VERSION ""

NS_ :

BS_:

BU_: SGW RFHM MPAD IPC GNMM EVCU2 ESL ECM DTCM DMSM BSM BCM AGSM ADCAM

BO_ 1426 VDCM_HMI: 32 EVCU2
 SG_ VDCM_PopUpMessage5 : 55|3@0+ (1,0) [0|6] "" IPC
 SG_ EstRange : 18|11@0+ (1,0) [0|2046] "km"  SGW,IPC
 SG_ DC_EstChargeTime2 : 103|8@0+ (1,0) [0|254] "min"  SGW,IPC
 SG_ DC_EstChargeTime1 : 47|8@0+ (1,0) [0|254] "min"  SGW,IPC
 SG_ VDCM_PopUpMessage7 : 87|1@0+ (1,0) [0|1] "" IPC
 SG_ Est_Range_ChrgStopTime : 162|11@0+ (1,0) [0|2046] "km"  SGW
 SG_ Est_HVBatSOC_VDCM : 159|8@0+ (0.3922,0) [0|99.6188] "%"  SGW
 SG_ ServiceHVError : 126|1@0+ (1,0) [0|1] "" IPC
 SG_ ThermalRunaway_Alert : 107|1@0+ (1,0) [0|1] "" Vector__XXX
 SG_ MessageCounter_VDCM_HMI : 179|4@0+ (1,0) [0|15] "-"  IPC
 SG_ CRC_VDCM_HMI : 191|8@0+ (1,0) [0|255] "-"  IPC
 SG_ BatteryRunaway_Lamp_PT : 108|1@0+ (1,0) [0|1] "" BCM,IPC

BO_ 1853 HYBRID_RM_MOTORS_2: 32 EVCU2
 SG_ APM_OutputPower : 119|10@0+ (3,0) [0|3069] "W"  SGW
 SG_ APM_FailureReason : 151|6@0+ (1,0) [0|63] "" SGW
 SG_ APM_CtrlSts_Fbk : 145|4@0+ (1,0) [0|15] "" SGW

BO_ 1439 AFLM_A1: 32 BCM
 SG_ AFLM_Fault : 15|1@0+ (1,0) [0|1] "-"  IPC

BO_ 126 GLIWA_MCPA_RX: 8 SGW
 SG_ N_PDU : 7|64@0+ (1,0) [0|0] "" EVCU2

BO_ 123 GLIWA_MCPA_TX: 8 EVCU2
 SG_ N_PDU : 7|64@0+ (1,0) [0|0] "" SGW

BO_ 127 GLIWA_MCPB_RX: 8 SGW
 SG_ N_PDU : 7|64@0+ (1,0) [0|0] "" EVCU2

BO_ 124 GLIWA_MCPB_TX: 8 EVCU2
 SG_ N_PDU : 7|64@0+ (1,0) [0|0] "" SGW

BO_ 834 GLIWA_T1_TX: 8 ECM
 SG_ N_PDU : 7|64@0+ (1,0) [0|0] "" SGW

BO_ 835 GLIWA_T1_RX: 8 SGW
 SG_ N_PDU : 7|64@0+ (1,0) [0|0] "" ECM,EVCU2

BO_ 1462 CLIMATE_SCHEDULE_TBM: 32 SGW
 SG_ TBM_Submit_ClimateSchd2 : 4|1@0+ (1,0) [0|1] "-"  EVCU2
 SG_ TBM_Submit_ClimateSchd1 : 5|1@0+ (1,0) [0|1] "-"  EVCU2
 SG_ TBM_Enable_ClimateSchd2 : 6|1@0+ (1,0) [0|0] "-"  EVCU2
 SG_ TBM_Enable_ClimateSchd1 : 7|1@0+ (1,0) [0|0] "-"  EVCU2
 SG_ TBM_ClimateSchd2_Departure_Min : 11|4@0+ (5,0) [0|70] "min"  EVCU2
 SG_ TBM_ClimateSchd2_Departure_Hr : 31|5@0+ (1,0) [0|30] "Hours"  EVCU2
 SG_ TBM_ClimateSchd2_Day : 55|8@0+ (1,0) [0|254] "-"  EVCU2
 SG_ TBM_ClimateSchd1_Departure_Min : 15|4@0+ (5,0) [0|70] "min"  EVCU2
 SG_ TBM_ClimateSchd1_Departure_Hr : 23|5@0+ (1,0) [0|30] "Hours"  EVCU2
 SG_ TBM_ClimateSchd1_Day : 47|8@0+ (1,0) [0|254] "-"  EVCU2
 SG_ TBM_AllowClimateSchd2 : 1|2@0+ (1,0) [0|2] "-"  EVCU2
 SG_ TBM_AllowClimateSchd1 : 3|2@0+ (1,0) [0|2] "-"  EVCU2
 SG_ Climate_TBM_Cabin_Temp2 : 71|5@0+ (0.5,16) [16|31] "°C"  EVCU2
 SG_ Climate_TBM_Cabin_Temp1 : 39|5@0+ (0.5,16) [16|31] "°C"  EVCU2

BO_ 1471 CLIMATE_SCHEDULE_HU1: 32 SGW
 SG_ Submit_ClimateSchd2 : 4|1@0+ (1,0) [0|1] "-"  EVCU2
 SG_ Submit_ClimateSchd1 : 5|1@0+ (1,0) [0|1] "-"  EVCU2
 SG_ Enable_ClimateSchd2 : 6|1@0+ (1,0) [0|1] "-"  EVCU2
 SG_ Enable_ClimateSchd1 : 7|1@0+ (1,0) [0|1] "-"  EVCU2
 SG_ ClimateSchd2_Departure_Min : 11|4@0+ (5,0) [0|70] "min"  EVCU2
 SG_ ClimateSchd2_Departure_Hr : 31|5@0+ (1,0) [0|30] "Hours"  EVCU2
 SG_ ClimateSchd2_Day : 55|8@0+ (1,0) [0|254] "-"  EVCU2
 SG_ ClimateSchd1_Departure_Min : 15|4@0+ (5,0) [0|70] "min"  EVCU2
 SG_ ClimateSchd1_Departure_Hr : 23|5@0+ (1,0) [0|30] "Hours"  EVCU2
 SG_ ClimateSchd1_Day : 47|8@0+ (1,0) [0|254] "-"  EVCU2
 SG_ Climate_Cabin_Temp2 : 63|5@0+ (0.5,16) [16|31] "°C"  EVCU2
 SG_ Climate_Cabin_Temp1 : 39|5@0+ (0.5,16) [16|31] "°C"  EVCU2
 SG_ AllowClimateSchd2 : 1|2@0+ (1,0) [0|2] "-"  EVCU2
 SG_ AllowClimateSchd1 : 3|2@0+ (1,0) [0|2] "-"  EVCU2

BO_ 1468 CLIMATE_SCHEDULE_HCP1: 32 EVCU2
 SG_ Enable_ClimateSchd2_Sts : 6|1@0+ (1,0) [0|1] "-"  SGW
 SG_ Enable_ClimateSchd1_Sts : 7|1@0+ (1,0) [0|1] "-"  SGW
 SG_ ClimateSchd2_Departure_Min_Sts : 11|4@0+ (5,0) [0|70] "min"  SGW
 SG_ ClimateSchd2_Departure_Hr_Sts : 31|5@0+ (1,0) [0|30] "Hours"  SGW
 SG_ ClimateSchd2_Day_Sts : 55|8@0+ (1,0) [0|254] "-"  SGW
 SG_ ClimateSchd1_Departure_Min_Sts : 15|4@0+ (5,0) [0|70] "min"  SGW
 SG_ ClimateSchd1_Departure_Hr_Sts : 23|5@0+ (1,0) [0|30] "Hours"  SGW
 SG_ ClimateSchd1_Day_Sts : 47|8@0+ (1,0) [0|254] "-"  SGW
 SG_ Climate_Cabin_Temp2_Sts : 63|5@0+ (0.5,16) [16|31] "°C"  SGW
 SG_ Climate_Cabin_Temp1_Sts : 39|5@0+ (0.5,16) [16|31] "°C"  SGW
 SG_ AllowClimateSchd2_Sts : 1|2@0+ (1,0) [0|2] "-"  SGW
 SG_ AllowClimateSchd1_Sts : 3|2@0+ (1,0) [0|2] "-"  SGW

BO_ 105 VDCM_PWT3: 64 EVCU2
 SG_ T4_Sensor_Temp : 378|11@0+ (0.1,-40) [-40|164.7] "°C"  BCM
 SG_ LidOpeningAck : 7|2@0+ (1,0) [0|2] "" Vector__XXX
 SG_ LidClosingAck : 5|2@0+ (1,0) [0|2] "" Vector__XXX
 SG_ MessageCounter_VDCM_PWT3 : 435|4@0+ (1,0) [0|15] "-"  DTCM
 SG_ CRC_VDCM_PWT3 : 447|8@0+ (1,0) [0|255] "-"  DTCM

BO_ 1442 VDCM_HMI2: 64 EVCU2
 SG_ SugSpeedThreshold : 51|6@0+ (5,0) [0|315] "km/h"  Vector__XXX
 SG_ SugSpeedMin : 41|6@0+ (5,0) [0|315] "km/h"  Vector__XXX
 SG_ SugSpeedMax : 47|6@0+ (5,0) [0|315] "km/h"  Vector__XXX
 SG_ AC_Charge_Button_Label5 : 93|8@0+ (0.1,0) [0|25.5] "kW"  Vector__XXX
 SG_ AC_Charge_Button_Label4 : 85|8@0+ (0.1,0) [0|25.5] "kW"  Vector__XXX
 SG_ AC_Charge_Button_Label3 : 77|8@0+ (0.1,0) [0|25.5] "kW"  Vector__XXX
 SG_ AC_Charge_Button_Label2 : 69|8@0+ (0.1,0) [0|25.5] "kW"  Vector__XXX
 SG_ AC_Charge_Button_Label1 : 61|8@0+ (0.1,0) [0|25.5] "kW"  Vector__XXX

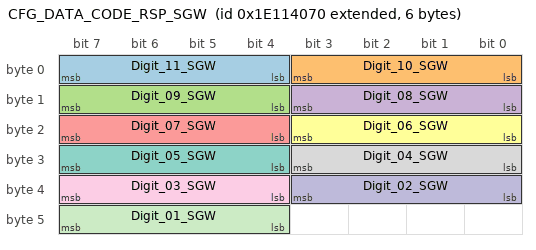
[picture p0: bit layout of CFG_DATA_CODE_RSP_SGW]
BO_ 2651930736 CFG_DATA_CODE_RSP_SGW: 6 SGW
 SG_ Digit_11_SGW : 7|4@0+ (1,0) [0|15] "-"  BCM
 SG_ Digit_10_SGW : 3|4@0+ (1,0) [0|15] "-"  BCM
 SG_ Digit_09_SGW : 15|4@0+ (1,0) [0|15] "-"  BCM
 SG_ Digit_08_SGW : 11|4@0+ (1,0) [0|15] "-"  BCM
 SG_ Digit_07_SGW : 23|4@0+ (1,0) [0|15] "-"  BCM
 SG_ Digit_06_SGW : 19|4@0+ (1,0) [0|15] "-"  BCM
 SG_ Digit_05_SGW : 31|4@0+ (1,0) [0|15] "-"  BCM
 SG_ Digit_04_SGW : 27|4@0+ (1,0) [0|15] "-"  BCM
 SG_ Digit_03_SGW : 39|4@0+ (1,0) [0|15] "-"  BCM
 SG_ Digit_02_SGW : 35|4@0+ (1,0) [0|15] "-"  BCM
 SG_ Digit_01_SGW : 47|4@0+ (1,0) [0|15] "-"  BCM

BO_ 2654339257 PDC_INFO_FD_WCPM2: 12 RFHM
 SG_ WakeupSource_FD09_WCPM2 : 23|8@0+ (1,0) [0|255] "" SGW
 SG_ PreviousCanNMState_FD09_WCPM2 : 11|4@0+ (1,0) [0|15] "" SGW
 SG_ GenericFailSts_FD09_WCPM2 : 5|1@0+ (1,0) [0|1] "" SGW,BCM
 SG_ EOL_FD09_WCPM2 : 7|1@0+ (1,0) [0|1] "-"  SGW,BCM
 SG_ DES_FD09_WCPM2 : 4|2@0+ (1,0) [0|3] "" SGW
 SG_ CurrentFailSts_FD09_WCPM2 : 6|1@0+ (1,0) [0|1] "" SGW,BCM
 SG_ CurrentCanNMState_FD09_WCPM2 : 15|4@0+ (1,0) [0|15] "" SGW
 SG_ StayActiveSource_FD09_WCPM2 : 31|64@0+ (1,0) [0|18446744073709551615] "" SGW

BO_ 1474 IPC_VEHICLE_SETUP2: 48 IPC
 SG_ TSI_Offset_Mph : 19|4@0+ (1,0) [0|15] "" SGW,BCM,IPC
 SG_ TSI_Offset_Kph : 31|4@0+ (1,0) [0|15] "" SGW,BCM,IPC
 SG_ ParkSenseSignalView : 37|1@0+ (1,0) [0|1] "" SGW,BCM
 SG_ FOA_Alert_Type : 6|2@0+ (1,0) [0|3] "" SGW,BCM
 SG_ TurnSignalView : 34|2@0+ (1,0) [0|3] "" SGW,BCM
 SG_ Fuel_Saver_Display : 26|1@0+ (1,0) [0|1] "" SGW,BCM
 SG_ EPB_Service_Mode : 39|1@0+ (1,0) [0|1] "" SGW,BCM
 SG_ Creep : 64|1@0+ (1,0) [0|1] "" EVCU2,SGW,BCM,IPC
 SG_ StopOnTraffic : 70|2@0+ (1,0) [0|2] "" MPAD,SGW,BCM
 SG_ SpeedAdjust : 71|1@0+ (1,0) [0|1] "" SGW,BCM
 SG_ RouteGuidance : 58|1@0+ (1,0) [0|1] "" MPAD,SGW,BCM
 SG_ EmergencyCorridorAssist : 67|1@0+ (1,0) [0|1] "" MPAD,SGW,BCM
 SG_ SpeedLimitAdjust : 76|2@0+ (1,0) [0|3] "" MPAD,SGW,BCM
 SG_ AssistedLaneChange : 78|2@0+ (1,0) [0|3] "" MPAD,SGW,BCM

BO_ 2564682099 DIAGNOSTIC_ROE_WCPM2: 8 RFHM
 SG_ N_PDU : 7|64@0+ (1,0) [0|0] "" SGW

BO_ 2564682355 DIAGNOSTIC_ROE_FD_WCPM2: 64 RFHM
 SG_ N_PDU : 7|64@0+ (1,0) [0|0] "" SGW

BO_ 2564485491 DIAGNOSTIC_RESPONSE_WCPM2: 8 RFHM
 SG_ N_PDU : 7|64@0+ (1,0) [0|0] "" SGW

BO_ 2564485747 DIAGNOSTIC_RESPONSE_FD_WCPM2: 64 RFHM
 SG_ N_PDU : 7|64@0+ (1,0) [0|0] "" SGW

BO_ 2564453361 DIAGNOSTIC_REQUEST_WCPM2: 8 SGW
 SG_ N_PDU : 7|64@0+ (1,0) [0|0] "" RFHM

BO_ 2564453362 DIAGNOSTIC_REQUEST_FD_WCPM2: 64 SGW
 SG_ N_PDU : 7|64@0+ (1,0) [0|0] "" RFHM

BO_ 1440 TELEMATIC_FD_13: 32 SGW
 SG_ ETM_HUD_Zone5_Expanded : 39|6@0+ (1,0) [0|62] "-"  IPC
 SG_ ETM_HUD_Zone4_Expanded : 31|6@0+ (1,0) [0|62] "-"  IPC
 SG_ ETM_HUD_Zone3_Expanded : 23|6@0+ (1,0) [0|62] "-"  IPC
 SG_ ETM_HUD_Zone2_Expanded : 15|6@0+ (1,0) [0|62] "-"  IPC
 SG_ ETM_HUD_Zone1_Expanded : 7|6@0+ (1,0) [0|62] "-"  IPC
 SG_ AUD_LVL : 103|8@0+ (1,0) [0|38] "levels"  EVCU2

BO_ 2564554485 DIAGNOSTIC_REQUEST_FUNC_FOTA: 64 SGW
 SG_ N_PDU : 7|64@0+ (1,0) [0|0] "" ADCAM,MPAD,DMSM,GNMM,AGSM,ESL,BCM,BSM,IPC,RFHM,DTCM

BO_ 1316 ADCM_FD_A3: 20 BCM
 SG_ OffRd_RR_Lvl : 48|9@0+ (1,-255) [-255|255] "mm"  IPC
 SG_ OffRd_RL_Lvl : 32|9@0+ (1,-255) [-255|255] "mm"  IPC
 SG_ OffRd_FR_Lvl : 16|9@0+ (1,-255) [-255|255] "mm"  IPC
 SG_ OffRd_FL_Lvl : 0|9@0+ (1,-255) [-255|255] "mm"  IPC

BO_ 205 BRAKE_FD_6: 64 BSM
 SG_ CRC_BRAKE_FD_6 : 447|8@0+ (1,0) [0|255] "-"  MPAD,EVCU2
 SG_ MessageCounter_BRAKE_FD_6 : 435|4@0+ (1,0) [0|15] "-"  MPAD,EVCU2
 SG_ RearAxle_Min_Rq_BSM : 52|1@0+ (1,0) [0|1] "" EVCU2
 SG_ RearAxle_Max_Rq_BSM : 53|1@0+ (1,0) [0|1] "" EVCU2
 SG_ FrontAxle_Min_Rq_BSM : 54|1@0+ (1,0) [0|1] "" EVCU2
 SG_ FrontAxle_Max_Rq_BSM : 55|1@0+ (1,0) [0|1] "" EVCU2
 SG_ TotalAxle_Min_Rq_BSM : 50|1@0+ (1,0) [0|1] "" EVCU2
 SG_ TotalAxle_Max_Rq_BSM : 51|1@0+ (1,0) [0|1] "" EVCU2,DTCM
 SG_ Regen_AxleTorque_Req : 110|15@0+ (2,0) [0|65532] "Nm"  EVCU2
 SG_ DrvrIntd_TotalBrk_AxleTorq : 142|15@0+ (2,0) [0|65532] "Nm"  EVCU2
 SG_ DriverReq_AxleTrq_Enabled_BSM : 175|4@0+ (1,0) [0|15] "" EVCU2
 SG_ Cmnd_TotBrkFrict_AxleTorq : 126|15@0+ (2,0) [0|65532] "Nm"  EVCU2
 SG_ TotalAxle_Rq_BSM : 95|16@0+ (2,-65534) [-65534|65536] "Nm"  EVCU2,DTCM
 SG_ DriverRequested_AxleTrq_BSM : 159|16@0+ (2,-65534) [-65534|65536] "Nm"  EVCU2
 SG_ RearAxle_Rq_BSM : 79|16@0+ (2,-65534) [-65534|65536] "Nm"  EVCU2
 SG_ FrontAxle_Rq_BSM : 63|16@0+ (2,-65534) [-65534|65536] "Nm"  EVCU2
 SG_ WED_MODE_RQ : 47|2@0+ (1,0) [0|3] "" EVCU2
 SG_ OPD_Hold_Status : 49|2@0+ (1,0) [0|3] "" EVCU2

BO_ 204 AXLE_TORQUE_FD_1: 48 EVCU2
 SG_ MessageCounter_AXLE_TORQUE_FD_1 : 307|4@0+ (1,0) [0|15] "-"  DTCM
 SG_ CRC_AXLE_TORQUE_FD_1 : 319|8@0+ (1,0) [0|255] "-"  DTCM
 SG_ Rear_Axle_Regen_Capacity : 197|14@0+ (2,0) [0|32764] "Nm"  BSM
 SG_ Rear_Axle_Est_Regen_Torq : 181|14@0+ (2,0) [0|32764] "Nm"  BSM
 SG_ Front_Axle_Regen_Capacity : 165|14@0+ (2,0) [0|32764] "Nm"  BSM
 SG_ Front_Axle_Est_Regen_Torq : 149|14@0+ (2,0) [0|32764] "Nm"  BSM
 SG_ Total_AxleTorque_Min : 23|16@0+ (2,-65534) [-65534|65536] "Nm"  BSM,DTCM
 SG_ Total_AxleTorque_Max : 7|16@0+ (2,-65534) [-65534|65536] "Nm"  BCM,BSM,DTCM
 SG_ Axle_TorqueStatic_D_TTC : 39|16@0+ (2,-65534) [-65534|65536] "Nm"  BCM,BSM,DTCM
 SG_ Axle_Torque_DrvReqMod : 55|16@0+ (2,-65534) [-65534|65536] "Nm"  BCM,BSM,DTCM
 SG_ Rear_AxleTorque_Min : 119|16@0+ (2,-65534) [-65534|65536] "Nm"  SGW,BSM
 SG_ Rear_AxleTorque_Max : 103|16@0+ (2,-65534) [-65534|65536] "Nm"  SGW,BSM
 SG_ MaxRegen_Diff_Axle_Torq_Active : 135|1@0+ (1,0) [0|1] "" BSM
 SG_ MaxRegen_Diff_Axle_Torq : 134|15@0+ (2,0) [0|65532] "Nm"  BSM
 SG_ Front_AxleTorque_Min : 87|16@0+ (2,-65534) [-65534|65536] "Nm"  SGW,BSM
 SG_ Front_AxleTorque_Max : 71|16@0+ (2,-65534) [-65534|65536] "Nm"  SGW,BSM

BO_ 1478 TPM_FD_1: 32 SGW
 SG_ MessageCounter_TPM1 : 179|4@0+ (1,0) [0|15] "-"  IPC
 SG_ CRC_TPM1 : 191|8@0+ (1,0) [0|255] "-"  IPC

BO_ 125 MESS_TTPM1: 32 RFHM
 SG_ MESS_TTPM1 : 7|64@0+ (1,0) [0|0] "" SGW

BO_TX_BU_ 834 : ECM,EVCU2;
CM_ SG_ 1426 Est_HVBatSOC_VDCM "Estimated HV battery State of Charge (SOC) at the scheduled charge cycle stop time";
CM_ SG_ 1426 Est_Range_ChrgStopTime "Estimated EV range at the scheduled charge cycle stop time (based on SOC)";
CM_ SG_ 1426 EstRange "Estimated range due to HV battery";
CM_ SG_ 1426 MessageCounter_VDCM_HMI "This signal is a counter used for safety checks strategies. This counter is incremented of 1 (one) unit at each frame transmission.";
CM_ SG_ 1426 ServiceHVError "In Service Procedure this signal activates a warning indication on the IPC during HV System Deactivation";
CM_ SG_ 1426 ThermalRunaway_Alert "Thermal runaway alert activation for non-driving conditions";
CM_ SG_ 1426 VDCM_PopUpMessage5 "VDCM Popup5";
CM_ SG_ 1426 VDCM_PopUpMessage7 "Request to keep the vehicle plugged";
CM_ SG_ 1426 BatteryRunaway_Lamp_PT "Thermal Runaway Indication";
CM_ SG_ 1426 CRC_VDCM_HMI "CRC according to SAE J1850 standard at each frame transmission.";
CM_ SG_ 1426 DC_EstChargeTime1 "DC remaining Charging time 1";
CM_ SG_ 1426 DC_EstChargeTime2 "DC remaining Charging time 2";
CM_ SG_ 1853 APM_OutputPower "APM Output Power";
CM_ SG_ 1853 APM_FailureReason "FailureReason";
CM_ SG_ 1853 APM_CtrlSts_Fbk "This signal indicates the DC-DC feedback mode.";
CM_ SG_ 1439 AFLM_Fault "AFLM_Fault";
CM_ SG_ 834 N_PDU "This signal is used for diagnostic purposes";
CM_ SG_ 835 N_PDU "This signal is used for diagnostic purposes";
CM_ SG_ 1462 Climate_TBM_Cabin_Temp1 "Schedule1 cabin temperature";
CM_ SG_ 1462 Climate_TBM_Cabin_Temp2 "Schedule1 cabin temperature";
CM_ SG_ 1462 TBM_AllowClimateSchd1 "Climate Scheduling1 Options";
CM_ SG_ 1462 TBM_Enable_ClimateSchd2 "Climate Schedule2 checkbox enabled";
CM_ SG_ 1462 TBM_Submit_ClimateSchd1 "Climate Schedule 1 submitted";
CM_ SG_ 1462 TBM_AllowClimateSchd2 "Climate Scheduling2 Options";
CM_ SG_ 1462 TBM_ClimateSchd1_Day "Schedule#1 Day for Cabin conditioning";
CM_ SG_ 1462 TBM_ClimateSchd1_Departure_Hr "Departure time of schedule 1 (hours in 24 hrs. format)";
CM_ SG_ 1462 TBM_ClimateSchd1_Departure_Min "Departure time of schedule 1(Minutes)";
CM_ SG_ 1462 TBM_ClimateSchd2_Day "Schedule#2 Day for Cabin conditioning";
CM_ SG_ 1462 TBM_ClimateSchd2_Departure_Hr "Departure time of schedule 2 (hours in 24 hrs. format)";
CM_ SG_ 1462 TBM_ClimateSchd2_Departure_Min "Departure time of schedule 2(Minutes)";
CM_ SG_ 1462 TBM_Enable_ClimateSchd1 "Climate Schedule1 checkbox enabled";
CM_ SG_ 1462 TBM_Submit_ClimateSchd2 "Climate Schedule 2 submitted";
CM_ SG_ 1471 AllowClimateSchd2 "Climate Scheduling2 Options";
CM_ SG_ 1471 Climate_Cabin_Temp1 "Schedule1 cabin temperature";
CM_ SG_ 1471 Climate_Cabin_Temp2 "Schedule2 cabin temperature";
CM_ SG_ 1471 ClimateSchd1_Day "Schedule#1 Day for cabin conditioning";
CM_ SG_ 1471 ClimateSchd1_Departure_Hr "Departure time of schedule 1 (hours in 24 hrs. format)";
CM_ SG_ 1471 ClimateSchd1_Departure_Min "Departure time of schedule 1(Minutes)";
CM_ SG_ 1471 ClimateSchd2_Day "Scheduled#2 Day for cabin conditioning";
CM_ SG_ 1471 ClimateSchd2_Departure_Hr "Departure time of schedule 2 (hours in 24 hrs. format)";
CM_ SG_ 1471 ClimateSchd2_Departure_Min "Departure time of schedule 2(Minutes)";
CM_ SG_ 1471 Enable_ClimateSchd1 "Climate Schedule 1 checkbox enabled";
CM_ SG_ 1471 Enable_ClimateSchd2 "Climate Schedule 2 checkbox enabled";
CM_ SG_ 1471 Submit_ClimateSchd1 "Climate Schedule 1 submitted";
CM_ SG_ 1471 Submit_ClimateSchd2 "Climate Schedule 2 submitted";
CM_ SG_ 1471 AllowClimateSchd1 "Climate Scheduling1 Options";
CM_ SG_ 1468 AllowClimateSchd1_Sts "Climate Scheduling1 Options";
CM_ SG_ 1468 AllowClimateSchd2_Sts "Climate Scheduling2 Options";
CM_ SG_ 1468 Climate_Cabin_Temp1_Sts "Schedule1 cabin temperature";
CM_ SG_ 1468 Climate_Cabin_Temp2_Sts "Schedule1 cabin temperature";
CM_ SG_ 1468 ClimateSchd1_Day_Sts "Scheduled#1 Day for cabin conditioning confirmation";
CM_ SG_ 1468 ClimateSchd1_Departure_Hr_Sts "Departure time of schedule 1 (hours in 24 hrs. format)";
CM_ SG_ 1468 ClimateSchd1_Departure_Min_Sts "Departure time of schedule 1(Minutes)";
CM_ SG_ 1468 ClimateSchd2_Day_Sts "Scheduled#2 Day for cabin conditioning confirmation";
CM_ SG_ 1468 ClimateSchd2_Departure_Hr_Sts "Departure time of schedule 2 (hours in 24 hrs. format)";
CM_ SG_ 1468 ClimateSchd2_Departure_Min_Sts "Departure time of schedule 2(Minutes)";
CM_ SG_ 1468 Enable_ClimateSchd1_Sts "Climate Schedule 1 checkbox enable status";
CM_ SG_ 1468 Enable_ClimateSchd2_Sts "Climate Schedule 2 checkbox enable status";
CM_ SG_ 105 CRC_VDCM_PWT3 "CRC according to SAE J1850 standard at each frame transmission.";
CM_ SG_ 105 LidClosingAck "Ack of e-Lid closing perfomed by VDCM";
CM_ SG_ 105 LidOpeningAck "Ack of e-Lid opening perfomed by VDCM";
CM_ SG_ 105 MessageCounter_VDCM_PWT3 "This signal is a counter used for safety checks strategies. This counter is incremented of 1 (one) unit at each frame transmission.";
CM_ SG_ 105 T4_Sensor_Temp "T4 Temperature sensor";
CM_ SG_ 1442 AC_Charge_Button_Label5 "AC Level 5 Power displayed on the head unit.";
CM_ SG_ 1442 AC_Charge_Button_Label1 "AC Level 1 Power displayed on the head unit.";
CM_ SG_ 1442 AC_Charge_Button_Label2 "AC Level 2 Power displayed on the head unit.";
CM_ SG_ 1442 AC_Charge_Button_Label3 "AC Level 3 Power displayed on the head unit.";
CM_ SG_ 1442 AC_Charge_Button_Label4 "AC Level 4 Power displayed on the head unit.";
CM_ SG_ 1442 SugSpeedMax "Suggested Speed Limit upper boundary";
CM_ SG_ 1442 SugSpeedMin "Suggested Speed Limit lower boundary";
CM_ SG_ 1442 SugSpeedThreshold "Suggested Speed Limit shade boundary";
CM_ SG_ 2654339257 CurrentCanNMState_FD09_WCPM2 "Indicates that CanNM state the ECU is currently executing";
CM_ SG_ 2654339257 CurrentFailSts_FD09_WCPM2 "Indicates the presence/absence of at least one DTC with DTCStatus = present in the System Memory";
CM_ SG_ 2654339257 DES_FD09_WCPM2 "Indicates whether the ECU?s CAN cell is in either ErrorActive, or ErrorPassive state OR has just now recovered from a BusOff condition";
CM_ SG_ 2654339257 EOL_FD09_WCPM2 "Indicates if the ECU requires configuration data at the assembly plant End Of Line";
CM_ SG_ 2654339257 GenericFailSts_FD09_WCPM2 "Indicates the presence/absent of at least one DTC in the System Memory";
CM_ SG_ 2654339257 PreviousCanNMState_FD09_WCPM2 "Indicates the last CanNM state that the ECU existed in";
CM_ SG_ 2654339257 WakeupSource_FD09_WCPM2 "Indicates the reason the ECU was most recently awakened";
CM_ SG_ 2654339257 StayActiveSource_FD09_WCPM2 "Indicates the source that requests the ECU to stay active";
CM_ SG_ 1474 AssistedLaneChange "L2+ Feature for Assisted Lane Change";
CM_ SG_ 1474 Creep "Customer Setting - Creep feature";
CM_ SG_ 1474 EmergencyCorridorAssist "Customer Setting - Emergency Corridor Assist";
CM_ SG_ 1474 EPB_Service_Mode "EPB service mode; Service mode = [1";
CM_ SG_ 1474 FOA_Alert_Type "Forgotten Object Alert Type";
CM_ SG_ 1474 Fuel_Saver_Display "Fuel saver display indicator status (1=enabled)";
CM_ SG_ 1474 ParkSenseSignalView "ParkSense Based Camera Activation settings";
CM_ SG_ 1474 SpeedAdjust "Customer Setting - Speed Adjust";
CM_ SG_ 1474 RouteGuidance "Customer Setting - Route Guidance";
CM_ SG_ 1474 TSI_Offset_Kph "TSI_Offset_Kph";
CM_ SG_ 1474 SpeedLimitAdjust "L2+ Feature for Speed Limit Adjust";
CM_ SG_ 1474 StopOnTraffic "Customer Setting - Stop on Traffic";
CM_ SG_ 1474 TSI_Offset_Mph "TSI_Offset_Mph";
CM_ SG_ 1474 TurnSignalView "Turn Signal Activated Blind Spot Camera View with and without Trailer Options";
CM_ SG_ 2564682099 N_PDU "This signal is used for diagnostic purposes";
CM_ SG_ 2564682355 N_PDU "This signal is used for diagnostic purposes";
CM_ SG_ 2564485491 N_PDU "This signal is used for diagnostic purposes";
CM_ SG_ 2564485747 N_PDU "This signal is used for diagnostic purposes";
CM_ SG_ 2564453361 N_PDU "This signal is used for diagnostic purposes";
CM_ SG_ 2564453362 N_PDU "This signal is used for diagnostic purposes";
CM_ SG_ 1440 ETM_HUD_Zone5_Expanded "Configurable HUD zone area 5";
CM_ SG_ 1440 ETM_HUD_Zone4_Expanded "Configurable HUD zone area 4";
CM_ SG_ 1440 ETM_HUD_Zone3_Expanded "Configurable HUD zone area 3";
CM_ SG_ 1440 ETM_HUD_Zone2_Expanded "Configurable HUD zone area 2";
CM_ SG_ 1440 ETM_HUD_Zone1_Expanded "Configurable HUD zone area 1";
CM_ SG_ 1440 AUD_LVL "Audio level";
CM_ SG_ 2564554485 N_PDU "This signal is used for diagnostic purposes";
CM_ SG_ 1316 OffRd_FL_Lvl "Damping Front Left Level";
CM_ SG_ 1316 OffRd_FR_Lvl "Damping Front Right Level";
CM_ SG_ 1316 OffRd_RL_Lvl "Damping Rear Left Level";
CM_ SG_ 1316 OffRd_RR_Lvl "Damping Rear Right Level";
CM_ SG_ 205 WED_MODE_RQ "WED Requested Center Differential State";
CM_ SG_ 205 TotalAxle_Rq_BSM "Combined axle traction torque request";
CM_ SG_ 205 TotalAxle_Min_Rq_BSM "Combined axle traction torque min limit flag. Active = [1]";
CM_ SG_ 205 TotalAxle_Max_Rq_BSM "Combined axle traction torque max limit flag. Active = [1]";
CM_ SG_ 205 Regen_AxleTorque_Req "Regenerative Braking Torque request in Axle domain";
CM_ SG_ 205 RearAxle_Rq_BSM "Rear axle traction control torque request";
CM_ SG_ 205 RearAxle_Min_Rq_BSM "Rear axle traction torque min limit  flag. Active = [1]";
CM_ SG_ 205 RearAxle_Max_Rq_BSM "Rear axle traction torque max limit  flag. Active = [1]";
CM_ SG_ 205 OPD_Hold_Status "Hold status from the brake controller in One Pedal Drive";
CM_ SG_ 205 MessageCounter_BRAKE_FD_6 "This signal is a counter used for safety checks strategies. This counter is incremented of 1 (one) unit at each frame transmission.";
CM_ SG_ 205 FrontAxle_Rq_BSM "Front axle traction control torque request";
CM_ SG_ 205 FrontAxle_Min_Rq_BSM "Front axle traction torque min limit flag. Active = [1]";
CM_ SG_ 205 FrontAxle_Max_Rq_BSM "Front axle traction torque max limit flag. Active = [1]";
CM_ SG_ 205 DrvrIntd_TotalBrk_AxleTorq "Total Brake Torque in Axle domain";
CM_ SG_ 205 DriverRequested_AxleTrq_BSM "Virtual driver torque request from BSM";
CM_ SG_ 205 DriverReq_AxleTrq_Enabled_BSM "It indicates the request to enable virtual driver torque interface for BSM driver functions";
CM_ SG_ 205 CRC_BRAKE_FD_6 "CRC according to SAE J1850 standard at each frame transmission.";
CM_ SG_ 205 Cmnd_TotBrkFrict_AxleTorq "Commanded Total Brake Friction torque in Axle domain";
CM_ SG_ 204 Axle_Torque_DrvReqMod "Driver requested Axle torque raw (no torque shaping)";
CM_ SG_ 204 Axle_TorqueStatic_D_TTC "Driver requested Axle torque (filtered/ torque shaped)";
CM_ SG_ 204 CRC_AXLE_TORQUE_FD_1 "CRC according to SAE J1850 standard at each frame transmission.";
CM_ SG_ 204 MaxRegen_Diff_Axle_Torq_Active "Max Regen torque request; Active = [1]";
CM_ SG_ 204 MaxRegen_Diff_Axle_Torq "Difference between Max Regen and normal coasting torques";
CM_ SG_ 204 Front_AxleTorque_Min "Minimum front Axle torque";
CM_ SG_ 204 Front_AxleTorque_Max "Maximum front Axle torque";
CM_ SG_ 204 Front_Axle_Regen_Capacity "Regenerative Braking front Axle Torque Capability";
CM_ SG_ 204 Front_Axle_Est_Regen_Torq "Estimated regen Braking Torque at the Front axle";
CM_ SG_ 204 Total_AxleTorque_Min "Minimum total Axle torque";
CM_ SG_ 204 Total_AxleTorque_Max "Maximum total Axle torque";
CM_ SG_ 204 Rear_AxleTorque_Min "Minimum rear Axle torque";
CM_ SG_ 204 Rear_AxleTorque_Max "Maximum rear Axle torque";
CM_ SG_ 204 Rear_Axle_Regen_Capacity "Regenerative Braking rear Axle Torque Capability";
CM_ SG_ 204 Rear_Axle_Est_Regen_Torq "Estimated regen Braking Torque at the Rear axle";
CM_ SG_ 204 MessageCounter_AXLE_TORQUE_FD_1 "This signal is a counter used for safety checks strategies. This counter is incremented of 1 (one) unit at each frame transmission.";
CM_ SG_ 1478 MessageCounter_TPM1 "This signal is a counter used for safety checks strategies. This counter is incremented of 1 (one) unit at each frame transmission.";
CM_ SG_ 1478 CRC_TPM1 "CRC according to SAE J1850 standard at each frame transmission.";
CM_ SG_ 125 MESS_TTPM1 "Measurement data";
BA_DEF_ BO_ "CANFD_BRS" ENUM "0","1";
BA_DEF_ BO_ "VFrameFormat" ENUM "StandardCAN","ExtendedCAN","reserved","reserved","reserved","reserved","reserved","reserved","reserved","reserved","reserved","reserved","reserved","reserved","StandardCAN_FD","ExtendedCAN_FD";
BA_DEF_ BO_ "DiagConnection" HEX 0 65535;
BA_DEF_ BO_ "DiagState" ENUM "No","Yes";
BA_DEF_ BO_ "NmAsrMessage" ENUM "No","Yes";
BA_DEF_ BO_ "GenMsgDelayTime" INT 0 65535;
BA_DEF_ BO_ "GenMsgCycleTime" INT 0 65535;
BA_DEF_ BO_ "GenMsgCycleTimeFast" INT 0 65535;
BA_DEF_ BO_ "GenMsgStartDelayTime" INT 0 65535;
BA_DEF_ BO_ "GenMsgILSupport" ENUM "No","Yes";
BA_DEF_ BO_ "GenMsgNrOfRepetition" INT 0 255;
BA_DEF_ BO_ "GenMsgSendType" ENUM "Cyclic","NotUsed","NotUsed","NotUsed","NotUsed","NotUsed","NotUsed","NotUsed","NoMsgSendType";
BA_DEF_ BO_ "NmMessage" ENUM "No","Yes";
BA_DEF_ BO_ "DiagResponse" ENUM "No","Yes";
BA_DEF_ BO_ "Type" ENUM "P","C","PE","COC","PE_Cntrl","E","E_Cntrl","OC","S","BAF","DC","EM","MM","ISO-TP","-";
BA_DEF_ BO_ "DiagRequest" ENUM "No","Yes";
BA_DEF_ SG_ "GenSigTimeoutTime_SGW" INT 0 65535;
BA_DEF_ SG_ "GenSigTimeoutTime_RFHM" INT 0 65535;
BA_DEF_ SG_ "GenSigTimeoutTime_MPAD" INT 0 65535;
BA_DEF_ SG_ "GenSigTimeoutTime_IPC" INT 0 65535;
BA_DEF_ SG_ "GenSigTimeoutTime_GNMM" INT 0 65535;
BA_DEF_ SG_ "GenSigTimeoutTime_EVCU2" INT 0 65535;
BA_DEF_ SG_ "GenSigTimeoutTime_ESL" INT 0 65535;
BA_DEF_ SG_ "GenSigTimeoutTime_ECM" INT 0 65535;
BA_DEF_ SG_ "GenSigTimeoutTime_DTCM" INT 0 65535;
BA_DEF_ SG_ "GenSigTimeoutTime_DMSM" INT 0 65535;
BA_DEF_ SG_ "GenSigTimeoutTime_BSM" INT 0 65535;
BA_DEF_ SG_ "GenSigTimeoutTime_BCM" INT 0 65535;
BA_DEF_ SG_ "GenSigTimeoutTime_AGSM" INT 0 65535;
BA_DEF_ SG_ "GenSigTimeoutTime_ADCAM" INT 0 65535;
BA_DEF_ SG_ "SystemSignalLongSymbol" STRING ;
BA_DEF_ SG_ "GenSigSendType" ENUM "NotUsed","OnWrite","OnWriteWithRepetition","OnChange","OnChangeWithRepetition","IfActive","IfActiveWithRepetition","NoSigSendType";
BA_DEF_ SG_ "GenSigInactiveValue" INT 0 2147483647;
BA_DEF_ SG_ "GenSigStartValue" INT 0 2147483647;
BA_DEF_DEF_ "CANFD_BRS" "0";
BA_DEF_DEF_ "VFrameFormat" "StandardCAN_FD";
BA_DEF_DEF_ "DiagConnection" 0;
BA_DEF_DEF_ "DiagState" "No";
BA_DEF_DEF_ "NmAsrMessage" "No";
BA_DEF_DEF_ "GenMsgDelayTime" 0;
BA_DEF_DEF_ "GenMsgCycleTime" 0;
BA_DEF_DEF_ "GenMsgCycleTimeFast" 0;
BA_DEF_DEF_ "GenMsgStartDelayTime" 0;
BA_DEF_DEF_ "GenMsgILSupport" "No";
BA_DEF_DEF_ "GenMsgNrOfRepetition" 0;
BA_DEF_DEF_ "GenMsgSendType" "NoMsgSendType";
BA_DEF_DEF_ "NmMessage" "No";
BA_DEF_DEF_ "DiagResponse" "No";
BA_DEF_DEF_ "Type" "-";
BA_DEF_DEF_ "DiagRequest" "No";
BA_DEF_DEF_ "GenSigTimeoutTime_SGW" 2500;
BA_DEF_DEF_ "GenSigTimeoutTime_RFHM" 2500;
BA_DEF_DEF_ "GenSigTimeoutTime_MPAD" 2500;
BA_DEF_DEF_ "GenSigTimeoutTime_IPC" 2500;
BA_DEF_DEF_ "GenSigTimeoutTime_GNMM" 2500;
BA_DEF_DEF_ "GenSigTimeoutTime_EVCU2" 2500;
BA_DEF_DEF_ "GenSigTimeoutTime_ESL" 2500;
BA_DEF_DEF_ "GenSigTimeoutTime_ECM" 2500;
BA_DEF_DEF_ "GenSigTimeoutTime_DTCM" 2500;
BA_DEF_DEF_ "GenSigTimeoutTime_DMSM" 2500;
BA_DEF_DEF_ "GenSigTimeoutTime_BSM" 2500;
BA_DEF_DEF_ "GenSigTimeoutTime_BCM" 2500;
BA_DEF_DEF_ "GenSigTimeoutTime_AGSM" 2500;
BA_DEF_DEF_ "GenSigTimeoutTime_ADCAM" 2500;
BA_DEF_DEF_ "SystemSignalLongSymbol" "";
BA_DEF_DEF_ "GenSigSendType" "NoSigSendType";
BA_DEF_DEF_ "GenSigInactiveValue" 0;
BA_DEF_DEF_ "GenSigStartValue" 0;
BA_ "CANFD_BRS" BO_ 1426 1;
BA_ "GenMsgDelayTime" BO_ 1426 20;
BA_ "GenMsgCycleTime" BO_ 1426 1000;
BA_ "GenMsgCycleTimeFast" BO_ 1426 20;
BA_ "GenMsgILSupport" BO_ 1426 1;
BA_ "GenMsgNrOfRepetition" BO_ 1426 2;
BA_ "GenMsgSendType" BO_ 1426 0;
BA_ "Type" BO_ 1426 3;
BA_ "CANFD_BRS" BO_ 1853 1;
BA_ "GenMsgCycleTime" BO_ 1853 1000;
BA_ "GenMsgILSupport" BO_ 1853 1;
BA_ "GenMsgSendType" BO_ 1853 0;
BA_ "Type" BO_ 1853 1;
BA_ "CANFD_BRS" BO_ 1439 1;
BA_ "GenMsgDelayTime" BO_ 1439 20;
BA_ "GenMsgCycleTime" BO_ 1439 1000;
BA_ "GenMsgCycleTimeFast" BO_ 1439 20;
BA_ "GenMsgILSupport" BO_ 1439 1;
BA_ "GenMsgNrOfRepetition" BO_ 1439 2;
BA_ "GenMsgSendType" BO_ 1439 0;
BA_ "Type" BO_ 1439 3;
BA_ "Type" BO_ 126 8;
BA_ "GenMsgILSupport" BO_ 126 1;
BA_ "CANFD_BRS" BO_ 126 1;
BA_ "Type" BO_ 123 8;
BA_ "GenMsgILSupport" BO_ 123 1;
BA_ "CANFD_BRS" BO_ 123 1;
BA_ "Type" BO_ 127 8;
BA_ "GenMsgILSupport" BO_ 127 1;
BA_ "CANFD_BRS" BO_ 127 1;
BA_ "Type" BO_ 124 8;
BA_ "GenMsgILSupport" BO_ 124 1;
BA_ "CANFD_BRS" BO_ 124 1;
BA_ "CANFD_BRS" BO_ 834 1;
BA_ "GenMsgILSupport" BO_ 834 1;
BA_ "Type" BO_ 834 8;
BA_ "CANFD_BRS" BO_ 835 1;
BA_ "GenMsgILSupport" BO_ 835 1;
BA_ "Type" BO_ 835 8;
BA_ "CANFD_BRS" BO_ 1462 1;
BA_ "GenMsgCycleTime" BO_ 1462 1000;
BA_ "GenMsgILSupport" BO_ 1462 1;
BA_ "GenMsgSendType" BO_ 1462 0;
BA_ "Type" BO_ 1462 3;
BA_ "CANFD_BRS" BO_ 1471 1;
BA_ "GenMsgCycleTime" BO_ 1471 1000;
BA_ "GenMsgILSupport" BO_ 1471 1;
BA_ "GenMsgSendType" BO_ 1471 0;
BA_ "Type" BO_ 1471 3;
BA_ "CANFD_BRS" BO_ 1468 1;
BA_ "GenMsgCycleTime" BO_ 1468 1000;
BA_ "GenMsgILSupport" BO_ 1468 1;
BA_ "GenMsgSendType" BO_ 1468 0;
BA_ "Type" BO_ 1468 3;
BA_ "CANFD_BRS" BO_ 105 1;
BA_ "GenMsgDelayTime" BO_ 105 100;
BA_ "GenMsgCycleTime" BO_ 105 1000;
BA_ "GenMsgILSupport" BO_ 105 1;
BA_ "GenMsgSendType" BO_ 105 0;
BA_ "Type" BO_ 105 3;
BA_ "CANFD_BRS" BO_ 1442 1;
BA_ "GenMsgDelayTime" BO_ 1442 100;
BA_ "GenMsgCycleTime" BO_ 1442 1000;
BA_ "GenMsgCycleTimeFast" BO_ 1442 100;
BA_ "GenMsgILSupport" BO_ 1442 1;
BA_ "GenMsgNrOfRepetition" BO_ 1442 2;
BA_ "GenMsgSendType" BO_ 1442 0;
BA_ "Type" BO_ 1442 3;
BA_ "CANFD_BRS" BO_ 2651930736 1;
BA_ "VFrameFormat" BO_ 2651930736 15;
BA_ "GenMsgILSupport" BO_ 2651930736 1;
BA_ "Type" BO_ 2651930736 11;
BA_ "CANFD_BRS" BO_ 2654339257 1;
BA_ "VFrameFormat" BO_ 2654339257 15;
BA_ "GenMsgCycleTime" BO_ 2654339257 1000;
BA_ "GenMsgILSupport" BO_ 2654339257 1;
BA_ "GenMsgSendType" BO_ 2654339257 0;
BA_ "Type" BO_ 2654339257 1;
BA_ "CANFD_BRS" BO_ 1474 1;
BA_ "GenMsgDelayTime" BO_ 1474 20;
BA_ "GenMsgCycleTime" BO_ 1474 1000;
BA_ "GenMsgCycleTimeFast" BO_ 1474 20;
BA_ "GenMsgILSupport" BO_ 1474 1;
BA_ "GenMsgNrOfRepetition" BO_ 1474 2;
BA_ "GenMsgSendType" BO_ 1474 0;
BA_ "Type" BO_ 1474 3;
BA_ "VFrameFormat" BO_ 2564682099 1;
BA_ "DiagConnection" BO_ 2564682099 61811;
BA_ "DiagResponse" BO_ 2564682099 1;
BA_ "Type" BO_ 2564682099 8;
BA_ "CANFD_BRS" BO_ 2564682355 1;
BA_ "VFrameFormat" BO_ 2564682355 15;
BA_ "DiagConnection" BO_ 2564682355 62067;
BA_ "DiagResponse" BO_ 2564682355 1;
BA_ "Type" BO_ 2564682355 8;
BA_ "VFrameFormat" BO_ 2564485491 1;
BA_ "DiagConnection" BO_ 2564485491 61811;
BA_ "DiagResponse" BO_ 2564485491 1;
BA_ "Type" BO_ 2564485491 8;
BA_ "CANFD_BRS" BO_ 2564485747 1;
BA_ "VFrameFormat" BO_ 2564485747 15;
BA_ "DiagConnection" BO_ 2564485747 62067;
BA_ "DiagResponse" BO_ 2564485747 1;
BA_ "Type" BO_ 2564485747 8;
BA_ "VFrameFormat" BO_ 2564453361 1;
BA_ "DiagConnection" BO_ 2564453361 61811;
BA_ "Type" BO_ 2564453361 8;
BA_ "DiagRequest" BO_ 2564453361 1;
BA_ "CANFD_BRS" BO_ 2564453362 1;
BA_ "VFrameFormat" BO_ 2564453362 15;
BA_ "DiagConnection" BO_ 2564453362 62067;
BA_ "Type" BO_ 2564453362 8;
BA_ "DiagRequest" BO_ 2564453362 1;
BA_ "GenMsgDelayTime" BO_ 1440 20;
BA_ "GenMsgCycleTime" BO_ 1440 1000;
BA_ "GenMsgCycleTimeFast" BO_ 1440 20;
BA_ "GenMsgILSupport" BO_ 1440 1;
BA_ "GenMsgNrOfRepetition" BO_ 1440 2;
BA_ "GenMsgSendType" BO_ 1440 0;
BA_ "Type" BO_ 1440 3;
BA_ "CANFD_BRS" BO_ 1440 1;
BA_ "CANFD_BRS" BO_ 2564554485 1;
BA_ "VFrameFormat" BO_ 2564554485 15;
BA_ "DiagConnection" BO_ 2564554485 62974;
BA_ "DiagState" BO_ 2564554485 1;
BA_ "Type" BO_ 2564554485 8;
BA_ "CANFD_BRS" BO_ 1316 1;
BA_ "GenMsgDelayTime" BO_ 1316 20;
BA_ "GenMsgCycleTime" BO_ 1316 200;
BA_ "GenMsgStartDelayTime" BO_ 1316 100;
BA_ "GenMsgILSupport" BO_ 1316 1;
BA_ "GenMsgNrOfRepetition" BO_ 1316 2;
BA_ "GenMsgSendType" BO_ 1316 0;
BA_ "Type" BO_ 1316 1;
BA_ "CANFD_BRS" BO_ 205 1;
BA_ "GenMsgCycleTime" BO_ 205 10;
BA_ "GenMsgILSupport" BO_ 205 1;
BA_ "GenMsgSendType" BO_ 205 0;
BA_ "Type" BO_ 205 1;
BA_ "CANFD_BRS" BO_ 204 1;
BA_ "GenMsgCycleTime" BO_ 204 10;
BA_ "GenMsgILSupport" BO_ 204 1;
BA_ "GenMsgSendType" BO_ 204 0;
BA_ "Type" BO_ 204 1;
BA_ "CANFD_BRS" BO_ 1478 1;
BA_ "GenMsgCycleTime" BO_ 1478 1000;
BA_ "GenMsgILSupport" BO_ 1478 1;
BA_ "GenMsgSendType" BO_ 1478 0;
BA_ "Type" BO_ 1478 3;
BA_ "CANFD_BRS" BO_ 125 1;
BA_ "GenMsgDelayTime" BO_ 125 20;
BA_ "GenMsgCycleTimeFast" BO_ 125 20;
BA_ "GenMsgILSupport" BO_ 125 1;
BA_ "GenMsgNrOfRepetition" BO_ 125 2;
BA_ "Type" BO_ 125 8;
BA_ "GenSigTimeoutTime_SGW" SG_ 2564682099 N_PDU 0;
BA_ "GenSigTimeoutTime_RFHM" SG_ 2564682099 N_PDU 0;
BA_ "GenSigTimeoutTime_MPAD" SG_ 2564682099 N_PDU 0;
BA_ "GenSigTimeoutTime_IPC" SG_ 2564682099 N_PDU 0;
BA_ "GenSigTimeoutTime_GNMM" SG_ 2564682099 N_PDU 0;
BA_ "GenSigTimeoutTime_EVCU2" SG_ 2564682099 N_PDU 0;
BA_ "GenSigTimeoutTime_ESL" SG_ 2564682099 N_PDU 0;
BA_ "GenSigTimeoutTime_ECM" SG_ 2564682099 N_PDU 0;
BA_ "GenSigTimeoutTime_DTCM" SG_ 2564682099 N_PDU 0;
BA_ "GenSigTimeoutTime_DMSM" SG_ 2564682099 N_PDU 0;
BA_ "GenSigTimeoutTime_BSM" SG_ 2564682099 N_PDU 0;
BA_ "GenSigTimeoutTime_BCM" SG_ 2564682099 N_PDU 0;
BA_ "GenSigTimeoutTime_AGSM" SG_ 2564682099 N_PDU 0;
BA_ "GenSigTimeoutTime_ADCAM" SG_ 2564682099 N_PDU 0;
BA_ "GenSigTimeoutTime_SGW" SG_ 2564682355 N_PDU 0;
BA_ "GenSigTimeoutTime_RFHM" SG_ 2564682355 N_PDU 0;
BA_ "GenSigTimeoutTime_MPAD" SG_ 2564682355 N_PDU 0;
BA_ "GenSigTimeoutTime_IPC" SG_ 2564682355 N_PDU 0;
BA_ "GenSigTimeoutTime_GNMM" SG_ 2564682355 N_PDU 0;
BA_ "GenSigTimeoutTime_EVCU2" SG_ 2564682355 N_PDU 0;
BA_ "GenSigTimeoutTime_ESL" SG_ 2564682355 N_PDU 0;
BA_ "GenSigTimeoutTime_ECM" SG_ 2564682355 N_PDU 0;
BA_ "GenSigTimeoutTime_DTCM" SG_ 2564682355 N_PDU 0;
BA_ "GenSigTimeoutTime_DMSM" SG_ 2564682355 N_PDU 0;
BA_ "GenSigTimeoutTime_BSM" SG_ 2564682355 N_PDU 0;
BA_ "GenSigTimeoutTime_BCM" SG_ 2564682355 N_PDU 0;
BA_ "GenSigTimeoutTime_AGSM" SG_ 2564682355 N_PDU 0;
BA_ "GenSigTimeoutTime_ADCAM" SG_ 2564682355 N_PDU 0;
BA_ "GenSigTimeoutTime_DTCM" SG_ 2564485491 N_PDU 0;
BA_ "GenSigTimeoutTime_DMSM" SG_ 2564485491 N_PDU 0;
BA_ "GenSigTimeoutTime_BSM" SG_ 2564485491 N_PDU 0;
BA_ "GenSigTimeoutTime_BCM" SG_ 2564485491 N_PDU 0;
BA_ "GenSigTimeoutTime_AGSM" SG_ 2564485491 N_PDU 0;
BA_ "GenSigTimeoutTime_ADCAM" SG_ 2564485491 N_PDU 0;
BA_ "GenSigTimeoutTime_SGW" SG_ 2564485491 N_PDU 0;
BA_ "GenSigTimeoutTime_RFHM" SG_ 2564485491 N_PDU 0;
BA_ "GenSigTimeoutTime_MPAD" SG_ 2564485491 N_PDU 0;
BA_ "GenSigTimeoutTime_IPC" SG_ 2564485491 N_PDU 0;
BA_ "GenSigTimeoutTime_GNMM" SG_ 2564485491 N_PDU 0;
BA_ "GenSigTimeoutTime_EVCU2" SG_ 2564485491 N_PDU 0;
BA_ "GenSigTimeoutTime_ESL" SG_ 2564485491 N_PDU 0;
BA_ "GenSigTimeoutTime_ECM" SG_ 2564485491 N_PDU 0;
BA_ "GenSigTimeoutTime_SGW" SG_ 2564485747 N_PDU 0;
BA_ "GenSigTimeoutTime_RFHM" SG_ 2564485747 N_PDU 0;
BA_ "GenSigTimeoutTime_MPAD" SG_ 2564485747 N_PDU 0;
BA_ "GenSigTimeoutTime_IPC" SG_ 2564485747 N_PDU 0;
BA_ "GenSigTimeoutTime_GNMM" SG_ 2564485747 N_PDU 0;
BA_ "GenSigTimeoutTime_EVCU2" SG_ 2564485747 N_PDU 0;
BA_ "GenSigTimeoutTime_ESL" SG_ 2564485747 N_PDU 0;
BA_ "GenSigTimeoutTime_ECM" SG_ 2564485747 N_PDU 0;
BA_ "GenSigTimeoutTime_DTCM" SG_ 2564485747 N_PDU 0;
BA_ "GenSigTimeoutTime_DMSM" SG_ 2564485747 N_PDU 0;
BA_ "GenSigTimeoutTime_BSM" SG_ 2564485747 N_PDU 0;
BA_ "GenSigTimeoutTime_BCM" SG_ 2564485747 N_PDU 0;
BA_ "GenSigTimeoutTime_AGSM" SG_ 2564485747 N_PDU 0;
BA_ "GenSigTimeoutTime_ADCAM" SG_ 2564485747 N_PDU 0;
BA_ "GenSigTimeoutTime_SGW" SG_ 2564554485 N_PDU 0;
BA_ "GenSigTimeoutTime_RFHM" SG_ 2564554485 N_PDU 0;
BA_ "GenSigTimeoutTime_MPAD" SG_ 2564554485 N_PDU 0;
BA_ "GenSigTimeoutTime_IPC" SG_ 2564554485 N_PDU 0;
BA_ "GenSigTimeoutTime_GNMM" SG_ 2564554485 N_PDU 0;
BA_ "GenSigTimeoutTime_EVCU2" SG_ 2564554485 N_PDU 0;
BA_ "GenSigTimeoutTime_ESL" SG_ 2564554485 N_PDU 0;
BA_ "GenSigTimeoutTime_ECM" SG_ 2564554485 N_PDU 0;
BA_ "GenSigTimeoutTime_DTCM" SG_ 2564554485 N_PDU 0;
BA_ "GenSigTimeoutTime_DMSM" SG_ 2564554485 N_PDU 0;
BA_ "GenSigTimeoutTime_BSM" SG_ 2564554485 N_PDU 0;
BA_ "GenSigTimeoutTime_BCM" SG_ 2564554485 N_PDU 0;
BA_ "GenSigTimeoutTime_AGSM" SG_ 2564554485 N_PDU 0;
BA_ "GenSigTimeoutTime_ADCAM" SG_ 2564554485 N_PDU 0;
BA_ "GenSigTimeoutTime_SGW" SG_ 2564453361 N_PDU 0;
BA_ "GenSigTimeoutTime_RFHM" SG_ 2564453361 N_PDU 0;
BA_ "GenSigTimeoutTime_MPAD" SG_ 2564453361 N_PDU 0;
BA_ "GenSigTimeoutTime_IPC" SG_ 2564453361 N_PDU 0;
BA_ "GenSigTimeoutTime_GNMM" SG_ 2564453361 N_PDU 0;
BA_ "GenSigTimeoutTime_EVCU2" SG_ 2564453361 N_PDU 0;
BA_ "GenSigTimeoutTime_ESL" SG_ 2564453361 N_PDU 0;
BA_ "GenSigTimeoutTime_ECM" SG_ 2564453361 N_PDU 0;
BA_ "GenSigTimeoutTime_DTCM" SG_ 2564453361 N_PDU 0;
BA_ "GenSigTimeoutTime_DMSM" SG_ 2564453361 N_PDU 0;
BA_ "GenSigTimeoutTime_BSM" SG_ 2564453361 N_PDU 0;
BA_ "GenSigTimeoutTime_BCM" SG_ 2564453361 N_PDU 0;
BA_ "GenSigTimeoutTime_AGSM" SG_ 2564453361 N_PDU 0;
BA_ "GenSigTimeoutTime_ADCAM" SG_ 2564453361 N_PDU 0;
BA_ "GenSigTimeoutTime_SGW" SG_ 2564453362 N_PDU 0;
BA_ "GenSigTimeoutTime_RFHM" SG_ 2564453362 N_PDU 0;
BA_ "GenSigTimeoutTime_MPAD" SG_ 2564453362 N_PDU 0;
BA_ "GenSigTimeoutTime_IPC" SG_ 2564453362 N_PDU 0;
BA_ "GenSigTimeoutTime_GNMM" SG_ 2564453362 N_PDU 0;
BA_ "GenSigTimeoutTime_EVCU2" SG_ 2564453362 N_PDU 0;
BA_ "GenSigTimeoutTime_ESL" SG_ 2564453362 N_PDU 0;
BA_ "GenSigTimeoutTime_ECM" SG_ 2564453362 N_PDU 0;
BA_ "GenSigTimeoutTime_DTCM" SG_ 2564453362 N_PDU 0;
BA_ "GenSigTimeoutTime_DMSM" SG_ 2564453362 N_PDU 0;
BA_ "GenSigTimeoutTime_BSM" SG_ 2564453362 N_PDU 0;
BA_ "GenSigTimeoutTime_BCM" SG_ 2564453362 N_PDU 0;
BA_ "GenSigTimeoutTime_AGSM" SG_ 2564453362 N_PDU 0;
BA_ "GenSigTimeoutTime_ADCAM" SG_ 2564453362 N_PDU 0;
BA_ "GenSigTimeoutTime_RFHM" SG_ 2654339257 StayActiveSource_FD09_WCPM2 0;
BA_ "GenSigTimeoutTime_MPAD" SG_ 2654339257 StayActiveSource_FD09_WCPM2 0;
BA_ "GenSigTimeoutTime_IPC" SG_ 2654339257 StayActiveSource_FD09_WCPM2 0;
BA_ "GenSigTimeoutTime_GNMM" SG_ 2654339257 StayActiveSource_FD09_WCPM2 0;
BA_ "GenSigTimeoutTime_EVCU2" SG_ 2654339257 StayActiveSource_FD09_WCPM2 0;
BA_ "GenSigTimeoutTime_ESL" SG_ 2654339257 StayActiveSource_FD09_WCPM2 0;
BA_ "GenSigTimeoutTime_ECM" SG_ 2654339257 StayActiveSource_FD09_WCPM2 0;
BA_ "GenSigTimeoutTime_RFHM" SG_ 2654339257 WakeupSource_FD09_WCPM2 0;
BA_ "GenSigTimeoutTime_MPAD" SG_ 2654339257 WakeupSource_FD09_WCPM2 0;
BA_ "GenSigTimeoutTime_IPC" SG_ 2654339257 WakeupSource_FD09_WCPM2 0;
BA_ "GenSigTimeoutTime_GNMM" SG_ 2654339257 WakeupSource_FD09_WCPM2 0;
BA_ "GenSigTimeoutTime_EVCU2" SG_ 2654339257 WakeupSource_FD09_WCPM2 0;
BA_ "GenSigTimeoutTime_ESL" SG_ 2654339257 WakeupSource_FD09_WCPM2 0;
BA_ "GenSigTimeoutTime_ECM" SG_ 2654339257 WakeupSource_FD09_WCPM2 0;
BA_ "GenSigTimeoutTime_DTCM" SG_ 2654339257 WakeupSource_FD09_WCPM2 0;
BA_ "GenSigTimeoutTime_DMSM" SG_ 2654339257 WakeupSource_FD09_WCPM2 0;
BA_ "GenSigTimeoutTime_BSM" SG_ 2654339257 WakeupSource_FD09_WCPM2 0;
BA_ "GenSigTimeoutTime_BCM" SG_ 2654339257 WakeupSource_FD09_WCPM2 0;
BA_ "GenSigTimeoutTime_AGSM" SG_ 2654339257 WakeupSource_FD09_WCPM2 0;
BA_ "GenSigTimeoutTime_ADCAM" SG_ 2654339257 WakeupSource_FD09_WCPM2 0;
BA_ "GenSigTimeoutTime_BSM" SG_ 125 MESS_TTPM1 0;
BA_ "GenSigTimeoutTime_BCM" SG_ 125 MESS_TTPM1 0;
BA_ "GenSigTimeoutTime_AGSM" SG_ 125 MESS_TTPM1 0;
BA_ "GenSigTimeoutTime_ADCAM" SG_ 125 MESS_TTPM1 0;
BA_ "GenSigSendType" SG_ 125 MESS_TTPM1 1;
BA_ "GenSigTimeoutTime_RFHM" SG_ 125 MESS_TTPM1 0;
BA_ "GenSigTimeoutTime_MPAD" SG_ 125 MESS_TTPM1 0;
BA_ "GenSigTimeoutTime_IPC" SG_ 125 MESS_TTPM1 0;
BA_ "GenSigTimeoutTime_GNMM" SG_ 125 MESS_TTPM1 0;
BA_ "GenSigTimeoutTime_EVCU2" SG_ 125 MESS_TTPM1 0;
BA_ "GenSigTimeoutTime_ESL" SG_ 125 MESS_TTPM1 0;
BA_ "GenSigTimeoutTime_ECM" SG_ 125 MESS_TTPM1 0;
BA_ "GenSigTimeoutTime_DTCM" SG_ 125 MESS_TTPM1 0;
BA_ "GenSigTimeoutTime_DMSM" SG_ 125 MESS_TTPM1 0;
BA_ "GenSigTimeoutTime_RFHM" SG_ 1474 TurnSignalView 0;
BA_ "GenSigTimeoutTime_MPAD" SG_ 1474 TurnSignalView 0;
BA_ "GenSigTimeoutTime_IPC" SG_ 1474 TurnSignalView 0;
BA_ "GenSigTimeoutTime_GNMM" SG_ 1474 TurnSignalView 0;
BA_ "GenSigTimeoutTime_EVCU2" SG_ 1474 TurnSignalView 0;
BA_ "GenSigTimeoutTime_ESL" SG_ 1474 TurnSignalView 0;
BA_ "GenSigTimeoutTime_ECM" SG_ 1474 TurnSignalView 0;
BA_ "GenSigTimeoutTime_DTCM" SG_ 1474 TurnSignalView 0;
BA_ "GenSigTimeoutTime_DMSM" SG_ 1474 TurnSignalView 0;
BA_ "GenSigTimeoutTime_BSM" SG_ 1474 TurnSignalView 0;
BA_ "GenSigTimeoutTime_AGSM" SG_ 1474 TurnSignalView 0;
BA_ "GenSigTimeoutTime_ADCAM" SG_ 1474 TurnSignalView 0;
BA_ "GenSigSendType" SG_ 1474 TurnSignalView 4;
BA_ "GenSigTimeoutTime_RFHM" SG_ 1474 TSI_Offset_Kph 0;
BA_ "GenSigTimeoutTime_MPAD" SG_ 1474 TSI_Offset_Kph 0;
BA_ "GenSigTimeoutTime_GNMM" SG_ 1474 TSI_Offset_Kph 0;
BA_ "GenSigTimeoutTime_EVCU2" SG_ 1474 TSI_Offset_Kph 0;
BA_ "GenSigTimeoutTime_RFHM" SG_ 1474 TSI_Offset_Mph 0;
BA_ "GenSigTimeoutTime_MPAD" SG_ 1474 TSI_Offset_Mph 0;
BA_ "GenSigTimeoutTime_GNMM" SG_ 1474 TSI_Offset_Mph 0;
BA_ "GenSigTimeoutTime_EVCU2" SG_ 1474 TSI_Offset_Mph 0;
BA_ "GenSigTimeoutTime_ESL" SG_ 1474 TSI_Offset_Mph 0;
BA_ "GenSigTimeoutTime_ECM" SG_ 1474 TSI_Offset_Mph 0;
BA_ "GenSigTimeoutTime_DTCM" SG_ 1474 TSI_Offset_Mph 0;
BA_ "GenSigTimeoutTime_DMSM" SG_ 1474 TSI_Offset_Mph 0;
BA_ "GenSigTimeoutTime_BSM" SG_ 1474 TSI_Offset_Mph 0;
BA_ "GenSigTimeoutTime_AGSM" SG_ 1474 TSI_Offset_Mph 0;
BA_ "GenSigTimeoutTime_ADCAM" SG_ 1474 TSI_Offset_Mph 0;
BA_ "GenSigSendType" SG_ 1474 TSI_Offset_Mph 3;
BA_ "GenSigStartValue" SG_ 1474 TSI_Offset_Mph 1;
BA_ "GenSigTimeoutTime_RFHM" SG_ 1474 ParkSenseSignalView 0;
BA_ "GenSigTimeoutTime_MPAD" SG_ 1474 ParkSenseSignalView 0;
BA_ "GenSigTimeoutTime_IPC" SG_ 1474 ParkSenseSignalView 0;
BA_ "GenSigTimeoutTime_GNMM" SG_ 1474 ParkSenseSignalView 0;
BA_ "GenSigTimeoutTime_EVCU2" SG_ 1474 ParkSenseSignalView 0;
BA_ "GenSigTimeoutTime_ESL" SG_ 1474 ParkSenseSignalView 0;
BA_ "GenSigTimeoutTime_ECM" SG_ 1474 ParkSenseSignalView 0;
BA_ "GenSigTimeoutTime_DTCM" SG_ 1474 ParkSenseSignalView 0;
BA_ "GenSigTimeoutTime_DMSM" SG_ 1474 ParkSenseSignalView 0;
BA_ "GenSigTimeoutTime_BSM" SG_ 1474 ParkSenseSignalView 0;
BA_ "GenSigTimeoutTime_AGSM" SG_ 1474 ParkSenseSignalView 0;
BA_ "GenSigTimeoutTime_ADCAM" SG_ 1474 ParkSenseSignalView 0;
BA_ "GenSigSendType" SG_ 1474 ParkSenseSignalView 4;
BA_ "GenSigTimeoutTime_RFHM" SG_ 1474 FOA_Alert_Type 0;
BA_ "GenSigTimeoutTime_MPAD" SG_ 1474 FOA_Alert_Type 0;
BA_ "GenSigTimeoutTime_IPC" SG_ 1474 FOA_Alert_Type 0;
BA_ "GenSigTimeoutTime_GNMM" SG_ 1474 FOA_Alert_Type 0;
BA_ "GenSigTimeoutTime_EVCU2" SG_ 1474 FOA_Alert_Type 0;
BA_ "GenSigTimeoutTime_ESL" SG_ 1474 FOA_Alert_Type 0;
BA_ "GenSigTimeoutTime_ECM" SG_ 1474 FOA_Alert_Type 0;
BA_ "GenSigTimeoutTime_DTCM" SG_ 1474 FOA_Alert_Type 0;
BA_ "GenSigTimeoutTime_DMSM" SG_ 1474 FOA_Alert_Type 0;
BA_ "GenSigTimeoutTime_BSM" SG_ 1474 FOA_Alert_Type 0;
BA_ "GenSigTimeoutTime_AGSM" SG_ 1474 FOA_Alert_Type 0;
BA_ "GenSigTimeoutTime_ADCAM" SG_ 1474 FOA_Alert_Type 0;
BA_ "GenSigSendType" SG_ 1474 FOA_Alert_Type 3;
BA_ "GenSigStartValue" SG_ 1474 FOA_Alert_Type 1;
BA_ "GenSigTimeoutTime_ESL" SG_ 1474 TSI_Offset_Kph 0;
BA_ "GenSigTimeoutTime_ECM" SG_ 1474 TSI_Offset_Kph 0;
BA_ "GenSigTimeoutTime_DTCM" SG_ 1474 TSI_Offset_Kph 0;
BA_ "GenSigTimeoutTime_DMSM" SG_ 1474 TSI_Offset_Kph 0;
BA_ "GenSigTimeoutTime_BSM" SG_ 1474 TSI_Offset_Kph 0;
BA_ "GenSigTimeoutTime_AGSM" SG_ 1474 TSI_Offset_Kph 0;
BA_ "GenSigTimeoutTime_ADCAM" SG_ 1474 TSI_Offset_Kph 0;
BA_ "GenSigSendType" SG_ 1474 TSI_Offset_Kph 3;
BA_ "GenSigStartValue" SG_ 1474 TSI_Offset_Kph 1;
BA_ "GenSigTimeoutTime_RFHM" SG_ 1474 Fuel_Saver_Display 0;
BA_ "GenSigTimeoutTime_MPAD" SG_ 1474 Fuel_Saver_Display 0;
BA_ "GenSigTimeoutTime_IPC" SG_ 1474 Fuel_Saver_Display 0;
BA_ "GenSigTimeoutTime_GNMM" SG_ 1474 Fuel_Saver_Display 0;
BA_ "GenSigTimeoutTime_EVCU2" SG_ 1474 Fuel_Saver_Display 0;
BA_ "GenSigTimeoutTime_ESL" SG_ 1474 Fuel_Saver_Display 0;
BA_ "GenSigTimeoutTime_ECM" SG_ 1474 Fuel_Saver_Display 0;
BA_ "GenSigTimeoutTime_DTCM" SG_ 1474 Fuel_Saver_Display 0;
BA_ "GenSigTimeoutTime_DMSM" SG_ 1474 Fuel_Saver_Display 0;
BA_ "GenSigTimeoutTime_BSM" SG_ 1474 Fuel_Saver_Display 0;
BA_ "GenSigTimeoutTime_AGSM" SG_ 1474 Fuel_Saver_Display 0;
BA_ "GenSigTimeoutTime_ADCAM" SG_ 1474 Fuel_Saver_Display 0;
BA_ "GenSigSendType" SG_ 1474 Fuel_Saver_Display 4;
BA_ "GenSigTimeoutTime_RFHM" SG_ 1474 EPB_Service_Mode 0;
BA_ "GenSigTimeoutTime_MPAD" SG_ 1474 EPB_Service_Mode 0;
BA_ "GenSigTimeoutTime_IPC" SG_ 1474 EPB_Service_Mode 0;
BA_ "GenSigTimeoutTime_GNMM" SG_ 1474 EPB_Service_Mode 0;
BA_ "GenSigTimeoutTime_EVCU2" SG_ 1474 EPB_Service_Mode 0;
BA_ "GenSigTimeoutTime_ESL" SG_ 1474 EPB_Service_Mode 0;
BA_ "GenSigTimeoutTime_ECM" SG_ 1474 EPB_Service_Mode 0;
BA_ "GenSigTimeoutTime_DTCM" SG_ 1474 EPB_Service_Mode 0;
BA_ "GenSigTimeoutTime_DMSM" SG_ 1474 EPB_Service_Mode 0;
BA_ "GenSigTimeoutTime_BSM" SG_ 1474 EPB_Service_Mode 0;
BA_ "GenSigTimeoutTime_AGSM" SG_ 1474 EPB_Service_Mode 0;
BA_ "GenSigTimeoutTime_ADCAM" SG_ 1474 EPB_Service_Mode 0;
BA_ "GenSigSendType" SG_ 1474 EPB_Service_Mode 4;
BA_ "GenSigTimeoutTime_RFHM" SG_ 1474 Creep 0;
BA_ "GenSigTimeoutTime_MPAD" SG_ 1474 Creep 0;
BA_ "GenSigTimeoutTime_GNMM" SG_ 1474 Creep 0;
BA_ "GenSigTimeoutTime_ESL" SG_ 1474 Creep 0;
BA_ "GenSigTimeoutTime_ECM" SG_ 1474 Creep 0;
BA_ "GenSigTimeoutTime_DTCM" SG_ 1474 Creep 0;
BA_ "GenSigTimeoutTime_DMSM" SG_ 1474 Creep 0;
BA_ "GenSigTimeoutTime_BSM" SG_ 1474 Creep 0;
BA_ "GenSigTimeoutTime_AGSM" SG_ 1474 Creep 0;
BA_ "GenSigTimeoutTime_ADCAM" SG_ 1474 Creep 0;
BA_ "GenSigSendType" SG_ 1474 Creep 4;
BA_ "GenSigStartValue" SG_ 1474 Creep 1;
BA_ "GenSigTimeoutTime_RFHM" SG_ 1474 RouteGuidance 0;
BA_ "GenSigTimeoutTime_IPC" SG_ 1474 RouteGuidance 0;
BA_ "GenSigTimeoutTime_GNMM" SG_ 1474 RouteGuidance 0;
BA_ "GenSigTimeoutTime_EVCU2" SG_ 1474 RouteGuidance 0;
BA_ "GenSigTimeoutTime_ESL" SG_ 1474 RouteGuidance 0;
BA_ "GenSigTimeoutTime_ECM" SG_ 1474 RouteGuidance 0;
BA_ "GenSigTimeoutTime_DTCM" SG_ 1474 RouteGuidance 0;
BA_ "GenSigTimeoutTime_DMSM" SG_ 1474 RouteGuidance 0;
BA_ "GenSigTimeoutTime_BSM" SG_ 1474 RouteGuidance 0;
BA_ "GenSigTimeoutTime_AGSM" SG_ 1474 RouteGuidance 0;
BA_ "GenSigTimeoutTime_ADCAM" SG_ 1474 RouteGuidance 0;
BA_ "GenSigSendType" SG_ 1474 RouteGuidance 4;
BA_ "GenSigStartValue" SG_ 1474 RouteGuidance 1;
BA_ "GenSigTimeoutTime_RFHM" SG_ 1474 EmergencyCorridorAssist 0;
BA_ "GenSigTimeoutTime_IPC" SG_ 1474 EmergencyCorridorAssist 0;
BA_ "GenSigTimeoutTime_GNMM" SG_ 1474 EmergencyCorridorAssist 0;
BA_ "GenSigTimeoutTime_EVCU2" SG_ 1474 EmergencyCorridorAssist 0;
BA_ "GenSigTimeoutTime_ESL" SG_ 1474 EmergencyCorridorAssist 0;
BA_ "GenSigTimeoutTime_ECM" SG_ 1474 EmergencyCorridorAssist 0;
BA_ "GenSigTimeoutTime_DTCM" SG_ 1474 EmergencyCorridorAssist 0;
BA_ "GenSigTimeoutTime_DMSM" SG_ 1474 EmergencyCorridorAssist 0;
BA_ "GenSigTimeoutTime_BSM" SG_ 1474 EmergencyCorridorAssist 0;
BA_ "GenSigTimeoutTime_AGSM" SG_ 1474 EmergencyCorridorAssist 0;
BA_ "GenSigTimeoutTime_ADCAM" SG_ 1474 EmergencyCorridorAssist 0;
BA_ "GenSigSendType" SG_ 1474 EmergencyCorridorAssist 4;
BA_ "GenSigStartValue" SG_ 1474 EmergencyCorridorAssist 1;
BA_ "GenSigTimeoutTime_RFHM" SG_ 1474 StopOnTraffic 0;
BA_ "GenSigTimeoutTime_IPC" SG_ 1474 StopOnTraffic 0;
BA_ "GenSigTimeoutTime_GNMM" SG_ 1474 StopOnTraffic 0;
BA_ "GenSigTimeoutTime_EVCU2" SG_ 1474 StopOnTraffic 0;
BA_ "GenSigTimeoutTime_ESL" SG_ 1474 StopOnTraffic 0;
BA_ "GenSigTimeoutTime_ECM" SG_ 1474 StopOnTraffic 0;
BA_ "GenSigTimeoutTime_DTCM" SG_ 1474 StopOnTraffic 0;
BA_ "GenSigTimeoutTime_DMSM" SG_ 1474 StopOnTraffic 0;
BA_ "GenSigTimeoutTime_BSM" SG_ 1474 StopOnTraffic 0;
BA_ "GenSigTimeoutTime_AGSM" SG_ 1474 StopOnTraffic 0;
BA_ "GenSigTimeoutTime_ADCAM" SG_ 1474 StopOnTraffic 0;
BA_ "GenSigSendType" SG_ 1474 StopOnTraffic 4;
BA_ "GenSigStartValue" SG_ 1474 StopOnTraffic 2;
BA_ "GenSigTimeoutTime_RFHM" SG_ 1474 SpeedLimitAdjust 0;
BA_ "GenSigTimeoutTime_IPC" SG_ 1474 SpeedLimitAdjust 0;
BA_ "GenSigTimeoutTime_GNMM" SG_ 1474 SpeedLimitAdjust 0;
BA_ "GenSigTimeoutTime_EVCU2" SG_ 1474 SpeedLimitAdjust 0;
BA_ "GenSigTimeoutTime_ESL" SG_ 1474 SpeedLimitAdjust 0;
BA_ "GenSigTimeoutTime_ECM" SG_ 1474 SpeedLimitAdjust 0;
BA_ "GenSigTimeoutTime_DTCM" SG_ 1474 SpeedLimitAdjust 0;
BA_ "GenSigTimeoutTime_DMSM" SG_ 1474 SpeedLimitAdjust 0;
BA_ "GenSigTimeoutTime_BSM" SG_ 1474 SpeedLimitAdjust 0;
BA_ "GenSigTimeoutTime_AGSM" SG_ 1474 SpeedLimitAdjust 0;
BA_ "GenSigTimeoutTime_ADCAM" SG_ 1474 SpeedLimitAdjust 0;
BA_ "GenSigSendType" SG_ 1474 SpeedLimitAdjust 3;
BA_ "GenSigStartValue" SG_ 1474 SpeedLimitAdjust 2;
BA_ "GenSigTimeoutTime_RFHM" SG_ 1474 SpeedAdjust 0;
BA_ "GenSigTimeoutTime_MPAD" SG_ 1474 SpeedAdjust 0;
BA_ "GenSigTimeoutTime_IPC" SG_ 1474 SpeedAdjust 0;
BA_ "GenSigTimeoutTime_GNMM" SG_ 1474 SpeedAdjust 0;
BA_ "GenSigTimeoutTime_EVCU2" SG_ 1474 SpeedAdjust 0;
BA_ "GenSigTimeoutTime_ESL" SG_ 1474 SpeedAdjust 0;
BA_ "GenSigTimeoutTime_ECM" SG_ 1474 SpeedAdjust 0;
BA_ "GenSigTimeoutTime_DTCM" SG_ 1474 SpeedAdjust 0;
BA_ "GenSigTimeoutTime_DMSM" SG_ 1474 SpeedAdjust 0;
BA_ "GenSigTimeoutTime_BSM" SG_ 1474 SpeedAdjust 0;
BA_ "GenSigTimeoutTime_AGSM" SG_ 1474 SpeedAdjust 0;
BA_ "GenSigTimeoutTime_ADCAM" SG_ 1474 SpeedAdjust 0;
BA_ "GenSigSendType" SG_ 1474 SpeedAdjust 4;
BA_ "GenSigStartValue" SG_ 1474 SpeedAdjust 1;
BA_ "GenSigTimeoutTime_RFHM" SG_ 1474 AssistedLaneChange 0;
BA_ "GenSigTimeoutTime_IPC" SG_ 1474 AssistedLaneChange 0;
BA_ "GenSigTimeoutTime_GNMM" SG_ 1474 AssistedLaneChange 0;
BA_ "GenSigTimeoutTime_EVCU2" SG_ 1474 AssistedLaneChange 0;
BA_ "GenSigTimeoutTime_ESL" SG_ 1474 AssistedLaneChange 0;
BA_ "GenSigTimeoutTime_ECM" SG_ 1474 AssistedLaneChange 0;
BA_ "GenSigTimeoutTime_DTCM" SG_ 1474 AssistedLaneChange 0;
BA_ "GenSigTimeoutTime_DMSM" SG_ 1474 AssistedLaneChange 0;
BA_ "GenSigTimeoutTime_BSM" SG_ 1474 AssistedLaneChange 0;
BA_ "GenSigTimeoutTime_AGSM" SG_ 1474 AssistedLaneChange 0;
BA_ "GenSigTimeoutTime_ADCAM" SG_ 1474 AssistedLaneChange 0;
BA_ "GenSigSendType" SG_ 1474 AssistedLaneChange 3;
BA_ "GenSigStartValue" SG_ 1474 AssistedLaneChange 1;
BA_ "GenSigTimeoutTime_SGW" SG_ 105 MessageCounter_VDCM_PWT3 0;
BA_ "GenSigTimeoutTime_RFHM" SG_ 105 MessageCounter_VDCM_PWT3 0;
BA_ "GenSigTimeoutTime_MPAD" SG_ 105 MessageCounter_VDCM_PWT3 0;
BA_ "GenSigTimeoutTime_IPC" SG_ 105 MessageCounter_VDCM_PWT3 0;
BA_ "GenSigTimeoutTime_GNMM" SG_ 105 MessageCounter_VDCM_PWT3 0;
BA_ "GenSigTimeoutTime_EVCU2" SG_ 105 MessageCounter_VDCM_PWT3 0;
BA_ "GenSigTimeoutTime_ESL" SG_ 105 MessageCounter_VDCM_PWT3 0;
BA_ "GenSigTimeoutTime_ECM" SG_ 105 MessageCounter_VDCM_PWT3 0;
BA_ "GenSigTimeoutTime_DMSM" SG_ 105 MessageCounter_VDCM_PWT3 0;
BA_ "GenSigTimeoutTime_BSM" SG_ 105 MessageCounter_VDCM_PWT3 0;
BA_ "GenSigTimeoutTime_BCM" SG_ 105 MessageCounter_VDCM_PWT3 0;
BA_ "GenSigTimeoutTime_AGSM" SG_ 105 MessageCounter_VDCM_PWT3 0;
BA_ "GenSigTimeoutTime_ADCAM" SG_ 105 MessageCounter_VDCM_PWT3 0;
BA_ "GenSigSendType" SG_ 105 MessageCounter_VDCM_PWT3 3;
BA_ "GenSigTimeoutTime_SGW" SG_ 105 CRC_VDCM_PWT3 0;
BA_ "GenSigTimeoutTime_RFHM" SG_ 105 CRC_VDCM_PWT3 0;
BA_ "GenSigTimeoutTime_MPAD" SG_ 105 CRC_VDCM_PWT3 0;
BA_ "GenSigTimeoutTime_IPC" SG_ 105 CRC_VDCM_PWT3 0;
BA_ "GenSigTimeoutTime_GNMM" SG_ 105 CRC_VDCM_PWT3 0;
BA_ "GenSigTimeoutTime_EVCU2" SG_ 105 CRC_VDCM_PWT3 0;
BA_ "GenSigTimeoutTime_ESL" SG_ 105 CRC_VDCM_PWT3 0;
BA_ "GenSigTimeoutTime_ECM" SG_ 105 CRC_VDCM_PWT3 0;
BA_ "GenSigTimeoutTime_DMSM" SG_ 105 CRC_VDCM_PWT3 0;
BA_ "GenSigTimeoutTime_BSM" SG_ 105 CRC_VDCM_PWT3 0;
BA_ "GenSigTimeoutTime_BCM" SG_ 105 CRC_VDCM_PWT3 0;
BA_ "GenSigTimeoutTime_AGSM" SG_ 105 CRC_VDCM_PWT3 0;
BA_ "GenSigTimeoutTime_ADCAM" SG_ 105 CRC_VDCM_PWT3 0;
BA_ "GenSigSendType" SG_ 105 CRC_VDCM_PWT3 3;
BA_ "GenSigTimeoutTime_RFHM" SG_ 1442 SugSpeedThreshold 0;
BA_ "GenSigTimeoutTime_MPAD" SG_ 1442 SugSpeedThreshold 0;
BA_ "GenSigTimeoutTime_IPC" SG_ 1442 SugSpeedThreshold 0;
BA_ "GenSigTimeoutTime_GNMM" SG_ 1442 SugSpeedThreshold 0;
BA_ "GenSigTimeoutTime_EVCU2" SG_ 1442 SugSpeedThreshold 0;
BA_ "GenSigTimeoutTime_ESL" SG_ 1442 SugSpeedThreshold 0;
BA_ "GenSigTimeoutTime_ECM" SG_ 1442 SugSpeedThreshold 0;
BA_ "GenSigTimeoutTime_DTCM" SG_ 1442 SugSpeedThreshold 0;
BA_ "GenSigTimeoutTime_DMSM" SG_ 1442 SugSpeedThreshold 0;
BA_ "GenSigTimeoutTime_BSM" SG_ 1442 SugSpeedThreshold 0;
BA_ "GenSigTimeoutTime_BCM" SG_ 1442 SugSpeedThreshold 0;
BA_ "GenSigTimeoutTime_AGSM" SG_ 1442 SugSpeedThreshold 0;
BA_ "GenSigTimeoutTime_ADCAM" SG_ 1442 SugSpeedThreshold 0;
BA_ "GenSigSendType" SG_ 1442 SugSpeedThreshold 3;
BA_ "GenSigTimeoutTime_SGW" SG_ 1442 SugSpeedThreshold 0;
BA_ "GenSigTimeoutTime_SGW" SG_ 1442 SugSpeedMin 0;
BA_ "GenSigTimeoutTime_RFHM" SG_ 1442 SugSpeedMin 0;
BA_ "GenSigTimeoutTime_MPAD" SG_ 1442 SugSpeedMin 0;
BA_ "GenSigTimeoutTime_IPC" SG_ 1442 SugSpeedMin 0;
BA_ "GenSigTimeoutTime_GNMM" SG_ 1442 SugSpeedMin 0;
BA_ "GenSigTimeoutTime_EVCU2" SG_ 1442 SugSpeedMin 0;
BA_ "GenSigTimeoutTime_ESL" SG_ 1442 SugSpeedMin 0;
BA_ "GenSigTimeoutTime_ECM" SG_ 1442 SugSpeedMin 0;
BA_ "GenSigTimeoutTime_DTCM" SG_ 1442 SugSpeedMin 0;
BA_ "GenSigTimeoutTime_DMSM" SG_ 1442 SugSpeedMin 0;
BA_ "GenSigTimeoutTime_BSM" SG_ 1442 SugSpeedMin 0;
BA_ "GenSigTimeoutTime_BCM" SG_ 1442 SugSpeedMin 0;
BA_ "GenSigTimeoutTime_AGSM" SG_ 1442 SugSpeedMin 0;
BA_ "GenSigTimeoutTime_ADCAM" SG_ 1442 SugSpeedMin 0;
BA_ "GenSigSendType" SG_ 1442 SugSpeedMin 3;
BA_ "GenSigTimeoutTime_SGW" SG_ 1442 SugSpeedMax 0;
BA_ "GenSigTimeoutTime_RFHM" SG_ 1442 SugSpeedMax 0;
BA_ "GenSigTimeoutTime_MPAD" SG_ 1442 SugSpeedMax 0;
BA_ "GenSigTimeoutTime_IPC" SG_ 1442 SugSpeedMax 0;
BA_ "GenSigTimeoutTime_GNMM" SG_ 1442 SugSpeedMax 0;
BA_ "GenSigTimeoutTime_EVCU2" SG_ 1442 SugSpeedMax 0;
BA_ "GenSigTimeoutTime_ESL" SG_ 1442 SugSpeedMax 0;
BA_ "GenSigTimeoutTime_SGW" SG_ 105 T4_Sensor_Temp 0;
BA_ "GenSigTimeoutTime_RFHM" SG_ 105 T4_Sensor_Temp 0;
BA_ "GenSigTimeoutTime_MPAD" SG_ 105 T4_Sensor_Temp 0;
BA_ "GenSigTimeoutTime_IPC" SG_ 105 T4_Sensor_Temp 0;
BA_ "GenSigTimeoutTime_GNMM" SG_ 105 T4_Sensor_Temp 0;
BA_ "GenSigTimeoutTime_EVCU2" SG_ 105 T4_Sensor_Temp 0;
BA_ "GenSigTimeoutTime_ESL" SG_ 105 T4_Sensor_Temp 0;
BA_ "GenSigTimeoutTime_ECM" SG_ 105 T4_Sensor_Temp 0;
BA_ "GenSigTimeoutTime_DTCM" SG_ 105 T4_Sensor_Temp 0;
BA_ "GenSigTimeoutTime_DMSM" SG_ 105 T4_Sensor_Temp 0;
BA_ "GenSigTimeoutTime_BSM" SG_ 105 T4_Sensor_Temp 0;
BA_ "GenSigTimeoutTime_AGSM" SG_ 105 T4_Sensor_Temp 0;
BA_ "GenSigTimeoutTime_ADCAM" SG_ 105 T4_Sensor_Temp 0;
BA_ "GenSigSendType" SG_ 105 T4_Sensor_Temp 3;
BA_ "GenSigTimeoutTime_ADCAM" SG_ 126 N_PDU 0;
BA_ "GenSigTimeoutTime_AGSM" SG_ 126 N_PDU 0;
BA_ "GenSigTimeoutTime_BCM" SG_ 126 N_PDU 0;
BA_ "GenSigTimeoutTime_BSM" SG_ 126 N_PDU 0;
BA_ "GenSigTimeoutTime_DMSM" SG_ 126 N_PDU 0;
BA_ "GenSigTimeoutTime_DTCM" SG_ 126 N_PDU 0;
BA_ "GenSigTimeoutTime_ECM" SG_ 126 N_PDU 0;
BA_ "GenSigTimeoutTime_ESL" SG_ 126 N_PDU 0;
BA_ "GenSigTimeoutTime_GNMM" SG_ 126 N_PDU 0;
BA_ "GenSigTimeoutTime_IPC" SG_ 126 N_PDU 0;
BA_ "GenSigTimeoutTime_MPAD" SG_ 126 N_PDU 0;
BA_ "GenSigTimeoutTime_RFHM" SG_ 126 N_PDU 0;
BA_ "GenSigTimeoutTime_SGW" SG_ 126 N_PDU 0;
BA_ "GenSigTimeoutTime_ADCAM" SG_ 123 N_PDU 0;
BA_ "GenSigTimeoutTime_AGSM" SG_ 123 N_PDU 0;
BA_ "GenSigTimeoutTime_BCM" SG_ 123 N_PDU 0;
BA_ "GenSigTimeoutTime_BSM" SG_ 123 N_PDU 0;
BA_ "GenSigTimeoutTime_DMSM" SG_ 123 N_PDU 0;
BA_ "GenSigTimeoutTime_DTCM" SG_ 123 N_PDU 0;
BA_ "GenSigTimeoutTime_ECM" SG_ 123 N_PDU 0;
BA_ "GenSigTimeoutTime_ESL" SG_ 123 N_PDU 0;
BA_ "GenSigTimeoutTime_EVCU2" SG_ 123 N_PDU 0;
BA_ "GenSigTimeoutTime_GNMM" SG_ 123 N_PDU 0;
BA_ "GenSigTimeoutTime_IPC" SG_ 123 N_PDU 0;
BA_ "GenSigTimeoutTime_MPAD" SG_ 123 N_PDU 0;
BA_ "GenSigTimeoutTime_RFHM" SG_ 123 N_PDU 0;
BA_ "GenSigTimeoutTime_ADCAM" SG_ 127 N_PDU 0;
BA_ "GenSigTimeoutTime_AGSM" SG_ 127 N_PDU 0;
BA_ "GenSigTimeoutTime_BCM" SG_ 127 N_PDU 0;
BA_ "GenSigTimeoutTime_BSM" SG_ 127 N_PDU 0;
BA_ "GenSigTimeoutTime_DMSM" SG_ 127 N_PDU 0;
BA_ "GenSigTimeoutTime_DTCM" SG_ 127 N_PDU 0;
BA_ "GenSigTimeoutTime_ECM" SG_ 127 N_PDU 0;
BA_ "GenSigTimeoutTime_ESL" SG_ 127 N_PDU 0;
BA_ "GenSigTimeoutTime_GNMM" SG_ 127 N_PDU 0;
BA_ "GenSigTimeoutTime_IPC" SG_ 127 N_PDU 0;
BA_ "GenSigTimeoutTime_MPAD" SG_ 127 N_PDU 0;
BA_ "GenSigTimeoutTime_RFHM" SG_ 127 N_PDU 0;
BA_ "GenSigTimeoutTime_SGW" SG_ 127 N_PDU 0;
BA_ "GenSigTimeoutTime_ADCAM" SG_ 124 N_PDU 0;
BA_ "GenSigTimeoutTime_AGSM" SG_ 124 N_PDU 0;
BA_ "GenSigTimeoutTime_BCM" SG_ 124 N_PDU 0;
BA_ "GenSigTimeoutTime_BSM" SG_ 124 N_PDU 0;
BA_ "GenSigTimeoutTime_DMSM" SG_ 124 N_PDU 0;
BA_ "GenSigTimeoutTime_DTCM" SG_ 124 N_PDU 0;
BA_ "GenSigTimeoutTime_ECM" SG_ 124 N_PDU 0;
BA_ "GenSigTimeoutTime_ESL" SG_ 124 N_PDU 0;
BA_ "GenSigTimeoutTime_EVCU2" SG_ 124 N_PDU 0;
BA_ "GenSigTimeoutTime_GNMM" SG_ 124 N_PDU 0;
BA_ "GenSigTimeoutTime_IPC" SG_ 124 N_PDU 0;
BA_ "GenSigTimeoutTime_MPAD" SG_ 124 N_PDU 0;
BA_ "GenSigTimeoutTime_RFHM" SG_ 124 N_PDU 0;
BA_ "GenSigTimeoutTime_RFHM" SG_ 834 N_PDU 0;
BA_ "GenSigTimeoutTime_MPAD" SG_ 834 N_PDU 0;
BA_ "GenSigTimeoutTime_IPC" SG_ 834 N_PDU 0;
BA_ "GenSigTimeoutTime_GNMM" SG_ 834 N_PDU 0;
BA_ "GenSigTimeoutTime_EVCU2" SG_ 834 N_PDU 0;
BA_ "GenSigTimeoutTime_ESL" SG_ 834 N_PDU 0;
BA_ "GenSigTimeoutTime_ECM" SG_ 834 N_PDU 0;
BA_ "GenSigTimeoutTime_DTCM" SG_ 834 N_PDU 0;
BA_ "GenSigTimeoutTime_DMSM" SG_ 834 N_PDU 0;
BA_ "GenSigTimeoutTime_BSM" SG_ 834 N_PDU 0;
BA_ "GenSigTimeoutTime_BCM" SG_ 834 N_PDU 0;
BA_ "GenSigTimeoutTime_AGSM" SG_ 834 N_PDU 0;
BA_ "GenSigTimeoutTime_ADCAM" SG_ 834 N_PDU 0;
BA_ "GenSigTimeoutTime_SGW" SG_ 835 N_PDU 0;
BA_ "GenSigTimeoutTime_RFHM" SG_ 835 N_PDU 0;
BA_ "GenSigTimeoutTime_MPAD" SG_ 835 N_PDU 0;
BA_ "GenSigTimeoutTime_IPC" SG_ 835 N_PDU 0;
BA_ "GenSigTimeoutTime_GNMM" SG_ 835 N_PDU 0;
BA_ "GenSigTimeoutTime_EVCU2" SG_ 835 N_PDU 0;
BA_ "GenSigTimeoutTime_ESL" SG_ 835 N_PDU 0;
BA_ "GenSigTimeoutTime_DTCM" SG_ 835 N_PDU 0;
BA_ "GenSigTimeoutTime_DMSM" SG_ 835 N_PDU 0;
BA_ "GenSigTimeoutTime_BSM" SG_ 835 N_PDU 0;
BA_ "GenSigTimeoutTime_BCM" SG_ 835 N_PDU 0;
BA_ "GenSigTimeoutTime_AGSM" SG_ 835 N_PDU 0;
BA_ "GenSigTimeoutTime_ADCAM" SG_ 835 N_PDU 0;
BA_ "GenSigTimeoutTime_SGW" SG_ 1462 TBM_Submit_ClimateSchd2 0;
BA_ "GenSigTimeoutTime_RFHM" SG_ 1462 TBM_Submit_ClimateSchd2 0;
BA_ "GenSigTimeoutTime_MPAD" SG_ 1462 TBM_Submit_ClimateSchd2 0;
BA_ "GenSigTimeoutTime_IPC" SG_ 1462 TBM_Submit_ClimateSchd2 0;
BA_ "GenSigTimeoutTime_GNMM" SG_ 1462 TBM_Submit_ClimateSchd2 0;
BA_ "GenSigTimeoutTime_ESL" SG_ 1462 TBM_Submit_ClimateSchd2 0;
BA_ "GenSigTimeoutTime_ECM" SG_ 1462 TBM_Submit_ClimateSchd2 0;
BA_ "GenSigTimeoutTime_DTCM" SG_ 1462 TBM_Submit_ClimateSchd2 0;
BA_ "GenSigTimeoutTime_DMSM" SG_ 1462 TBM_Submit_ClimateSchd2 0;
BA_ "GenSigTimeoutTime_BSM" SG_ 1462 TBM_Submit_ClimateSchd2 0;
BA_ "GenSigTimeoutTime_BCM" SG_ 1462 TBM_Submit_ClimateSchd2 0;
BA_ "GenSigTimeoutTime_AGSM" SG_ 1462 TBM_Submit_ClimateSchd2 0;
BA_ "GenSigTimeoutTime_ADCAM" SG_ 1462 TBM_Submit_ClimateSchd2 0;
BA_ "GenSigSendType" SG_ 1462 TBM_Submit_ClimateSchd2 3;
BA_ "GenSigTimeoutTime_SGW" SG_ 1462 TBM_Submit_ClimateSchd1 0;
BA_ "GenSigTimeoutTime_RFHM" SG_ 1462 TBM_Submit_ClimateSchd1 0;
BA_ "GenSigTimeoutTime_MPAD" SG_ 1462 TBM_Submit_ClimateSchd1 0;
BA_ "GenSigTimeoutTime_IPC" SG_ 1462 TBM_Submit_ClimateSchd1 0;
BA_ "GenSigTimeoutTime_GNMM" SG_ 1462 TBM_Submit_ClimateSchd1 0;
BA_ "GenSigTimeoutTime_ESL" SG_ 1462 TBM_Submit_ClimateSchd1 0;
BA_ "GenSigTimeoutTime_ECM" SG_ 1462 TBM_Submit_ClimateSchd1 0;
BA_ "GenSigTimeoutTime_DTCM" SG_ 1462 TBM_Submit_ClimateSchd1 0;
BA_ "GenSigTimeoutTime_DMSM" SG_ 1462 TBM_Submit_ClimateSchd1 0;
BA_ "GenSigTimeoutTime_BSM" SG_ 1462 TBM_Submit_ClimateSchd1 0;
BA_ "GenSigTimeoutTime_BCM" SG_ 1462 TBM_Submit_ClimateSchd1 0;
BA_ "GenSigTimeoutTime_AGSM" SG_ 1462 TBM_Submit_ClimateSchd1 0;
BA_ "GenSigTimeoutTime_ADCAM" SG_ 1462 TBM_Submit_ClimateSchd1 0;
BA_ "GenSigSendType" SG_ 1462 TBM_Submit_ClimateSchd1 3;
BA_ "GenSigTimeoutTime_SGW" SG_ 1462 TBM_Enable_ClimateSchd2 0;
BA_ "GenSigTimeoutTime_RFHM" SG_ 1462 TBM_Enable_ClimateSchd2 0;
BA_ "GenSigTimeoutTime_MPAD" SG_ 1462 TBM_Enable_ClimateSchd2 0;
BA_ "GenSigTimeoutTime_IPC" SG_ 1462 TBM_Enable_ClimateSchd2 0;
BA_ "GenSigTimeoutTime_GNMM" SG_ 1462 TBM_Enable_ClimateSchd2 0;
BA_ "GenSigTimeoutTime_ESL" SG_ 1462 TBM_Enable_ClimateSchd2 0;
BA_ "GenSigTimeoutTime_ECM" SG_ 1462 TBM_Enable_ClimateSchd2 0;
BA_ "GenSigTimeoutTime_DTCM" SG_ 1462 TBM_Enable_ClimateSchd2 0;
BA_ "GenSigTimeoutTime_DMSM" SG_ 1462 TBM_Enable_ClimateSchd2 0;
BA_ "GenSigTimeoutTime_BSM" SG_ 1462 TBM_Enable_ClimateSchd2 0;
BA_ "GenSigTimeoutTime_BCM" SG_ 1462 TBM_Enable_ClimateSchd2 0;
BA_ "GenSigTimeoutTime_AGSM" SG_ 1462 TBM_Enable_ClimateSchd2 0;
BA_ "GenSigTimeoutTime_ADCAM" SG_ 1462 TBM_Enable_ClimateSchd2 0;
BA_ "GenSigSendType" SG_ 1462 TBM_Enable_ClimateSchd2 3;
BA_ "GenSigTimeoutTime_SGW" SG_ 1462 TBM_Enable_ClimateSchd1 0;
BA_ "GenSigTimeoutTime_RFHM" SG_ 1462 TBM_Enable_ClimateSchd1 0;
BA_ "GenSigTimeoutTime_MPAD" SG_ 1462 TBM_Enable_ClimateSchd1 0;
BA_ "GenSigTimeoutTime_IPC" SG_ 1462 TBM_Enable_ClimateSchd1 0;
BA_ "GenSigTimeoutTime_GNMM" SG_ 1462 TBM_Enable_ClimateSchd1 0;
BA_ "GenSigTimeoutTime_ESL" SG_ 1462 TBM_Enable_ClimateSchd1 0;
BA_ "GenSigTimeoutTime_ECM" SG_ 1462 TBM_Enable_ClimateSchd1 0;
BA_ "GenSigTimeoutTime_DTCM" SG_ 1462 TBM_Enable_ClimateSchd1 0;
BA_ "GenSigTimeoutTime_DMSM" SG_ 1462 TBM_Enable_ClimateSchd1 0;
BA_ "GenSigTimeoutTime_BSM" SG_ 1462 TBM_Enable_ClimateSchd1 0;
BA_ "GenSigTimeoutTime_BCM" SG_ 1462 TBM_Enable_ClimateSchd1 0;
BA_ "GenSigTimeoutTime_AGSM" SG_ 1462 TBM_Enable_ClimateSchd1 0;
BA_ "GenSigTimeoutTime_ADCAM" SG_ 1462 TBM_Enable_ClimateSchd1 0;
BA_ "GenSigSendType" SG_ 1462 TBM_Enable_ClimateSchd1 3;
BA_ "GenSigTimeoutTime_SGW" SG_ 1462 TBM_ClimateSchd2_Departure_Min 0;
BA_ "GenSigTimeoutTime_RFHM" SG_ 1462 TBM_ClimateSchd2_Departure_Min 0;
BA_ "GenSigTimeoutTime_MPAD" SG_ 1462 TBM_ClimateSchd2_Departure_Min 0;
BA_ "GenSigTimeoutTime_IPC" SG_ 1462 TBM_ClimateSchd2_Departure_Min 0;
BA_ "GenSigTimeoutTime_GNMM" SG_ 1462 TBM_ClimateSchd2_Departure_Min 0;
BA_ "GenSigTimeoutTime_ESL" SG_ 1462 TBM_ClimateSchd2_Departure_Min 0;
BA_ "GenSigTimeoutTime_ECM" SG_ 1462 TBM_ClimateSchd2_Departure_Min 0;
BA_ "GenSigTimeoutTime_DTCM" SG_ 1462 TBM_ClimateSchd2_Departure_Min 0;
BA_ "GenSigTimeoutTime_DMSM" SG_ 1462 TBM_ClimateSchd2_Departure_Min 0;
BA_ "GenSigTimeoutTime_BSM" SG_ 1462 TBM_ClimateSchd2_Departure_Min 0;
BA_ "GenSigTimeoutTime_BCM" SG_ 1462 TBM_ClimateSchd2_Departure_Min 0;
BA_ "GenSigTimeoutTime_AGSM" SG_ 1462 TBM_ClimateSchd2_Departure_Min 0;
BA_ "GenSigTimeoutTime_ADCAM" SG_ 1462 TBM_ClimateSchd2_Departure_Min 0;
BA_ "GenSigSendType" SG_ 1462 TBM_ClimateSchd2_Departure_Min 3;
BA_ "GenSigTimeoutTime_SGW" SG_ 1462 TBM_ClimateSchd2_Departure_Hr 0;
BA_ "GenSigTimeoutTime_RFHM" SG_ 1462 TBM_ClimateSchd2_Departure_Hr 0;
BA_ "GenSigTimeoutTime_MPAD" SG_ 1462 TBM_ClimateSchd2_Departure_Hr 0;
BA_ "GenSigTimeoutTime_IPC" SG_ 1462 TBM_ClimateSchd2_Departure_Hr 0;
BA_ "GenSigTimeoutTime_GNMM" SG_ 1462 TBM_ClimateSchd2_Departure_Hr 0;
BA_ "GenSigTimeoutTime_ESL" SG_ 1462 TBM_ClimateSchd2_Departure_Hr 0;
BA_ "GenSigTimeoutTime_ECM" SG_ 1462 TBM_ClimateSchd2_Departure_Hr 0;
BA_ "GenSigTimeoutTime_DTCM" SG_ 1462 TBM_ClimateSchd2_Departure_Hr 0;
BA_ "GenSigTimeoutTime_DMSM" SG_ 1462 TBM_ClimateSchd2_Departure_Hr 0;
BA_ "GenSigTimeoutTime_BSM" SG_ 1462 TBM_ClimateSchd2_Departure_Hr 0;
BA_ "GenSigTimeoutTime_BCM" SG_ 1462 TBM_ClimateSchd2_Departure_Hr 0;
BA_ "GenSigTimeoutTime_AGSM" SG_ 1462 TBM_ClimateSchd2_Departure_Hr 0;
BA_ "GenSigTimeoutTime_ADCAM" SG_ 1462 TBM_ClimateSchd2_Departure_Hr 0;
BA_ "GenSigSendType" SG_ 1462 TBM_ClimateSchd2_Departure_Hr 3;
BA_ "GenSigTimeoutTime_SGW" SG_ 1462 TBM_ClimateSchd2_Day 0;
BA_ "GenSigTimeoutTime_RFHM" SG_ 1462 TBM_ClimateSchd2_Day 0;
BA_ "GenSigTimeoutTime_MPAD" SG_ 1462 TBM_ClimateSchd2_Day 0;
BA_ "GenSigTimeoutTime_IPC" SG_ 1462 TBM_ClimateSchd2_Day 0;
BA_ "GenSigTimeoutTime_GNMM" SG_ 1462 TBM_ClimateSchd2_Day 0;
BA_ "GenSigTimeoutTime_ESL" SG_ 1462 TBM_ClimateSchd2_Day 0;
BA_ "GenSigTimeoutTime_ECM" SG_ 1462 TBM_ClimateSchd2_Day 0;
BA_ "GenSigTimeoutTime_DTCM" SG_ 1462 TBM_ClimateSchd2_Day 0;
BA_ "GenSigTimeoutTime_DMSM" SG_ 1462 TBM_ClimateSchd2_Day 0;
BA_ "GenSigTimeoutTime_BSM" SG_ 1462 TBM_ClimateSchd2_Day 0;
BA_ "GenSigTimeoutTime_BCM" SG_ 1462 TBM_ClimateSchd2_Day 0;
BA_ "GenSigTimeoutTime_AGSM" SG_ 1462 TBM_ClimateSchd2_Day 0;
BA_ "GenSigTimeoutTime_ADCAM" SG_ 1462 TBM_ClimateSchd2_Day 0;
BA_ "GenSigSendType" SG_ 1462 TBM_ClimateSchd2_Day 3;
BA_ "GenSigTimeoutTime_SGW" SG_ 1462 TBM_ClimateSchd1_Departure_Min 0;
BA_ "GenSigTimeoutTime_RFHM" SG_ 1462 TBM_ClimateSchd1_Departure_Min 0;
BA_ "GenSigTimeoutTime_MPAD" SG_ 1462 TBM_ClimateSchd1_Departure_Min 0;
BA_ "GenSigTimeoutTime_IPC" SG_ 1462 TBM_ClimateSchd1_Departure_Min 0;
BA_ "GenSigTimeoutTime_GNMM" SG_ 1462 TBM_ClimateSchd1_Departure_Min 0;
BA_ "GenSigTimeoutTime_ESL" SG_ 1462 TBM_ClimateSchd1_Departure_Min 0;
BA_ "GenSigTimeoutTime_ECM" SG_ 1462 TBM_ClimateSchd1_Departure_Min 0;
BA_ "GenSigTimeoutTime_DTCM" SG_ 1462 TBM_ClimateSchd1_Departure_Min 0;
BA_ "GenSigTimeoutTime_DMSM" SG_ 1462 TBM_ClimateSchd1_Departure_Min 0;
BA_ "GenSigTimeoutTime_BSM" SG_ 1462 TBM_ClimateSchd1_Departure_Min 0;
BA_ "GenSigTimeoutTime_BCM" SG_ 1462 TBM_ClimateSchd1_Departure_Min 0;
BA_ "GenSigTimeoutTime_AGSM" SG_ 1462 TBM_ClimateSchd1_Departure_Min 0;
BA_ "GenSigTimeoutTime_ADCAM" SG_ 1462 TBM_ClimateSchd1_Departure_Min 0;
BA_ "GenSigSendType" SG_ 1462 TBM_ClimateSchd1_Departure_Min 3;
BA_ "GenSigTimeoutTime_SGW" SG_ 1462 TBM_ClimateSchd1_Departure_Hr 0;
BA_ "GenSigTimeoutTime_RFHM" SG_ 1462 TBM_ClimateSchd1_Departure_Hr 0;
BA_ "GenSigTimeoutTime_MPAD" SG_ 1462 TBM_ClimateSchd1_Departure_Hr 0;
BA_ "GenSigTimeoutTime_IPC" SG_ 1462 TBM_ClimateSchd1_Departure_Hr 0;
BA_ "GenSigTimeoutTime_GNMM" SG_ 1462 TBM_ClimateSchd1_Departure_Hr 0;
BA_ "GenSigTimeoutTime_ESL" SG_ 1462 TBM_ClimateSchd1_Departure_Hr 0;
BA_ "GenSigTimeoutTime_ECM" SG_ 1462 TBM_ClimateSchd1_Departure_Hr 0;
BA_ "GenSigTimeoutTime_DTCM" SG_ 1462 TBM_ClimateSchd1_Departure_Hr 0;
BA_ "GenSigTimeoutTime_DMSM" SG_ 1462 TBM_ClimateSchd1_Departure_Hr 0;
BA_ "GenSigTimeoutTime_BSM" SG_ 1462 TBM_ClimateSchd1_Departure_Hr 0;
BA_ "GenSigTimeoutTime_BCM" SG_ 1462 TBM_ClimateSchd1_Departure_Hr 0;
BA_ "GenSigTimeoutTime_AGSM" SG_ 1462 TBM_ClimateSchd1_Departure_Hr 0;
BA_ "GenSigTimeoutTime_ADCAM" SG_ 1462 TBM_ClimateSchd1_Departure_Hr 0;
BA_ "GenSigSendType" SG_ 1462 TBM_ClimateSchd1_Departure_Hr 3;
BA_ "GenSigTimeoutTime_SGW" SG_ 1462 TBM_ClimateSchd1_Day 0;
BA_ "GenSigTimeoutTime_RFHM" SG_ 1462 TBM_ClimateSchd1_Day 0;
BA_ "GenSigTimeoutTime_MPAD" SG_ 1462 TBM_ClimateSchd1_Day 0;
BA_ "GenSigTimeoutTime_IPC" SG_ 1462 TBM_ClimateSchd1_Day 0;
BA_ "GenSigTimeoutTime_GNMM" SG_ 1462 TBM_ClimateSchd1_Day 0;
BA_ "GenSigTimeoutTime_ESL" SG_ 1462 TBM_ClimateSchd1_Day 0;
BA_ "GenSigTimeoutTime_ECM" SG_ 1462 TBM_ClimateSchd1_Day 0;
BA_ "GenSigTimeoutTime_DTCM" SG_ 1462 TBM_ClimateSchd1_Day 0;
BA_ "GenSigTimeoutTime_DMSM" SG_ 1462 TBM_ClimateSchd1_Day 0;
BA_ "GenSigTimeoutTime_BSM" SG_ 1462 TBM_ClimateSchd1_Day 0;
BA_ "GenSigTimeoutTime_BCM" SG_ 1462 TBM_ClimateSchd1_Day 0;
BA_ "GenSigTimeoutTime_AGSM" SG_ 1462 TBM_ClimateSchd1_Day 0;
BA_ "GenSigTimeoutTime_ADCAM" SG_ 1462 TBM_ClimateSchd1_Day 0;
BA_ "GenSigSendType" SG_ 1462 TBM_ClimateSchd1_Day 3;
BA_ "GenSigTimeoutTime_SGW" SG_ 1462 TBM_AllowClimateSchd2 0;
BA_ "GenSigTimeoutTime_RFHM" SG_ 1462 TBM_AllowClimateSchd2 0;
BA_ "GenSigTimeoutTime_MPAD" SG_ 1462 TBM_AllowClimateSchd2 0;
BA_ "GenSigTimeoutTime_IPC" SG_ 1462 TBM_AllowClimateSchd2 0;
BA_ "GenSigTimeoutTime_GNMM" SG_ 1462 TBM_AllowClimateSchd2 0;
BA_ "GenSigTimeoutTime_ESL" SG_ 1462 TBM_AllowClimateSchd2 0;
BA_ "GenSigTimeoutTime_ECM" SG_ 1462 TBM_AllowClimateSchd2 0;
BA_ "GenSigTimeoutTime_DTCM" SG_ 1462 TBM_AllowClimateSchd2 0;
BA_ "GenSigTimeoutTime_DMSM" SG_ 1462 TBM_AllowClimateSchd2 0;
BA_ "GenSigTimeoutTime_BSM" SG_ 1462 TBM_AllowClimateSchd2 0;
BA_ "GenSigTimeoutTime_BCM" SG_ 1462 TBM_AllowClimateSchd2 0;
BA_ "GenSigTimeoutTime_AGSM" SG_ 1462 TBM_AllowClimateSchd2 0;
BA_ "GenSigTimeoutTime_ADCAM" SG_ 1462 TBM_AllowClimateSchd2 0;
BA_ "GenSigSendType" SG_ 1462 TBM_AllowClimateSchd2 3;
BA_ "GenSigTimeoutTime_SGW" SG_ 1462 TBM_AllowClimateSchd1 0;
BA_ "GenSigTimeoutTime_RFHM" SG_ 1462 TBM_AllowClimateSchd1 0;
BA_ "GenSigTimeoutTime_MPAD" SG_ 1462 TBM_AllowClimateSchd1 0;
BA_ "GenSigTimeoutTime_IPC" SG_ 1462 TBM_AllowClimateSchd1 0;
BA_ "GenSigTimeoutTime_GNMM" SG_ 1462 TBM_AllowClimateSchd1 0;
BA_ "GenSigTimeoutTime_ESL" SG_ 1462 TBM_AllowClimateSchd1 0;
BA_ "GenSigTimeoutTime_ECM" SG_ 1462 TBM_AllowClimateSchd1 0;
BA_ "GenSigTimeoutTime_DTCM" SG_ 1462 TBM_AllowClimateSchd1 0;
BA_ "GenSigTimeoutTime_DMSM" SG_ 1462 TBM_AllowClimateSchd1 0;
BA_ "GenSigTimeoutTime_BSM" SG_ 1462 TBM_AllowClimateSchd1 0;
BA_ "GenSigTimeoutTime_BCM" SG_ 1462 TBM_AllowClimateSchd1 0;
BA_ "GenSigTimeoutTime_AGSM" SG_ 1462 TBM_AllowClimateSchd1 0;
BA_ "GenSigTimeoutTime_ADCAM" SG_ 1462 TBM_AllowClimateSchd1 0;
BA_ "GenSigSendType" SG_ 1462 TBM_AllowClimateSchd1 3;
BA_ "GenSigTimeoutTime_SGW" SG_ 1462 Climate_TBM_Cabin_Temp2 0;
BA_ "GenSigTimeoutTime_RFHM" SG_ 1462 Climate_TBM_Cabin_Temp2 0;
BA_ "GenSigTimeoutTime_MPAD" SG_ 1462 Climate_TBM_Cabin_Temp2 0;
BA_ "GenSigTimeoutTime_IPC" SG_ 1462 Climate_TBM_Cabin_Temp2 0;
BA_ "GenSigTimeoutTime_GNMM" SG_ 1462 Climate_TBM_Cabin_Temp2 0;
BA_ "GenSigTimeoutTime_ESL" SG_ 1462 Climate_TBM_Cabin_Temp2 0;
BA_ "GenSigTimeoutTime_ECM" SG_ 1462 Climate_TBM_Cabin_Temp2 0;
BA_ "GenSigTimeoutTime_DTCM" SG_ 1462 Climate_TBM_Cabin_Temp2 0;
BA_ "GenSigTimeoutTime_DMSM" SG_ 1462 Climate_TBM_Cabin_Temp2 0;
BA_ "GenSigTimeoutTime_BSM" SG_ 1462 Climate_TBM_Cabin_Temp2 0;
BA_ "GenSigTimeoutTime_BCM" SG_ 1462 Climate_TBM_Cabin_Temp2 0;
BA_ "GenSigTimeoutTime_AGSM" SG_ 1462 Climate_TBM_Cabin_Temp2 0;
BA_ "GenSigTimeoutTime_ADCAM" SG_ 1462 Climate_TBM_Cabin_Temp2 0;
BA_ "GenSigSendType" SG_ 1462 Climate_TBM_Cabin_Temp2 3;
BA_ "GenSigStartValue" SG_ 1462 Climate_TBM_Cabin_Temp2 12;
BA_ "GenSigTimeoutTime_SGW" SG_ 1462 Climate_TBM_Cabin_Temp1 0;
BA_ "GenSigTimeoutTime_RFHM" SG_ 1462 Climate_TBM_Cabin_Temp1 0;
BA_ "GenSigTimeoutTime_MPAD" SG_ 1462 Climate_TBM_Cabin_Temp1 0;
BA_ "GenSigTimeoutTime_IPC" SG_ 1462 Climate_TBM_Cabin_Temp1 0;
BA_ "GenSigTimeoutTime_GNMM" SG_ 1462 Climate_TBM_Cabin_Temp1 0;
BA_ "GenSigTimeoutTime_ESL" SG_ 1462 Climate_TBM_Cabin_Temp1 0;
BA_ "GenSigTimeoutTime_ECM" SG_ 1462 Climate_TBM_Cabin_Temp1 0;
BA_ "GenSigTimeoutTime_DTCM" SG_ 1462 Climate_TBM_Cabin_Temp1 0;
BA_ "GenSigTimeoutTime_DMSM" SG_ 1462 Climate_TBM_Cabin_Temp1 0;
BA_ "GenSigTimeoutTime_BSM" SG_ 1462 Climate_TBM_Cabin_Temp1 0;
BA_ "GenSigTimeoutTime_BCM" SG_ 1462 Climate_TBM_Cabin_Temp1 0;
BA_ "GenSigTimeoutTime_AGSM" SG_ 1462 Climate_TBM_Cabin_Temp1 0;
BA_ "GenSigTimeoutTime_ADCAM" SG_ 1462 Climate_TBM_Cabin_Temp1 0;
BA_ "GenSigSendType" SG_ 1462 Climate_TBM_Cabin_Temp1 3;
BA_ "GenSigStartValue" SG_ 1462 Climate_TBM_Cabin_Temp1 12;
BA_ "GenSigTimeoutTime_SGW" SG_ 1471 Submit_ClimateSchd2 0;
BA_ "GenSigTimeoutTime_RFHM" SG_ 1471 Submit_ClimateSchd2 0;
BA_ "GenSigTimeoutTime_MPAD" SG_ 1471 Submit_ClimateSchd2 0;
BA_ "GenSigTimeoutTime_IPC" SG_ 1471 Submit_ClimateSchd2 0;
BA_ "GenSigTimeoutTime_GNMM" SG_ 1471 Submit_ClimateSchd2 0;
BA_ "GenSigTimeoutTime_ESL" SG_ 1471 Submit_ClimateSchd2 0;
BA_ "GenSigTimeoutTime_ECM" SG_ 1471 Submit_ClimateSchd2 0;
BA_ "GenSigTimeoutTime_DTCM" SG_ 1471 Submit_ClimateSchd2 0;
BA_ "GenSigTimeoutTime_DMSM" SG_ 1471 Submit_ClimateSchd2 0;
BA_ "GenSigTimeoutTime_BSM" SG_ 1471 Submit_ClimateSchd2 0;
BA_ "GenSigTimeoutTime_BCM" SG_ 1471 Submit_ClimateSchd2 0;
BA_ "GenSigTimeoutTime_AGSM" SG_ 1471 Submit_ClimateSchd2 0;
BA_ "GenSigTimeoutTime_ADCAM" SG_ 1471 Submit_ClimateSchd2 0;
BA_ "GenSigSendType" SG_ 1471 Submit_ClimateSchd2 3;
BA_ "GenSigTimeoutTime_SGW" SG_ 1471 Submit_ClimateSchd1 0;
BA_ "GenSigTimeoutTime_RFHM" SG_ 1471 Submit_ClimateSchd1 0;
BA_ "GenSigTimeoutTime_MPAD" SG_ 1471 Submit_ClimateSchd1 0;
BA_ "GenSigTimeoutTime_IPC" SG_ 1471 Submit_ClimateSchd1 0;
BA_ "GenSigTimeoutTime_GNMM" SG_ 1471 Submit_ClimateSchd1 0;
BA_ "GenSigTimeoutTime_ESL" SG_ 1471 Submit_ClimateSchd1 0;
BA_ "GenSigTimeoutTime_ECM" SG_ 1471 Submit_ClimateSchd1 0;
BA_ "GenSigTimeoutTime_DTCM" SG_ 1471 Submit_ClimateSchd1 0;
BA_ "GenSigTimeoutTime_DMSM" SG_ 1471 Submit_ClimateSchd1 0;
BA_ "GenSigTimeoutTime_BSM" SG_ 1471 Submit_ClimateSchd1 0;
BA_ "GenSigTimeoutTime_BCM" SG_ 1471 Submit_ClimateSchd1 0;
BA_ "GenSigTimeoutTime_AGSM" SG_ 1471 Submit_ClimateSchd1 0;
BA_ "GenSigTimeoutTime_ADCAM" SG_ 1471 Submit_ClimateSchd1 0;
BA_ "GenSigSendType" SG_ 1471 Submit_ClimateSchd1 3;
BA_ "GenSigTimeoutTime_SGW" SG_ 1471 Enable_ClimateSchd2 0;
BA_ "GenSigTimeoutTime_RFHM" SG_ 1471 Enable_ClimateSchd2 0;
BA_ "GenSigTimeoutTime_MPAD" SG_ 1471 Enable_ClimateSchd2 0;
BA_ "GenSigTimeoutTime_IPC" SG_ 1471 Enable_ClimateSchd2 0;
BA_ "GenSigTimeoutTime_GNMM" SG_ 1471 Enable_ClimateSchd2 0;
BA_ "GenSigTimeoutTime_ESL" SG_ 1471 Enable_ClimateSchd2 0;
BA_ "GenSigTimeoutTime_ECM" SG_ 1471 Enable_ClimateSchd2 0;
BA_ "GenSigTimeoutTime_DTCM" SG_ 1471 Enable_ClimateSchd2 0;
BA_ "GenSigTimeoutTime_DMSM" SG_ 1471 Enable_ClimateSchd2 0;
BA_ "GenSigTimeoutTime_BSM" SG_ 1471 Enable_ClimateSchd2 0;
BA_ "GenSigTimeoutTime_BCM" SG_ 1471 Enable_ClimateSchd2 0;
BA_ "GenSigTimeoutTime_AGSM" SG_ 1471 Enable_ClimateSchd2 0;
BA_ "GenSigTimeoutTime_ADCAM" SG_ 1471 Enable_ClimateSchd2 0;
BA_ "GenSigSendType" SG_ 1471 Enable_ClimateSchd2 3;
BA_ "GenSigTimeoutTime_SGW" SG_ 1471 Enable_ClimateSchd1 0;
BA_ "GenSigTimeoutTime_RFHM" SG_ 1471 Enable_ClimateSchd1 0;
BA_ "GenSigTimeoutTime_MPAD" SG_ 1471 Enable_ClimateSchd1 0;
BA_ "GenSigTimeoutTime_IPC" SG_ 1471 Enable_ClimateSchd1 0;
BA_ "GenSigTimeoutTime_GNMM" SG_ 1471 Enable_ClimateSchd1 0;
BA_ "GenSigTimeoutTime_ESL" SG_ 1471 Enable_ClimateSchd1 0;
BA_ "GenSigTimeoutTime_ECM" SG_ 1471 Enable_ClimateSchd1 0;
BA_ "GenSigTimeoutTime_DTCM" SG_ 1471 Enable_ClimateSchd1 0;
BA_ "GenSigTimeoutTime_DMSM" SG_ 1471 Enable_ClimateSchd1 0;
BA_ "GenSigTimeoutTime_BSM" SG_ 1471 Enable_ClimateSchd1 0;
BA_ "GenSigTimeoutTime_BCM" SG_ 1471 Enable_ClimateSchd1 0;
BA_ "GenSigTimeoutTime_AGSM" SG_ 1471 Enable_ClimateSchd1 0;
BA_ "GenSigTimeoutTime_ADCAM" SG_ 1471 Enable_ClimateSchd1 0;
BA_ "GenSigSendType" SG_ 1471 Enable_ClimateSchd1 3;
BA_ "GenSigTimeoutTime_SGW" SG_ 1471 ClimateSchd2_Departure_Min 0;
BA_ "GenSigTimeoutTime_RFHM" SG_ 1471 ClimateSchd2_Departure_Min 0;
BA_ "GenSigTimeoutTime_MPAD" SG_ 1471 ClimateSchd2_Departure_Min 0;
BA_ "GenSigTimeoutTime_IPC" SG_ 1471 ClimateSchd2_Departure_Min 0;
BA_ "GenSigTimeoutTime_GNMM" SG_ 1471 ClimateSchd2_Departure_Min 0;
BA_ "GenSigTimeoutTime_ESL" SG_ 1471 ClimateSchd2_Departure_Min 0;
BA_ "GenSigTimeoutTime_ECM" SG_ 1471 ClimateSchd2_Departure_Min 0;
BA_ "GenSigTimeoutTime_DTCM" SG_ 1471 ClimateSchd2_Departure_Min 0;
BA_ "GenSigTimeoutTime_DMSM" SG_ 1471 ClimateSchd2_Departure_Min 0;
BA_ "GenSigTimeoutTime_BSM" SG_ 1471 ClimateSchd2_Departure_Min 0;
BA_ "GenSigTimeoutTime_BCM" SG_ 1471 ClimateSchd2_Departure_Min 0;
BA_ "GenSigTimeoutTime_AGSM" SG_ 1471 ClimateSchd2_Departure_Min 0;
BA_ "GenSigTimeoutTime_ADCAM" SG_ 1471 ClimateSchd2_Departure_Min 0;
BA_ "GenSigSendType" SG_ 1471 ClimateSchd2_Departure_Min 3;
BA_ "GenSigTimeoutTime_SGW" SG_ 1471 ClimateSchd2_Departure_Hr 0;
BA_ "GenSigTimeoutTime_RFHM" SG_ 1471 ClimateSchd2_Departure_Hr 0;
BA_ "GenSigTimeoutTime_MPAD" SG_ 1471 ClimateSchd2_Departure_Hr 0;
BA_ "GenSigTimeoutTime_IPC" SG_ 1471 ClimateSchd2_Departure_Hr 0;
BA_ "GenSigTimeoutTime_GNMM" SG_ 1471 ClimateSchd2_Departure_Hr 0;
BA_ "GenSigTimeoutTime_ESL" SG_ 1471 ClimateSchd2_Departure_Hr 0;
BA_ "GenSigTimeoutTime_ECM" SG_ 1471 ClimateSchd2_Departure_Hr 0;
BA_ "GenSigTimeoutTime_DTCM" SG_ 1471 ClimateSchd2_Departure_Hr 0;
BA_ "GenSigTimeoutTime_DMSM" SG_ 1471 ClimateSchd2_Departure_Hr 0;
BA_ "GenSigTimeoutTime_BSM" SG_ 1471 ClimateSchd2_Departure_Hr 0;
BA_ "GenSigTimeoutTime_BCM" SG_ 1471 ClimateSchd2_Departure_Hr 0;
BA_ "GenSigTimeoutTime_AGSM" SG_ 1471 ClimateSchd2_Departure_Hr 0;
BA_ "GenSigTimeoutTime_ADCAM" SG_ 1471 ClimateSchd2_Departure_Hr 0;
BA_ "GenSigSendType" SG_ 1471 ClimateSchd2_Departure_Hr 3;
BA_ "GenSigTimeoutTime_SGW" SG_ 1471 ClimateSchd2_Day 0;
BA_ "GenSigTimeoutTime_RFHM" SG_ 1471 ClimateSchd2_Day 0;
BA_ "GenSigTimeoutTime_MPAD" SG_ 1471 ClimateSchd2_Day 0;
BA_ "GenSigTimeoutTime_IPC" SG_ 1471 ClimateSchd2_Day 0;
BA_ "GenSigTimeoutTime_GNMM" SG_ 1471 ClimateSchd2_Day 0;
BA_ "GenSigTimeoutTime_ESL" SG_ 1471 ClimateSchd2_Day 0;
BA_ "GenSigTimeoutTime_ECM" SG_ 1471 ClimateSchd2_Day 0;
BA_ "GenSigTimeoutTime_DTCM" SG_ 1471 ClimateSchd2_Day 0;
BA_ "GenSigTimeoutTime_DMSM" SG_ 1471 ClimateSchd2_Day 0;
BA_ "GenSigTimeoutTime_BSM" SG_ 1471 ClimateSchd2_Day 0;
BA_ "GenSigTimeoutTime_BCM" SG_ 1471 ClimateSchd2_Day 0;
BA_ "GenSigTimeoutTime_AGSM" SG_ 1471 ClimateSchd2_Day 0;
BA_ "GenSigTimeoutTime_ADCAM" SG_ 1471 ClimateSchd2_Day 0;
BA_ "GenSigSendType" SG_ 1471 ClimateSchd2_Day 3;
BA_ "GenSigTimeoutTime_SGW" SG_ 1471 ClimateSchd1_Departure_Min 0;
BA_ "GenSigTimeoutTime_RFHM" SG_ 1471 ClimateSchd1_Departure_Min 0;
BA_ "GenSigTimeoutTime_MPAD" SG_ 1471 ClimateSchd1_Departure_Min 0;
BA_ "GenSigTimeoutTime_IPC" SG_ 1471 ClimateSchd1_Departure_Min 0;
BA_ "GenSigTimeoutTime_GNMM" SG_ 1471 ClimateSchd1_Departure_Min 0;
BA_ "GenSigTimeoutTime_ESL" SG_ 1471 ClimateSchd1_Departure_Min 0;
BA_ "GenSigTimeoutTime_ECM" SG_ 1471 ClimateSchd1_Departure_Min 0;
BA_ "GenSigTimeoutTime_DTCM" SG_ 1471 ClimateSchd1_Departure_Min 0;
BA_ "GenSigTimeoutTime_DMSM" SG_ 1471 ClimateSchd1_Departure_Min 0;
BA_ "GenSigTimeoutTime_BSM" SG_ 1471 ClimateSchd1_Departure_Min 0;
BA_ "GenSigTimeoutTime_BCM" SG_ 1471 ClimateSchd1_Departure_Min 0;
BA_ "GenSigTimeoutTime_AGSM" SG_ 1471 ClimateSchd1_Departure_Min 0;
BA_ "GenSigTimeoutTime_ADCAM" SG_ 1471 ClimateSchd1_Departure_Min 0;
BA_ "GenSigSendType" SG_ 1471 ClimateSchd1_Departure_Min 3;
BA_ "GenSigTimeoutTime_SGW" SG_ 1471 ClimateSchd1_Departure_Hr 0;
BA_ "GenSigTimeoutTime_RFHM" SG_ 1471 ClimateSchd1_Departure_Hr 0;
BA_ "GenSigTimeoutTime_MPAD" SG_ 1471 ClimateSchd1_Departure_Hr 0;
BA_ "GenSigTimeoutTime_IPC" SG_ 1471 ClimateSchd1_Departure_Hr 0;
BA_ "GenSigTimeoutTime_GNMM" SG_ 1471 ClimateSchd1_Departure_Hr 0;
BA_ "GenSigTimeoutTime_ESL" SG_ 1471 ClimateSchd1_Departure_Hr 0;
BA_ "GenSigTimeoutTime_ECM" SG_ 1471 ClimateSchd1_Departure_Hr 0;
BA_ "GenSigTimeoutTime_DTCM" SG_ 1471 ClimateSchd1_Departure_Hr 0;
BA_ "GenSigTimeoutTime_DMSM" SG_ 1471 ClimateSchd1_Departure_Hr 0;
BA_ "GenSigTimeoutTime_BSM" SG_ 1471 ClimateSchd1_Departure_Hr 0;
BA_ "GenSigTimeoutTime_BCM" SG_ 1471 ClimateSchd1_Departure_Hr 0;
BA_ "GenSigTimeoutTime_AGSM" SG_ 1471 ClimateSchd1_Departure_Hr 0;
BA_ "GenSigTimeoutTime_ADCAM" SG_ 1471 ClimateSchd1_Departure_Hr 0;
BA_ "GenSigSendType" SG_ 1471 ClimateSchd1_Departure_Hr 3;
BA_ "GenSigTimeoutTime_SGW" SG_ 1471 ClimateSchd1_Day 0;
BA_ "GenSigTimeoutTime_RFHM" SG_ 1471 ClimateSchd1_Day 0;
BA_ "GenSigTimeoutTime_MPAD" SG_ 1471 ClimateSchd1_Day 0;
BA_ "GenSigTimeoutTime_IPC" SG_ 1471 ClimateSchd1_Day 0;
BA_ "GenSigTimeoutTime_GNMM" SG_ 1471 ClimateSchd1_Day 0;
BA_ "GenSigTimeoutTime_ESL" SG_ 1471 ClimateSchd1_Day 0;
BA_ "GenSigTimeoutTime_ECM" SG_ 1471 ClimateSchd1_Day 0;
BA_ "GenSigTimeoutTime_DTCM" SG_ 1471 ClimateSchd1_Day 0;
BA_ "GenSigTimeoutTime_DMSM" SG_ 1471 ClimateSchd1_Day 0;
BA_ "GenSigTimeoutTime_BSM" SG_ 1471 ClimateSchd1_Day 0;
BA_ "GenSigTimeoutTime_BCM" SG_ 1471 ClimateSchd1_Day 0;
BA_ "GenSigTimeoutTime_AGSM" SG_ 1471 ClimateSchd1_Day 0;
BA_ "GenSigTimeoutTime_ADCAM" SG_ 1471 ClimateSchd1_Day 0;
BA_ "GenSigSendType" SG_ 1471 ClimateSchd1_Day 3;
BA_ "GenSigTimeoutTime_SGW" SG_ 1471 Climate_Cabin_Temp2 0;
BA_ "GenSigTimeoutTime_RFHM" SG_ 1471 Climate_Cabin_Temp2 0;
BA_ "GenSigTimeoutTime_MPAD" SG_ 1471 Climate_Cabin_Temp2 0;
BA_ "GenSigTimeoutTime_IPC" SG_ 1471 Climate_Cabin_Temp2 0;
BA_ "GenSigTimeoutTime_GNMM" SG_ 1471 Climate_Cabin_Temp2 0;
BA_ "GenSigTimeoutTime_ESL" SG_ 1471 Climate_Cabin_Temp2 0;
BA_ "GenSigTimeoutTime_ECM" SG_ 1471 Climate_Cabin_Temp2 0;
BA_ "GenSigTimeoutTime_DTCM" SG_ 1471 Climate_Cabin_Temp2 0;
BA_ "GenSigTimeoutTime_DMSM" SG_ 1471 Climate_Cabin_Temp2 0;
BA_ "GenSigTimeoutTime_BSM" SG_ 1471 Climate_Cabin_Temp2 0;
BA_ "GenSigTimeoutTime_BCM" SG_ 1471 Climate_Cabin_Temp2 0;
BA_ "GenSigTimeoutTime_AGSM" SG_ 1471 Climate_Cabin_Temp2 0;
BA_ "GenSigTimeoutTime_ADCAM" SG_ 1471 Climate_Cabin_Temp2 0;
BA_ "GenSigSendType" SG_ 1471 Climate_Cabin_Temp2 3;
BA_ "GenSigStartValue" SG_ 1471 Climate_Cabin_Temp2 12;
BA_ "GenSigTimeoutTime_SGW" SG_ 1471 Climate_Cabin_Temp1 0;
BA_ "GenSigTimeoutTime_RFHM" SG_ 1471 Climate_Cabin_Temp1 0;
BA_ "GenSigTimeoutTime_MPAD" SG_ 1471 Climate_Cabin_Temp1 0;
BA_ "GenSigTimeoutTime_IPC" SG_ 1471 Climate_Cabin_Temp1 0;
BA_ "GenSigTimeoutTime_GNMM" SG_ 1471 Climate_Cabin_Temp1 0;
BA_ "GenSigTimeoutTime_ESL" SG_ 1471 Climate_Cabin_Temp1 0;
BA_ "GenSigTimeoutTime_ECM" SG_ 1471 Climate_Cabin_Temp1 0;
BA_ "GenSigTimeoutTime_DTCM" SG_ 1471 Climate_Cabin_Temp1 0;
BA_ "GenSigTimeoutTime_DMSM" SG_ 1471 Climate_Cabin_Temp1 0;
BA_ "GenSigTimeoutTime_BSM" SG_ 1471 Climate_Cabin_Temp1 0;
BA_ "GenSigTimeoutTime_BCM" SG_ 1471 Climate_Cabin_Temp1 0;
BA_ "GenSigTimeoutTime_AGSM" SG_ 1471 Climate_Cabin_Temp1 0;
BA_ "GenSigTimeoutTime_ADCAM" SG_ 1471 Climate_Cabin_Temp1 0;
BA_ "GenSigSendType" SG_ 1471 Climate_Cabin_Temp1 3;
BA_ "GenSigStartValue" SG_ 1471 Climate_Cabin_Temp1 12;
BA_ "GenSigTimeoutTime_SGW" SG_ 1471 AllowClimateSchd2 0;
BA_ "GenSigTimeoutTime_RFHM" SG_ 1471 AllowClimateSchd2 0;
BA_ "GenSigTimeoutTime_MPAD" SG_ 1471 AllowClimateSchd2 0;
BA_ "GenSigTimeoutTime_IPC" SG_ 1471 AllowClimateSchd2 0;
BA_ "GenSigTimeoutTime_GNMM" SG_ 1471 AllowClimateSchd2 0;
BA_ "GenSigTimeoutTime_ESL" SG_ 1471 AllowClimateSchd2 0;
BA_ "GenSigTimeoutTime_ECM" SG_ 1471 AllowClimateSchd2 0;
BA_ "GenSigTimeoutTime_DTCM" SG_ 1471 AllowClimateSchd2 0;
BA_ "GenSigTimeoutTime_DMSM" SG_ 1471 AllowClimateSchd2 0;
BA_ "GenSigTimeoutTime_BSM" SG_ 1471 AllowClimateSchd2 0;
BA_ "GenSigTimeoutTime_BCM" SG_ 1471 AllowClimateSchd2 0;
BA_ "GenSigTimeoutTime_AGSM" SG_ 1471 AllowClimateSchd2 0;
BA_ "GenSigTimeoutTime_ADCAM" SG_ 1471 AllowClimateSchd2 0;
BA_ "GenSigSendType" SG_ 1471 AllowClimateSchd2 3;
BA_ "GenSigTimeoutTime_ECM" SG_ 1471 AllowClimateSchd1 0;
BA_ "GenSigTimeoutTime_DTCM" SG_ 1471 AllowClimateSchd1 0;
BA_ "GenSigTimeoutTime_DMSM" SG_ 1471 AllowClimateSchd1 0;
BA_ "GenSigTimeoutTime_BSM" SG_ 1471 AllowClimateSchd1 0;
BA_ "GenSigTimeoutTime_BCM" SG_ 1471 AllowClimateSchd1 0;
BA_ "GenSigTimeoutTime_AGSM" SG_ 1471 AllowClimateSchd1 0;
BA_ "GenSigTimeoutTime_ADCAM" SG_ 1471 AllowClimateSchd1 0;
BA_ "GenSigSendType" SG_ 1471 AllowClimateSchd1 3;
BA_ "GenSigTimeoutTime_SGW" SG_ 1471 AllowClimateSchd1 0;
BA_ "GenSigTimeoutTime_RFHM" SG_ 1471 AllowClimateSchd1 0;
BA_ "GenSigTimeoutTime_MPAD" SG_ 1471 AllowClimateSchd1 0;
BA_ "GenSigTimeoutTime_IPC" SG_ 1471 AllowClimateSchd1 0;
BA_ "GenSigTimeoutTime_GNMM" SG_ 1471 AllowClimateSchd1 0;
BA_ "GenSigTimeoutTime_ESL" SG_ 1471 AllowClimateSchd1 0;
BA_ "GenSigTimeoutTime_RFHM" SG_ 1468 Enable_ClimateSchd2_Sts 0;
BA_ "GenSigTimeoutTime_MPAD" SG_ 1468 Enable_ClimateSchd2_Sts 0;
BA_ "GenSigTimeoutTime_IPC" SG_ 1468 Enable_ClimateSchd2_Sts 0;
BA_ "GenSigTimeoutTime_GNMM" SG_ 1468 Enable_ClimateSchd2_Sts 0;
BA_ "GenSigTimeoutTime_EVCU2" SG_ 1468 Enable_ClimateSchd2_Sts 0;
BA_ "GenSigTimeoutTime_ESL" SG_ 1468 Enable_ClimateSchd2_Sts 0;
BA_ "GenSigTimeoutTime_ECM" SG_ 1468 Enable_ClimateSchd2_Sts 0;
BA_ "GenSigTimeoutTime_DTCM" SG_ 1468 Enable_ClimateSchd2_Sts 0;
BA_ "GenSigTimeoutTime_DMSM" SG_ 1468 Enable_ClimateSchd2_Sts 0;
BA_ "GenSigTimeoutTime_BSM" SG_ 1468 Enable_ClimateSchd2_Sts 0;
BA_ "GenSigTimeoutTime_BCM" SG_ 1468 Enable_ClimateSchd2_Sts 0;
BA_ "GenSigTimeoutTime_AGSM" SG_ 1468 Enable_ClimateSchd2_Sts 0;
BA_ "GenSigTimeoutTime_ADCAM" SG_ 1468 Enable_ClimateSchd2_Sts 0;
BA_ "GenSigSendType" SG_ 1468 Enable_ClimateSchd2_Sts 3;
BA_ "GenSigTimeoutTime_RFHM" SG_ 1468 Enable_ClimateSchd1_Sts 0;
BA_ "GenSigTimeoutTime_MPAD" SG_ 1468 Enable_ClimateSchd1_Sts 0;
BA_ "GenSigTimeoutTime_IPC" SG_ 1468 Enable_ClimateSchd1_Sts 0;
BA_ "GenSigTimeoutTime_GNMM" SG_ 1468 Enable_ClimateSchd1_Sts 0;
BA_ "GenSigTimeoutTime_EVCU2" SG_ 1468 Enable_ClimateSchd1_Sts 0;
BA_ "GenSigTimeoutTime_ESL" SG_ 1468 Enable_ClimateSchd1_Sts 0;
BA_ "GenSigTimeoutTime_ECM" SG_ 1468 Enable_ClimateSchd1_Sts 0;
BA_ "GenSigTimeoutTime_DTCM" SG_ 1468 Enable_ClimateSchd1_Sts 0;
BA_ "GenSigTimeoutTime_DMSM" SG_ 1468 Enable_ClimateSchd1_Sts 0;
BA_ "GenSigTimeoutTime_BSM" SG_ 1468 Enable_ClimateSchd1_Sts 0;
BA_ "GenSigTimeoutTime_BCM" SG_ 1468 Enable_ClimateSchd1_Sts 0;
BA_ "GenSigTimeoutTime_AGSM" SG_ 1468 Enable_ClimateSchd1_Sts 0;
BA_ "GenSigTimeoutTime_ADCAM" SG_ 1468 Enable_ClimateSchd1_Sts 0;
BA_ "GenSigSendType" SG_ 1468 Enable_ClimateSchd1_Sts 3;
BA_ "GenSigTimeoutTime_RFHM" SG_ 1468 ClimateSchd2_Departure_Min_Sts 0;
BA_ "GenSigTimeoutTime_MPAD" SG_ 1468 ClimateSchd2_Departure_Min_Sts 0;
BA_ "GenSigTimeoutTime_IPC" SG_ 1468 ClimateSchd2_Departure_Min_Sts 0;
BA_ "GenSigTimeoutTime_GNMM" SG_ 1468 ClimateSchd2_Departure_Min_Sts 0;
BA_ "GenSigTimeoutTime_EVCU2" SG_ 1468 ClimateSchd2_Departure_Min_Sts 0;
BA_ "GenSigTimeoutTime_ESL" SG_ 1468 ClimateSchd2_Departure_Min_Sts 0;
BA_ "GenSigTimeoutTime_ECM" SG_ 1468 ClimateSchd2_Departure_Min_Sts 0;
BA_ "GenSigTimeoutTime_DTCM" SG_ 1468 ClimateSchd2_Departure_Min_Sts 0;
BA_ "GenSigTimeoutTime_DMSM" SG_ 1468 ClimateSchd2_Departure_Min_Sts 0;
BA_ "GenSigTimeoutTime_BSM" SG_ 1468 ClimateSchd2_Departure_Min_Sts 0;
BA_ "GenSigTimeoutTime_BCM" SG_ 1468 ClimateSchd2_Departure_Min_Sts 0;
BA_ "GenSigTimeoutTime_AGSM" SG_ 1468 ClimateSchd2_Departure_Min_Sts 0;
BA_ "GenSigTimeoutTime_ADCAM" SG_ 1468 ClimateSchd2_Departure_Min_Sts 0;
BA_ "GenSigSendType" SG_ 1468 ClimateSchd2_Departure_Min_Sts 3;
BA_ "GenSigTimeoutTime_RFHM" SG_ 1468 ClimateSchd2_Departure_Hr_Sts 0;
BA_ "GenSigTimeoutTime_MPAD" SG_ 1468 ClimateSchd2_Departure_Hr_Sts 0;
BA_ "GenSigTimeoutTime_IPC" SG_ 1468 ClimateSchd2_Departure_Hr_Sts 0;
BA_ "GenSigTimeoutTime_GNMM" SG_ 1468 ClimateSchd2_Departure_Hr_Sts 0;
BA_ "GenSigTimeoutTime_EVCU2" SG_ 1468 ClimateSchd2_Departure_Hr_Sts 0;
BA_ "GenSigTimeoutTime_ESL" SG_ 1468 ClimateSchd2_Departure_Hr_Sts 0;
BA_ "GenSigTimeoutTime_ECM" SG_ 1468 ClimateSchd2_Departure_Hr_Sts 0;
BA_ "GenSigTimeoutTime_DTCM" SG_ 1468 ClimateSchd2_Departure_Hr_Sts 0;
BA_ "GenSigTimeoutTime_DMSM" SG_ 1468 ClimateSchd2_Departure_Hr_Sts 0;
BA_ "GenSigTimeoutTime_BSM" SG_ 1468 ClimateSchd2_Departure_Hr_Sts 0;
BA_ "GenSigTimeoutTime_BCM" SG_ 1468 ClimateSchd2_Departure_Hr_Sts 0;
BA_ "GenSigTimeoutTime_AGSM" SG_ 1468 ClimateSchd2_Departure_Hr_Sts 0;
BA_ "GenSigTimeoutTime_ADCAM" SG_ 1468 ClimateSchd2_Departure_Hr_Sts 0;
BA_ "GenSigSendType" SG_ 1468 ClimateSchd2_Departure_Hr_Sts 3;
BA_ "GenSigTimeoutTime_RFHM" SG_ 1468 ClimateSchd2_Day_Sts 0;
BA_ "GenSigTimeoutTime_MPAD" SG_ 1468 ClimateSchd2_Day_Sts 0;
BA_ "GenSigTimeoutTime_IPC" SG_ 1468 ClimateSchd2_Day_Sts 0;
BA_ "GenSigTimeoutTime_GNMM" SG_ 1468 ClimateSchd2_Day_Sts 0;
BA_ "GenSigTimeoutTime_EVCU2" SG_ 1468 ClimateSchd2_Day_Sts 0;
BA_ "GenSigTimeoutTime_ESL" SG_ 1468 ClimateSchd2_Day_Sts 0;
BA_ "GenSigTimeoutTime_ECM" SG_ 1468 ClimateSchd2_Day_Sts 0;
BA_ "GenSigTimeoutTime_DTCM" SG_ 1468 ClimateSchd2_Day_Sts 0;
BA_ "GenSigTimeoutTime_DMSM" SG_ 1468 ClimateSchd2_Day_Sts 0;
BA_ "GenSigTimeoutTime_BSM" SG_ 1468 ClimateSchd2_Day_Sts 0;
BA_ "GenSigTimeoutTime_BCM" SG_ 1468 ClimateSchd2_Day_Sts 0;
BA_ "GenSigTimeoutTime_AGSM" SG_ 1468 ClimateSchd2_Day_Sts 0;
BA_ "GenSigTimeoutTime_ADCAM" SG_ 1468 ClimateSchd2_Day_Sts 0;
BA_ "GenSigSendType" SG_ 1468 ClimateSchd2_Day_Sts 3;
BA_ "GenSigTimeoutTime_RFHM" SG_ 1468 ClimateSchd1_Departure_Min_Sts 0;
BA_ "GenSigTimeoutTime_MPAD" SG_ 1468 ClimateSchd1_Departure_Min_Sts 0;
BA_ "GenSigTimeoutTime_IPC" SG_ 1468 ClimateSchd1_Departure_Min_Sts 0;
BA_ "GenSigTimeoutTime_GNMM" SG_ 1468 ClimateSchd1_Departure_Min_Sts 0;
BA_ "GenSigTimeoutTime_EVCU2" SG_ 1468 ClimateSchd1_Departure_Min_Sts 0;
BA_ "GenSigTimeoutTime_ESL" SG_ 1468 ClimateSchd1_Departure_Min_Sts 0;
BA_ "GenSigTimeoutTime_ECM" SG_ 1468 ClimateSchd1_Departure_Min_Sts 0;
BA_ "GenSigTimeoutTime_DTCM" SG_ 1468 ClimateSchd1_Departure_Min_Sts 0;
BA_ "GenSigTimeoutTime_DMSM" SG_ 1468 ClimateSchd1_Departure_Min_Sts 0;
BA_ "GenSigTimeoutTime_BSM" SG_ 1468 ClimateSchd1_Departure_Min_Sts 0;
BA_ "GenSigTimeoutTime_BCM" SG_ 1468 ClimateSchd1_Departure_Min_Sts 0;
BA_ "GenSigTimeoutTime_AGSM" SG_ 1468 ClimateSchd1_Departure_Min_Sts 0;
BA_ "GenSigTimeoutTime_ADCAM" SG_ 1468 ClimateSchd1_Departure_Min_Sts 0;
BA_ "GenSigSendType" SG_ 1468 ClimateSchd1_Departure_Min_Sts 3;
BA_ "GenSigTimeoutTime_RFHM" SG_ 1468 ClimateSchd1_Departure_Hr_Sts 0;
BA_ "GenSigTimeoutTime_MPAD" SG_ 1468 ClimateSchd1_Departure_Hr_Sts 0;
BA_ "GenSigTimeoutTime_IPC" SG_ 1468 ClimateSchd1_Departure_Hr_Sts 0;
BA_ "GenSigTimeoutTime_GNMM" SG_ 1468 ClimateSchd1_Departure_Hr_Sts 0;
BA_ "GenSigTimeoutTime_EVCU2" SG_ 1468 ClimateSchd1_Departure_Hr_Sts 0;
BA_ "GenSigTimeoutTime_ESL" SG_ 1468 ClimateSchd1_Departure_Hr_Sts 0;
BA_ "GenSigTimeoutTime_ECM" SG_ 1468 ClimateSchd1_Departure_Hr_Sts 0;
BA_ "GenSigTimeoutTime_DTCM" SG_ 1468 ClimateSchd1_Departure_Hr_Sts 0;
BA_ "GenSigTimeoutTime_DMSM" SG_ 1468 ClimateSchd1_Departure_Hr_Sts 0;
BA_ "GenSigTimeoutTime_BSM" SG_ 1468 ClimateSchd1_Departure_Hr_Sts 0;
BA_ "GenSigTimeoutTime_BCM" SG_ 1468 ClimateSchd1_Departure_Hr_Sts 0;
BA_ "GenSigTimeoutTime_AGSM" SG_ 1468 ClimateSchd1_Departure_Hr_Sts 0;
BA_ "GenSigTimeoutTime_ADCAM" SG_ 1468 ClimateSchd1_Departure_Hr_Sts 0;
BA_ "GenSigSendType" SG_ 1468 ClimateSchd1_Departure_Hr_Sts 3;
BA_ "GenSigTimeoutTime_RFHM" SG_ 1468 ClimateSchd1_Day_Sts 0;
BA_ "GenSigTimeoutTime_MPAD" SG_ 1468 ClimateSchd1_Day_Sts 0;
BA_ "GenSigTimeoutTime_IPC" SG_ 1468 ClimateSchd1_Day_Sts 0;
BA_ "GenSigTimeoutTime_GNMM" SG_ 1468 ClimateSchd1_Day_Sts 0;
BA_ "GenSigTimeoutTime_EVCU2" SG_ 1468 ClimateSchd1_Day_Sts 0;
BA_ "GenSigTimeoutTime_ESL" SG_ 1468 ClimateSchd1_Day_Sts 0;
BA_ "GenSigTimeoutTime_ECM" SG_ 1468 ClimateSchd1_Day_Sts 0;
BA_ "GenSigTimeoutTime_DTCM" SG_ 1468 ClimateSchd1_Day_Sts 0;
BA_ "GenSigTimeoutTime_DMSM" SG_ 1468 ClimateSchd1_Day_Sts 0;
BA_ "GenSigTimeoutTime_BSM" SG_ 1468 ClimateSchd1_Day_Sts 0;
BA_ "GenSigTimeoutTime_BCM" SG_ 1468 ClimateSchd1_Day_Sts 0;
BA_ "GenSigTimeoutTime_AGSM" SG_ 1468 ClimateSchd1_Day_Sts 0;
BA_ "GenSigTimeoutTime_ADCAM" SG_ 1468 ClimateSchd1_Day_Sts 0;
BA_ "GenSigSendType" SG_ 1468 ClimateSchd1_Day_Sts 3;
BA_ "GenSigTimeoutTime_RFHM" SG_ 1468 Climate_Cabin_Temp2_Sts 0;
BA_ "GenSigTimeoutTime_MPAD" SG_ 1468 Climate_Cabin_Temp2_Sts 0;
BA_ "GenSigTimeoutTime_IPC" SG_ 1468 Climate_Cabin_Temp2_Sts 0;
BA_ "GenSigTimeoutTime_GNMM" SG_ 1468 Climate_Cabin_Temp2_Sts 0;
BA_ "GenSigTimeoutTime_EVCU2" SG_ 1468 Climate_Cabin_Temp2_Sts 0;
BA_ "GenSigTimeoutTime_ESL" SG_ 1468 Climate_Cabin_Temp2_Sts 0;
BA_ "GenSigTimeoutTime_ECM" SG_ 1468 Climate_Cabin_Temp2_Sts 0;
BA_ "GenSigTimeoutTime_DTCM" SG_ 1468 Climate_Cabin_Temp2_Sts 0;
BA_ "GenSigTimeoutTime_DMSM" SG_ 1468 Climate_Cabin_Temp2_Sts 0;
BA_ "GenSigTimeoutTime_BSM" SG_ 1468 Climate_Cabin_Temp2_Sts 0;
BA_ "GenSigTimeoutTime_BCM" SG_ 1468 Climate_Cabin_Temp2_Sts 0;
BA_ "GenSigTimeoutTime_AGSM" SG_ 1468 Climate_Cabin_Temp2_Sts 0;
BA_ "GenSigTimeoutTime_ADCAM" SG_ 1468 Climate_Cabin_Temp2_Sts 0;
BA_ "GenSigSendType" SG_ 1468 Climate_Cabin_Temp2_Sts 3;
BA_ "GenSigStartValue" SG_ 1468 Climate_Cabin_Temp2_Sts 12;
BA_ "GenSigTimeoutTime_RFHM" SG_ 1468 Climate_Cabin_Temp1_Sts 0;
BA_ "GenSigTimeoutTime_MPAD" SG_ 1468 Climate_Cabin_Temp1_Sts 0;
BA_ "GenSigTimeoutTime_IPC" SG_ 1468 Climate_Cabin_Temp1_Sts 0;
BA_ "GenSigTimeoutTime_GNMM" SG_ 1468 Climate_Cabin_Temp1_Sts 0;
BA_ "GenSigTimeoutTime_EVCU2" SG_ 1468 Climate_Cabin_Temp1_Sts 0;
BA_ "GenSigTimeoutTime_ESL" SG_ 1468 Climate_Cabin_Temp1_Sts 0;
BA_ "GenSigTimeoutTime_ECM" SG_ 1468 Climate_Cabin_Temp1_Sts 0;
BA_ "GenSigTimeoutTime_DTCM" SG_ 1468 Climate_Cabin_Temp1_Sts 0;
BA_ "GenSigTimeoutTime_DMSM" SG_ 1468 Climate_Cabin_Temp1_Sts 0;
BA_ "GenSigTimeoutTime_BSM" SG_ 1468 Climate_Cabin_Temp1_Sts 0;
BA_ "GenSigTimeoutTime_BCM" SG_ 1468 Climate_Cabin_Temp1_Sts 0;
BA_ "GenSigTimeoutTime_AGSM" SG_ 1468 Climate_Cabin_Temp1_Sts 0;
BA_ "GenSigTimeoutTime_ADCAM" SG_ 1468 Climate_Cabin_Temp1_Sts 0;
BA_ "GenSigSendType" SG_ 1468 Climate_Cabin_Temp1_Sts 3;
BA_ "GenSigStartValue" SG_ 1468 Climate_Cabin_Temp1_Sts 12;
BA_ "GenSigTimeoutTime_RFHM" SG_ 1468 AllowClimateSchd2_Sts 0;
BA_ "GenSigTimeoutTime_MPAD" SG_ 1468 AllowClimateSchd2_Sts 0;
BA_ "GenSigTimeoutTime_IPC" SG_ 1468 AllowClimateSchd2_Sts 0;
BA_ "GenSigTimeoutTime_GNMM" SG_ 1468 AllowClimateSchd2_Sts 0;
BA_ "GenSigTimeoutTime_EVCU2" SG_ 1468 AllowClimateSchd2_Sts 0;
BA_ "GenSigTimeoutTime_ESL" SG_ 1468 AllowClimateSchd2_Sts 0;
BA_ "GenSigTimeoutTime_ECM" SG_ 1468 AllowClimateSchd2_Sts 0;
BA_ "GenSigTimeoutTime_DTCM" SG_ 1468 AllowClimateSchd2_Sts 0;
BA_ "GenSigTimeoutTime_DMSM" SG_ 1468 AllowClimateSchd2_Sts 0;
BA_ "GenSigTimeoutTime_BSM" SG_ 1468 AllowClimateSchd2_Sts 0;
BA_ "GenSigTimeoutTime_BCM" SG_ 1468 AllowClimateSchd2_Sts 0;
BA_ "GenSigTimeoutTime_AGSM" SG_ 1468 AllowClimateSchd2_Sts 0;
BA_ "GenSigTimeoutTime_ADCAM" SG_ 1468 AllowClimateSchd2_Sts 0;
BA_ "GenSigSendType" SG_ 1468 AllowClimateSchd2_Sts 3;
BA_ "GenSigTimeoutTime_RFHM" SG_ 1468 AllowClimateSchd1_Sts 0;
BA_ "GenSigTimeoutTime_MPAD" SG_ 1468 AllowClimateSchd1_Sts 0;
BA_ "GenSigTimeoutTime_IPC" SG_ 1468 AllowClimateSchd1_Sts 0;
BA_ "GenSigTimeoutTime_GNMM" SG_ 1468 AllowClimateSchd1_Sts 0;
BA_ "GenSigTimeoutTime_EVCU2" SG_ 1468 AllowClimateSchd1_Sts 0;
BA_ "GenSigTimeoutTime_ESL" SG_ 1468 AllowClimateSchd1_Sts 0;
BA_ "GenSigTimeoutTime_ECM" SG_ 1468 AllowClimateSchd1_Sts 0;
BA_ "GenSigTimeoutTime_DTCM" SG_ 1468 AllowClimateSchd1_Sts 0;
BA_ "GenSigTimeoutTime_DMSM" SG_ 1468 AllowClimateSchd1_Sts 0;
BA_ "GenSigTimeoutTime_BSM" SG_ 1468 AllowClimateSchd1_Sts 0;
BA_ "GenSigTimeoutTime_BCM" SG_ 1468 AllowClimateSchd1_Sts 0;
BA_ "GenSigTimeoutTime_AGSM" SG_ 1468 AllowClimateSchd1_Sts 0;
BA_ "GenSigTimeoutTime_ADCAM" SG_ 1468 AllowClimateSchd1_Sts 0;
BA_ "GenSigSendType" SG_ 1468 AllowClimateSchd1_Sts 3;
BA_ "GenSigTimeoutTime_DTCM" SG_ 2654339257 StayActiveSource_FD09_WCPM2 0;
BA_ "GenSigTimeoutTime_ECM" SG_ 1442 SugSpeedMax 0;
BA_ "GenSigTimeoutTime_RFHM" SG_ 1853 APM_CtrlSts_Fbk 0;
BA_ "GenSigTimeoutTime_MPAD" SG_ 1853 APM_CtrlSts_Fbk 0;
BA_ "GenSigTimeoutTime_IPC" SG_ 1853 APM_CtrlSts_Fbk 0;
BA_ "GenSigTimeoutTime_GNMM" SG_ 1853 APM_CtrlSts_Fbk 0;
BA_ "GenSigTimeoutTime_EVCU2" SG_ 1853 APM_CtrlSts_Fbk 0;
BA_ "GenSigTimeoutTime_ESL" SG_ 1853 APM_CtrlSts_Fbk 0;
BA_ "GenSigTimeoutTime_ECM" SG_ 1853 APM_CtrlSts_Fbk 0;
BA_ "GenSigTimeoutTime_DTCM" SG_ 1853 APM_CtrlSts_Fbk 0;
BA_ "GenSigTimeoutTime_DMSM" SG_ 1853 APM_CtrlSts_Fbk 0;
BA_ "GenSigTimeoutTime_BSM" SG_ 1853 APM_CtrlSts_Fbk 0;
BA_ "GenSigTimeoutTime_BCM" SG_ 1853 APM_CtrlSts_Fbk 0;
BA_ "GenSigTimeoutTime_AGSM" SG_ 1853 APM_CtrlSts_Fbk 0;
BA_ "GenSigTimeoutTime_ADCAM" SG_ 1853 APM_CtrlSts_Fbk 0;
BA_ "GenSigTimeoutTime_RFHM" SG_ 1853 APM_FailureReason 0;
BA_ "GenSigTimeoutTime_MPAD" SG_ 1853 APM_FailureReason 0;
BA_ "GenSigTimeoutTime_IPC" SG_ 1853 APM_FailureReason 0;
BA_ "GenSigTimeoutTime_GNMM" SG_ 1853 APM_FailureReason 0;
BA_ "GenSigTimeoutTime_EVCU2" SG_ 1853 APM_FailureReason 0;
BA_ "GenSigTimeoutTime_ESL" SG_ 1853 APM_FailureReason 0;
BA_ "GenSigTimeoutTime_ECM" SG_ 1853 APM_FailureReason 0;
BA_ "GenSigTimeoutTime_DTCM" SG_ 1853 APM_FailureReason 0;
BA_ "GenSigTimeoutTime_DMSM" SG_ 1853 APM_FailureReason 0;
BA_ "GenSigTimeoutTime_BSM" SG_ 1853 APM_FailureReason 0;
BA_ "GenSigTimeoutTime_BCM" SG_ 1853 APM_FailureReason 0;
BA_ "GenSigTimeoutTime_AGSM" SG_ 1853 APM_FailureReason 0;
BA_ "GenSigTimeoutTime_ADCAM" SG_ 1853 APM_FailureReason 0;
BA_ "GenSigTimeoutTime_RFHM" SG_ 1853 APM_OutputPower 0;
BA_ "GenSigTimeoutTime_MPAD" SG_ 1853 APM_OutputPower 0;
BA_ "GenSigTimeoutTime_IPC" SG_ 1853 APM_OutputPower 0;
BA_ "GenSigTimeoutTime_GNMM" SG_ 1853 APM_OutputPower 0;
BA_ "GenSigTimeoutTime_EVCU2" SG_ 1853 APM_OutputPower 0;
BA_ "GenSigTimeoutTime_ESL" SG_ 1853 APM_OutputPower 0;
BA_ "GenSigTimeoutTime_ECM" SG_ 1853 APM_OutputPower 0;
BA_ "GenSigTimeoutTime_DTCM" SG_ 1853 APM_OutputPower 0;
BA_ "GenSigTimeoutTime_DMSM" SG_ 1853 APM_OutputPower 0;
BA_ "GenSigTimeoutTime_BSM" SG_ 1853 APM_OutputPower 0;
BA_ "GenSigTimeoutTime_BCM" SG_ 1853 APM_OutputPower 0;
BA_ "GenSigTimeoutTime_AGSM" SG_ 1853 APM_OutputPower 0;
BA_ "GenSigTimeoutTime_ADCAM" SG_ 1853 APM_OutputPower 0;
BA_ "GenSigTimeoutTime_SGW" SG_ 2651930736 Digit_09_SGW 0;
BA_ "GenSigTimeoutTime_RFHM" SG_ 2651930736 Digit_09_SGW 0;
BA_ "GenSigTimeoutTime_MPAD" SG_ 2651930736 Digit_09_SGW 0;
BA_ "GenSigTimeoutTime_IPC" SG_ 2651930736 Digit_09_SGW 0;
BA_ "GenSigTimeoutTime_GNMM" SG_ 2651930736 Digit_09_SGW 0;
BA_ "GenSigTimeoutTime_EVCU2" SG_ 2651930736 Digit_09_SGW 0;
BA_ "GenSigTimeoutTime_ESL" SG_ 2651930736 Digit_09_SGW 0;
BA_ "GenSigTimeoutTime_ECM" SG_ 2651930736 Digit_09_SGW 0;
BA_ "GenSigTimeoutTime_DTCM" SG_ 2651930736 Digit_09_SGW 0;
BA_ "GenSigTimeoutTime_DMSM" SG_ 2651930736 Digit_09_SGW 0;
BA_ "GenSigTimeoutTime_BSM" SG_ 2651930736 Digit_09_SGW 0;
BA_ "GenSigTimeoutTime_AGSM" SG_ 2651930736 Digit_09_SGW 0;
BA_ "GenSigTimeoutTime_SGW" SG_ 2651930736 Digit_10_SGW 0;
BA_ "GenSigTimeoutTime_RFHM" SG_ 2651930736 Digit_10_SGW 0;
BA_ "GenSigTimeoutTime_MPAD" SG_ 2651930736 Digit_10_SGW 0;
BA_ "GenSigTimeoutTime_IPC" SG_ 2651930736 Digit_10_SGW 0;
BA_ "GenSigTimeoutTime_GNMM" SG_ 2651930736 Digit_10_SGW 0;
BA_ "GenSigTimeoutTime_EVCU2" SG_ 2651930736 Digit_10_SGW 0;
BA_ "GenSigTimeoutTime_ESL" SG_ 2651930736 Digit_10_SGW 0;
BA_ "GenSigTimeoutTime_ECM" SG_ 2651930736 Digit_10_SGW 0;
BA_ "GenSigTimeoutTime_DTCM" SG_ 2651930736 Digit_10_SGW 0;
BA_ "GenSigTimeoutTime_DMSM" SG_ 2651930736 Digit_10_SGW 0;
BA_ "GenSigTimeoutTime_BSM" SG_ 2651930736 Digit_10_SGW 0;
BA_ "GenSigTimeoutTime_AGSM" SG_ 2651930736 Digit_10_SGW 0;
BA_ "GenSigTimeoutTime_ADCAM" SG_ 2651930736 Digit_10_SGW 0;
BA_ "GenSigTimeoutTime_GNMM" SG_ 2651930736 Digit_11_SGW 0;
BA_ "GenSigTimeoutTime_EVCU2" SG_ 2651930736 Digit_11_SGW 0;
BA_ "GenSigTimeoutTime_ESL" SG_ 2651930736 Digit_11_SGW 0;
BA_ "GenSigTimeoutTime_ECM" SG_ 2651930736 Digit_11_SGW 0;
BA_ "GenSigTimeoutTime_DTCM" SG_ 2651930736 Digit_11_SGW 0;
BA_ "GenSigTimeoutTime_DMSM" SG_ 2651930736 Digit_11_SGW 0;
BA_ "GenSigTimeoutTime_BSM" SG_ 2651930736 Digit_11_SGW 0;
BA_ "GenSigTimeoutTime_AGSM" SG_ 2651930736 Digit_11_SGW 0;
BA_ "GenSigTimeoutTime_ADCAM" SG_ 2651930736 Digit_11_SGW 0;
BA_ "GenSigTimeoutTime_SGW" SG_ 2651930736 Digit_11_SGW 0;
BA_ "GenSigTimeoutTime_RFHM" SG_ 2651930736 Digit_11_SGW 0;
BA_ "GenSigTimeoutTime_MPAD" SG_ 2651930736 Digit_11_SGW 0;
BA_ "GenSigTimeoutTime_IPC" SG_ 2651930736 Digit_11_SGW 0;
BA_ "GenSigTimeoutTime_ADCAM" SG_ 2651930736 Digit_09_SGW 0;
BA_ "GenSigTimeoutTime_SGW" SG_ 2651930736 Digit_08_SGW 0;
BA_ "GenSigTimeoutTime_RFHM" SG_ 2651930736 Digit_08_SGW 0;
BA_ "GenSigTimeoutTime_MPAD" SG_ 2651930736 Digit_08_SGW 0;
BA_ "GenSigTimeoutTime_IPC" SG_ 2651930736 Digit_08_SGW 0;
BA_ "GenSigTimeoutTime_GNMM" SG_ 2651930736 Digit_08_SGW 0;
BA_ "GenSigTimeoutTime_EVCU2" SG_ 2651930736 Digit_08_SGW 0;
BA_ "GenSigTimeoutTime_ESL" SG_ 2651930736 Digit_08_SGW 0;
BA_ "GenSigTimeoutTime_ECM" SG_ 2651930736 Digit_08_SGW 0;
BA_ "GenSigTimeoutTime_DTCM" SG_ 2651930736 Digit_08_SGW 0;
BA_ "GenSigTimeoutTime_DMSM" SG_ 2651930736 Digit_08_SGW 0;
BA_ "GenSigTimeoutTime_BSM" SG_ 2651930736 Digit_08_SGW 0;
BA_ "GenSigTimeoutTime_AGSM" SG_ 2651930736 Digit_08_SGW 0;
BA_ "GenSigTimeoutTime_ADCAM" SG_ 2651930736 Digit_08_SGW 0;
BA_ "GenSigTimeoutTime_SGW" SG_ 2651930736 Digit_04_SGW 0;
BA_ "GenSigTimeoutTime_RFHM" SG_ 2651930736 Digit_04_SGW 0;
BA_ "GenSigTimeoutTime_MPAD" SG_ 2651930736 Digit_04_SGW 0;
BA_ "GenSigTimeoutTime_IPC" SG_ 2651930736 Digit_04_SGW 0;
BA_ "GenSigTimeoutTime_GNMM" SG_ 2651930736 Digit_04_SGW 0;
BA_ "GenSigTimeoutTime_EVCU2" SG_ 2651930736 Digit_04_SGW 0;
BA_ "GenSigTimeoutTime_ESL" SG_ 2651930736 Digit_04_SGW 0;
BA_ "GenSigTimeoutTime_ECM" SG_ 2651930736 Digit_04_SGW 0;
BA_ "GenSigTimeoutTime_DTCM" SG_ 2651930736 Digit_04_SGW 0;
BA_ "GenSigTimeoutTime_DMSM" SG_ 2651930736 Digit_04_SGW 0;
BA_ "GenSigTimeoutTime_BSM" SG_ 2651930736 Digit_04_SGW 0;
BA_ "GenSigTimeoutTime_AGSM" SG_ 2651930736 Digit_04_SGW 0;
BA_ "GenSigTimeoutTime_ADCAM" SG_ 2651930736 Digit_04_SGW 0;
BA_ "GenSigTimeoutTime_SGW" SG_ 2651930736 Digit_05_SGW 0;
BA_ "GenSigTimeoutTime_RFHM" SG_ 2651930736 Digit_05_SGW 0;
BA_ "GenSigTimeoutTime_MPAD" SG_ 2651930736 Digit_05_SGW 0;
BA_ "GenSigTimeoutTime_IPC" SG_ 2651930736 Digit_05_SGW 0;
BA_ "GenSigTimeoutTime_GNMM" SG_ 2651930736 Digit_05_SGW 0;
BA_ "GenSigTimeoutTime_EVCU2" SG_ 2651930736 Digit_05_SGW 0;
BA_ "GenSigTimeoutTime_ESL" SG_ 2651930736 Digit_05_SGW 0;
BA_ "GenSigTimeoutTime_ECM" SG_ 2651930736 Digit_05_SGW 0;
BA_ "GenSigTimeoutTime_DTCM" SG_ 2651930736 Digit_05_SGW 0;
BA_ "GenSigTimeoutTime_DMSM" SG_ 2651930736 Digit_05_SGW 0;
BA_ "GenSigTimeoutTime_BSM" SG_ 2651930736 Digit_05_SGW 0;
BA_ "GenSigTimeoutTime_AGSM" SG_ 2651930736 Digit_05_SGW 0;
BA_ "GenSigTimeoutTime_ADCAM" SG_ 2651930736 Digit_05_SGW 0;
BA_ "GenSigTimeoutTime_SGW" SG_ 2651930736 Digit_06_SGW 0;
BA_ "GenSigTimeoutTime_RFHM" SG_ 2651930736 Digit_06_SGW 0;
BA_ "GenSigTimeoutTime_MPAD" SG_ 2651930736 Digit_06_SGW 0;
BA_ "GenSigTimeoutTime_IPC" SG_ 2651930736 Digit_06_SGW 0;
BA_ "GenSigTimeoutTime_GNMM" SG_ 2651930736 Digit_06_SGW 0;
BA_ "GenSigTimeoutTime_EVCU2" SG_ 2651930736 Digit_06_SGW 0;
BA_ "GenSigTimeoutTime_ESL" SG_ 2651930736 Digit_06_SGW 0;
BA_ "GenSigTimeoutTime_ECM" SG_ 2651930736 Digit_06_SGW 0;
BA_ "GenSigTimeoutTime_DTCM" SG_ 2651930736 Digit_06_SGW 0;
BA_ "GenSigTimeoutTime_DMSM" SG_ 2651930736 Digit_06_SGW 0;
BA_ "GenSigTimeoutTime_BSM" SG_ 2651930736 Digit_06_SGW 0;
BA_ "GenSigTimeoutTime_AGSM" SG_ 2651930736 Digit_06_SGW 0;
BA_ "GenSigTimeoutTime_ADCAM" SG_ 2651930736 Digit_06_SGW 0;
BA_ "GenSigTimeoutTime_SGW" SG_ 2651930736 Digit_07_SGW 0;
BA_ "GenSigTimeoutTime_RFHM" SG_ 2651930736 Digit_07_SGW 0;
BA_ "GenSigTimeoutTime_MPAD" SG_ 2651930736 Digit_07_SGW 0;
BA_ "GenSigTimeoutTime_IPC" SG_ 2651930736 Digit_07_SGW 0;
BA_ "GenSigTimeoutTime_GNMM" SG_ 2651930736 Digit_07_SGW 0;
BA_ "GenSigTimeoutTime_EVCU2" SG_ 2651930736 Digit_07_SGW 0;
BA_ "GenSigTimeoutTime_ESL" SG_ 2651930736 Digit_07_SGW 0;
BA_ "GenSigTimeoutTime_ECM" SG_ 2651930736 Digit_07_SGW 0;
BA_ "GenSigTimeoutTime_DTCM" SG_ 2651930736 Digit_07_SGW 0;
BA_ "GenSigTimeoutTime_DMSM" SG_ 2651930736 Digit_07_SGW 0;
BA_ "GenSigTimeoutTime_BSM" SG_ 2651930736 Digit_07_SGW 0;
BA_ "GenSigTimeoutTime_AGSM" SG_ 2651930736 Digit_07_SGW 0;
BA_ "GenSigTimeoutTime_ADCAM" SG_ 2651930736 Digit_07_SGW 0;
BA_ "GenSigTimeoutTime_SGW" SG_ 2651930736 Digit_01_SGW 0;
BA_ "GenSigTimeoutTime_RFHM" SG_ 2651930736 Digit_01_SGW 0;
BA_ "GenSigTimeoutTime_MPAD" SG_ 2651930736 Digit_01_SGW 0;
BA_ "GenSigTimeoutTime_IPC" SG_ 2651930736 Digit_01_SGW 0;
BA_ "GenSigTimeoutTime_GNMM" SG_ 2651930736 Digit_01_SGW 0;
BA_ "GenSigTimeoutTime_EVCU2" SG_ 2651930736 Digit_01_SGW 0;
BA_ "GenSigTimeoutTime_ESL" SG_ 2651930736 Digit_01_SGW 0;
BA_ "GenSigTimeoutTime_ECM" SG_ 2651930736 Digit_01_SGW 0;
BA_ "GenSigTimeoutTime_DTCM" SG_ 2651930736 Digit_01_SGW 0;
BA_ "GenSigTimeoutTime_DMSM" SG_ 2651930736 Digit_01_SGW 0;
BA_ "GenSigTimeoutTime_BSM" SG_ 2651930736 Digit_01_SGW 0;
BA_ "GenSigTimeoutTime_AGSM" SG_ 2651930736 Digit_01_SGW 0;
BA_ "GenSigTimeoutTime_ADCAM" SG_ 2651930736 Digit_01_SGW 0;
BA_ "GenSigSendType" SG_ 2651930736 Digit_01_SGW 1;
BA_ "GenSigTimeoutTime_SGW" SG_ 2651930736 Digit_02_SGW 0;
BA_ "GenSigTimeoutTime_RFHM" SG_ 2651930736 Digit_02_SGW 0;
BA_ "GenSigTimeoutTime_MPAD" SG_ 2651930736 Digit_02_SGW 0;
BA_ "GenSigTimeoutTime_IPC" SG_ 2651930736 Digit_02_SGW 0;
BA_ "GenSigTimeoutTime_GNMM" SG_ 2651930736 Digit_02_SGW 0;
BA_ "GenSigTimeoutTime_EVCU2" SG_ 2651930736 Digit_02_SGW 0;
BA_ "GenSigTimeoutTime_ESL" SG_ 2651930736 Digit_02_SGW 0;
BA_ "GenSigTimeoutTime_ECM" SG_ 2651930736 Digit_02_SGW 0;
BA_ "GenSigTimeoutTime_DTCM" SG_ 2651930736 Digit_02_SGW 0;
BA_ "GenSigTimeoutTime_DMSM" SG_ 2651930736 Digit_02_SGW 0;
BA_ "GenSigTimeoutTime_BSM" SG_ 2651930736 Digit_02_SGW 0;
BA_ "GenSigTimeoutTime_AGSM" SG_ 2651930736 Digit_02_SGW 0;
BA_ "GenSigTimeoutTime_ADCAM" SG_ 2651930736 Digit_02_SGW 0;
BA_ "GenSigTimeoutTime_SGW" SG_ 2651930736 Digit_03_SGW 0;
BA_ "GenSigTimeoutTime_RFHM" SG_ 2651930736 Digit_03_SGW 0;
BA_ "GenSigTimeoutTime_MPAD" SG_ 2651930736 Digit_03_SGW 0;
BA_ "GenSigTimeoutTime_IPC" SG_ 2651930736 Digit_03_SGW 0;
BA_ "GenSigTimeoutTime_GNMM" SG_ 2651930736 Digit_03_SGW 0;
BA_ "GenSigTimeoutTime_EVCU2" SG_ 2651930736 Digit_03_SGW 0;
BA_ "GenSigTimeoutTime_ESL" SG_ 2651930736 Digit_03_SGW 0;
BA_ "GenSigTimeoutTime_ECM" SG_ 2651930736 Digit_03_SGW 0;
BA_ "GenSigTimeoutTime_DTCM" SG_ 2651930736 Digit_03_SGW 0;
BA_ "GenSigTimeoutTime_DMSM" SG_ 2651930736 Digit_03_SGW 0;
BA_ "GenSigTimeoutTime_BSM" SG_ 2651930736 Digit_03_SGW 0;
BA_ "GenSigTimeoutTime_AGSM" SG_ 2651930736 Digit_03_SGW 0;
BA_ "GenSigTimeoutTime_ADCAM" SG_ 2651930736 Digit_03_SGW 0;
BA_ "GenSigTimeoutTime_RFHM" SG_ 1426 DC_EstChargeTime1 0;
BA_ "GenSigTimeoutTime_MPAD" SG_ 1426 DC_EstChargeTime1 0;
BA_ "GenSigTimeoutTime_GNMM" SG_ 1426 DC_EstChargeTime1 0;
BA_ "GenSigTimeoutTime_EVCU2" SG_ 1426 DC_EstChargeTime1 0;
BA_ "GenSigTimeoutTime_ESL" SG_ 1426 DC_EstChargeTime1 0;
BA_ "GenSigTimeoutTime_ECM" SG_ 1426 DC_EstChargeTime1 0;
BA_ "GenSigTimeoutTime_DTCM" SG_ 1426 DC_EstChargeTime1 0;
BA_ "GenSigTimeoutTime_DMSM" SG_ 1426 DC_EstChargeTime1 0;
BA_ "GenSigTimeoutTime_BSM" SG_ 1426 DC_EstChargeTime1 0;
BA_ "GenSigTimeoutTime_BCM" SG_ 1426 DC_EstChargeTime1 0;
BA_ "GenSigTimeoutTime_AGSM" SG_ 1426 DC_EstChargeTime1 0;
BA_ "GenSigTimeoutTime_ADCAM" SG_ 1426 DC_EstChargeTime1 0;
BA_ "GenSigSendType" SG_ 1426 DC_EstChargeTime1 3;
BA_ "GenSigTimeoutTime_SGW" SG_ 1426 VDCM_PopUpMessage5 0;
BA_ "GenSigTimeoutTime_RFHM" SG_ 1426 VDCM_PopUpMessage5 0;
BA_ "GenSigTimeoutTime_MPAD" SG_ 1426 VDCM_PopUpMessage5 0;
BA_ "GenSigTimeoutTime_GNMM" SG_ 1426 VDCM_PopUpMessage5 0;
BA_ "GenSigTimeoutTime_EVCU2" SG_ 1426 VDCM_PopUpMessage5 0;
BA_ "GenSigTimeoutTime_ESL" SG_ 1426 VDCM_PopUpMessage5 0;
BA_ "GenSigTimeoutTime_ECM" SG_ 1426 VDCM_PopUpMessage5 0;
BA_ "GenSigTimeoutTime_DTCM" SG_ 1426 VDCM_PopUpMessage5 0;
BA_ "GenSigTimeoutTime_DMSM" SG_ 1426 VDCM_PopUpMessage5 0;
BA_ "GenSigTimeoutTime_BSM" SG_ 1426 VDCM_PopUpMessage5 0;
BA_ "GenSigTimeoutTime_BCM" SG_ 1426 VDCM_PopUpMessage5 0;
BA_ "GenSigTimeoutTime_AGSM" SG_ 1426 VDCM_PopUpMessage5 0;
BA_ "GenSigTimeoutTime_ADCAM" SG_ 1426 VDCM_PopUpMessage5 0;
BA_ "GenSigSendType" SG_ 1426 VDCM_PopUpMessage5 3;
BA_ "GenSigTimeoutTime_RFHM" SG_ 1426 EstRange 0;
BA_ "GenSigTimeoutTime_MPAD" SG_ 1426 EstRange 0;
BA_ "GenSigTimeoutTime_GNMM" SG_ 1426 EstRange 0;
BA_ "GenSigTimeoutTime_EVCU2" SG_ 1426 EstRange 0;
BA_ "GenSigTimeoutTime_ESL" SG_ 1426 EstRange 0;
BA_ "GenSigTimeoutTime_ECM" SG_ 1426 EstRange 0;
BA_ "GenSigTimeoutTime_DTCM" SG_ 1426 EstRange 0;
BA_ "GenSigTimeoutTime_DMSM" SG_ 1426 EstRange 0;
BA_ "GenSigTimeoutTime_BSM" SG_ 1426 EstRange 0;
BA_ "GenSigTimeoutTime_BCM" SG_ 1426 EstRange 0;
BA_ "GenSigTimeoutTime_AGSM" SG_ 1426 EstRange 0;
BA_ "GenSigTimeoutTime_ADCAM" SG_ 1426 EstRange 0;
BA_ "GenSigSendType" SG_ 1426 EstRange 3;
BA_ "GenSigStartValue" SG_ 1426 EstRange 2047;
BA_ "GenSigTimeoutTime_RFHM" SG_ 1426 DC_EstChargeTime2 0;
BA_ "GenSigTimeoutTime_MPAD" SG_ 1426 DC_EstChargeTime2 0;
BA_ "GenSigTimeoutTime_GNMM" SG_ 1426 DC_EstChargeTime2 0;
BA_ "GenSigTimeoutTime_EVCU2" SG_ 1426 DC_EstChargeTime2 0;
BA_ "GenSigTimeoutTime_ESL" SG_ 1426 DC_EstChargeTime2 0;
BA_ "GenSigTimeoutTime_ECM" SG_ 1426 DC_EstChargeTime2 0;
BA_ "GenSigTimeoutTime_DTCM" SG_ 1426 DC_EstChargeTime2 0;
BA_ "GenSigTimeoutTime_DMSM" SG_ 1426 DC_EstChargeTime2 0;
BA_ "GenSigTimeoutTime_BSM" SG_ 1426 DC_EstChargeTime2 0;
BA_ "GenSigTimeoutTime_BCM" SG_ 1426 DC_EstChargeTime2 0;
BA_ "GenSigTimeoutTime_AGSM" SG_ 1426 DC_EstChargeTime2 0;
BA_ "GenSigTimeoutTime_ADCAM" SG_ 1426 DC_EstChargeTime2 0;
BA_ "GenSigSendType" SG_ 1426 DC_EstChargeTime2 3;
BA_ "GenSigTimeoutTime_SGW" SG_ 1426 VDCM_PopUpMessage7 0;
BA_ "GenSigTimeoutTime_RFHM" SG_ 1426 VDCM_PopUpMessage7 0;
BA_ "GenSigTimeoutTime_MPAD" SG_ 1426 VDCM_PopUpMessage7 0;
BA_ "GenSigTimeoutTime_GNMM" SG_ 1426 VDCM_PopUpMessage7 0;
BA_ "GenSigTimeoutTime_EVCU2" SG_ 1426 VDCM_PopUpMessage7 0;
BA_ "GenSigTimeoutTime_ESL" SG_ 1426 VDCM_PopUpMessage7 0;
BA_ "GenSigTimeoutTime_ECM" SG_ 1426 VDCM_PopUpMessage7 0;
BA_ "GenSigTimeoutTime_DTCM" SG_ 1426 VDCM_PopUpMessage7 0;
BA_ "GenSigTimeoutTime_DMSM" SG_ 1426 VDCM_PopUpMessage7 0;
BA_ "GenSigTimeoutTime_BSM" SG_ 1426 VDCM_PopUpMessage7 0;
BA_ "GenSigTimeoutTime_BCM" SG_ 1426 VDCM_PopUpMessage7 0;
BA_ "GenSigTimeoutTime_AGSM" SG_ 1426 VDCM_PopUpMessage7 0;
BA_ "GenSigTimeoutTime_ADCAM" SG_ 1426 VDCM_PopUpMessage7 0;
BA_ "GenSigSendType" SG_ 1426 VDCM_PopUpMessage7 3;
BA_ "GenSigTimeoutTime_RFHM" SG_ 1426 Est_Range_ChrgStopTime 0;
BA_ "GenSigTimeoutTime_MPAD" SG_ 1426 Est_Range_ChrgStopTime 0;
BA_ "GenSigTimeoutTime_IPC" SG_ 1426 Est_Range_ChrgStopTime 0;
BA_ "GenSigTimeoutTime_GNMM" SG_ 1426 Est_Range_ChrgStopTime 0;
BA_ "GenSigTimeoutTime_EVCU2" SG_ 1426 Est_Range_ChrgStopTime 0;
BA_ "GenSigTimeoutTime_ESL" SG_ 1426 Est_Range_ChrgStopTime 0;
BA_ "GenSigTimeoutTime_ECM" SG_ 1426 Est_Range_ChrgStopTime 0;
BA_ "GenSigTimeoutTime_DTCM" SG_ 1426 Est_Range_ChrgStopTime 0;
BA_ "GenSigTimeoutTime_DMSM" SG_ 1426 Est_Range_ChrgStopTime 0;
BA_ "GenSigTimeoutTime_BSM" SG_ 1426 Est_Range_ChrgStopTime 0;
BA_ "GenSigTimeoutTime_BCM" SG_ 1426 Est_Range_ChrgStopTime 0;
BA_ "GenSigTimeoutTime_AGSM" SG_ 1426 Est_Range_ChrgStopTime 0;
BA_ "GenSigTimeoutTime_ADCAM" SG_ 1426 Est_Range_ChrgStopTime 0;
BA_ "GenSigSendType" SG_ 1426 Est_Range_ChrgStopTime 3;
BA_ "GenSigTimeoutTime_SGW" SG_ 1426 ThermalRunaway_Alert 0;
BA_ "GenSigTimeoutTime_RFHM" SG_ 1426 ThermalRunaway_Alert 0;
BA_ "GenSigTimeoutTime_MPAD" SG_ 1426 ThermalRunaway_Alert 0;
BA_ "GenSigTimeoutTime_IPC" SG_ 1426 ThermalRunaway_Alert 0;
BA_ "GenSigTimeoutTime_GNMM" SG_ 1426 ThermalRunaway_Alert 0;
BA_ "GenSigTimeoutTime_EVCU2" SG_ 1426 ThermalRunaway_Alert 0;
BA_ "GenSigTimeoutTime_ESL" SG_ 1426 ThermalRunaway_Alert 0;
BA_ "GenSigTimeoutTime_ECM" SG_ 1426 ThermalRunaway_Alert 0;
BA_ "GenSigTimeoutTime_DTCM" SG_ 1426 ThermalRunaway_Alert 0;
BA_ "GenSigTimeoutTime_DMSM" SG_ 1426 ThermalRunaway_Alert 0;
BA_ "GenSigTimeoutTime_BSM" SG_ 1426 ThermalRunaway_Alert 0;
BA_ "GenSigTimeoutTime_BCM" SG_ 1426 ThermalRunaway_Alert 0;
BA_ "GenSigTimeoutTime_AGSM" SG_ 1426 ThermalRunaway_Alert 0;
BA_ "GenSigTimeoutTime_ADCAM" SG_ 1426 ThermalRunaway_Alert 0;
BA_ "GenSigSendType" SG_ 1426 ThermalRunaway_Alert 3;
BA_ "GenSigTimeoutTime_SGW" SG_ 1426 MessageCounter_VDCM_HMI 0;
BA_ "GenSigTimeoutTime_RFHM" SG_ 1426 MessageCounter_VDCM_HMI 0;
BA_ "GenSigTimeoutTime_MPAD" SG_ 1426 MessageCounter_VDCM_HMI 0;
BA_ "GenSigTimeoutTime_GNMM" SG_ 1426 MessageCounter_VDCM_HMI 0;
BA_ "GenSigTimeoutTime_EVCU2" SG_ 1426 MessageCounter_VDCM_HMI 0;
BA_ "GenSigTimeoutTime_ESL" SG_ 1426 MessageCounter_VDCM_HMI 0;
BA_ "GenSigTimeoutTime_ECM" SG_ 1426 MessageCounter_VDCM_HMI 0;
BA_ "GenSigTimeoutTime_DTCM" SG_ 1426 MessageCounter_VDCM_HMI 0;
BA_ "GenSigTimeoutTime_DMSM" SG_ 1426 MessageCounter_VDCM_HMI 0;
BA_ "GenSigTimeoutTime_BSM" SG_ 1426 MessageCounter_VDCM_HMI 0;
BA_ "GenSigTimeoutTime_BCM" SG_ 1426 MessageCounter_VDCM_HMI 0;
BA_ "GenSigTimeoutTime_AGSM" SG_ 1426 MessageCounter_VDCM_HMI 0;
BA_ "GenSigTimeoutTime_ADCAM" SG_ 1426 MessageCounter_VDCM_HMI 0;
BA_ "GenSigTimeoutTime_EVCU2" SG_ 1426 CRC_VDCM_HMI 0;
BA_ "GenSigTimeoutTime_ESL" SG_ 1426 CRC_VDCM_HMI 0;
BA_ "GenSigTimeoutTime_ECM" SG_ 1426 CRC_VDCM_HMI 0;
BA_ "GenSigTimeoutTime_DTCM" SG_ 1426 CRC_VDCM_HMI 0;
BA_ "GenSigTimeoutTime_DMSM" SG_ 1426 CRC_VDCM_HMI 0;
BA_ "GenSigTimeoutTime_BSM" SG_ 1426 CRC_VDCM_HMI 0;
BA_ "GenSigTimeoutTime_BCM" SG_ 1426 CRC_VDCM_HMI 0;
BA_ "GenSigTimeoutTime_AGSM" SG_ 1426 CRC_VDCM_HMI 0;
BA_ "GenSigTimeoutTime_ADCAM" SG_ 1426 CRC_VDCM_HMI 0;
BA_ "GenSigTimeoutTime_SGW" SG_ 1426 CRC_VDCM_HMI 0;
BA_ "GenSigTimeoutTime_RFHM" SG_ 1426 CRC_VDCM_HMI 0;
BA_ "GenSigTimeoutTime_MPAD" SG_ 1426 CRC_VDCM_HMI 0;
BA_ "GenSigTimeoutTime_GNMM" SG_ 1426 CRC_VDCM_HMI 0;
BA_ "GenSigTimeoutTime_SGW" SG_ 1426 BatteryRunaway_Lamp_PT 0;
BA_ "GenSigTimeoutTime_RFHM" SG_ 1426 BatteryRunaway_Lamp_PT 0;
BA_ "GenSigTimeoutTime_MPAD" SG_ 1426 BatteryRunaway_Lamp_PT 0;
BA_ "GenSigTimeoutTime_GNMM" SG_ 1426 BatteryRunaway_Lamp_PT 0;
BA_ "GenSigTimeoutTime_EVCU2" SG_ 1426 BatteryRunaway_Lamp_PT 0;
BA_ "GenSigTimeoutTime_ESL" SG_ 1426 BatteryRunaway_Lamp_PT 0;
BA_ "GenSigTimeoutTime_ECM" SG_ 1426 BatteryRunaway_Lamp_PT 0;
BA_ "GenSigTimeoutTime_DTCM" SG_ 1426 BatteryRunaway_Lamp_PT 0;
BA_ "GenSigTimeoutTime_DMSM" SG_ 1426 BatteryRunaway_Lamp_PT 0;
BA_ "GenSigTimeoutTime_BSM" SG_ 1426 BatteryRunaway_Lamp_PT 0;
BA_ "GenSigTimeoutTime_AGSM" SG_ 1426 BatteryRunaway_Lamp_PT 0;
BA_ "GenSigTimeoutTime_ADCAM" SG_ 1426 BatteryRunaway_Lamp_PT 0;
BA_ "GenSigTimeoutTime_RFHM" SG_ 1426 Est_HVBatSOC_VDCM 0;
BA_ "GenSigTimeoutTime_MPAD" SG_ 1426 Est_HVBatSOC_VDCM 0;
BA_ "GenSigTimeoutTime_IPC" SG_ 1426 Est_HVBatSOC_VDCM 0;
BA_ "GenSigTimeoutTime_GNMM" SG_ 1426 Est_HVBatSOC_VDCM 0;
BA_ "GenSigTimeoutTime_EVCU2" SG_ 1426 Est_HVBatSOC_VDCM 0;
BA_ "GenSigTimeoutTime_ESL" SG_ 1426 Est_HVBatSOC_VDCM 0;
BA_ "GenSigTimeoutTime_ECM" SG_ 1426 Est_HVBatSOC_VDCM 0;
BA_ "GenSigTimeoutTime_DTCM" SG_ 1426 Est_HVBatSOC_VDCM 0;
BA_ "GenSigTimeoutTime_DMSM" SG_ 1426 Est_HVBatSOC_VDCM 0;
BA_ "GenSigTimeoutTime_BSM" SG_ 1426 Est_HVBatSOC_VDCM 0;
BA_ "GenSigTimeoutTime_BCM" SG_ 1426 Est_HVBatSOC_VDCM 0;
BA_ "GenSigTimeoutTime_AGSM" SG_ 1426 Est_HVBatSOC_VDCM 0;
BA_ "GenSigTimeoutTime_ADCAM" SG_ 1426 Est_HVBatSOC_VDCM 0;
BA_ "GenSigSendType" SG_ 1426 Est_HVBatSOC_VDCM 3;
BA_ "GenSigTimeoutTime_DTCM" SG_ 1442 SugSpeedMax 0;
BA_ "GenSigTimeoutTime_DMSM" SG_ 1442 SugSpeedMax 0;
BA_ "GenSigTimeoutTime_BSM" SG_ 1442 SugSpeedMax 0;
BA_ "GenSigTimeoutTime_BCM" SG_ 1442 SugSpeedMax 0;
BA_ "GenSigTimeoutTime_AGSM" SG_ 1442 SugSpeedMax 0;
BA_ "GenSigTimeoutTime_ADCAM" SG_ 1442 SugSpeedMax 0;
BA_ "GenSigSendType" SG_ 1442 SugSpeedMax 3;
BA_ "GenSigTimeoutTime_SGW" SG_ 1442 AC_Charge_Button_Label5 0;
BA_ "GenSigTimeoutTime_RFHM" SG_ 1442 AC_Charge_Button_Label5 0;
BA_ "GenSigTimeoutTime_MPAD" SG_ 1442 AC_Charge_Button_Label5 0;
BA_ "GenSigTimeoutTime_IPC" SG_ 1442 AC_Charge_Button_Label5 0;
BA_ "GenSigTimeoutTime_GNMM" SG_ 1442 AC_Charge_Button_Label5 0;
BA_ "GenSigTimeoutTime_EVCU2" SG_ 1442 AC_Charge_Button_Label5 0;
BA_ "GenSigTimeoutTime_ESL" SG_ 1442 AC_Charge_Button_Label5 0;
BA_ "GenSigTimeoutTime_ECM" SG_ 1442 AC_Charge_Button_Label5 0;
BA_ "GenSigTimeoutTime_DTCM" SG_ 1442 AC_Charge_Button_Label5 0;
BA_ "GenSigTimeoutTime_DMSM" SG_ 1442 AC_Charge_Button_Label5 0;
BA_ "GenSigTimeoutTime_BSM" SG_ 1442 AC_Charge_Button_Label5 0;
BA_ "GenSigTimeoutTime_BCM" SG_ 1442 AC_Charge_Button_Label5 0;
BA_ "GenSigTimeoutTime_AGSM" SG_ 1442 AC_Charge_Button_Label5 0;
BA_ "GenSigTimeoutTime_ADCAM" SG_ 1442 AC_Charge_Button_Label5 0;
BA_ "GenSigSendType" SG_ 1442 AC_Charge_Button_Label5 3;
BA_ "GenSigTimeoutTime_SGW" SG_ 1442 AC_Charge_Button_Label4 0;
BA_ "GenSigTimeoutTime_RFHM" SG_ 1442 AC_Charge_Button_Label4 0;
BA_ "GenSigTimeoutTime_MPAD" SG_ 1442 AC_Charge_Button_Label4 0;
BA_ "GenSigTimeoutTime_IPC" SG_ 1442 AC_Charge_Button_Label4 0;
BA_ "GenSigTimeoutTime_GNMM" SG_ 1442 AC_Charge_Button_Label4 0;
BA_ "GenSigTimeoutTime_EVCU2" SG_ 1442 AC_Charge_Button_Label4 0;
BA_ "GenSigTimeoutTime_ESL" SG_ 1442 AC_Charge_Button_Label4 0;
BA_ "GenSigTimeoutTime_ECM" SG_ 1442 AC_Charge_Button_Label4 0;
BA_ "GenSigTimeoutTime_DTCM" SG_ 1442 AC_Charge_Button_Label4 0;
BA_ "GenSigTimeoutTime_DMSM" SG_ 1442 AC_Charge_Button_Label4 0;
BA_ "GenSigTimeoutTime_BSM" SG_ 1442 AC_Charge_Button_Label4 0;
BA_ "GenSigTimeoutTime_BCM" SG_ 1442 AC_Charge_Button_Label4 0;
BA_ "GenSigTimeoutTime_AGSM" SG_ 1442 AC_Charge_Button_Label4 0;
BA_ "GenSigTimeoutTime_ADCAM" SG_ 1442 AC_Charge_Button_Label4 0;
BA_ "GenSigSendType" SG_ 1442 AC_Charge_Button_Label4 3;
BA_ "GenSigTimeoutTime_SGW" SG_ 1442 AC_Charge_Button_Label3 0;
BA_ "GenSigTimeoutTime_RFHM" SG_ 1442 AC_Charge_Button_Label3 0;
BA_ "GenSigTimeoutTime_MPAD" SG_ 1442 AC_Charge_Button_Label3 0;
BA_ "GenSigTimeoutTime_IPC" SG_ 1442 AC_Charge_Button_Label3 0;
BA_ "GenSigTimeoutTime_GNMM" SG_ 1442 AC_Charge_Button_Label3 0;
BA_ "GenSigTimeoutTime_EVCU2" SG_ 1442 AC_Charge_Button_Label3 0;
BA_ "GenSigTimeoutTime_ESL" SG_ 1442 AC_Charge_Button_Label3 0;
BA_ "GenSigTimeoutTime_ECM" SG_ 1442 AC_Charge_Button_Label3 0;
BA_ "GenSigTimeoutTime_DTCM" SG_ 1442 AC_Charge_Button_Label3 0;
BA_ "GenSigTimeoutTime_DMSM" SG_ 1442 AC_Charge_Button_Label3 0;
BA_ "GenSigTimeoutTime_BSM" SG_ 1442 AC_Charge_Button_Label3 0;
BA_ "GenSigTimeoutTime_BCM" SG_ 1442 AC_Charge_Button_Label3 0;
BA_ "GenSigTimeoutTime_AGSM" SG_ 1442 AC_Charge_Button_Label3 0;
BA_ "GenSigTimeoutTime_ADCAM" SG_ 1442 AC_Charge_Button_Label3 0;
BA_ "GenSigSendType" SG_ 1442 AC_Charge_Button_Label3 3;
BA_ "GenSigTimeoutTime_SGW" SG_ 1442 AC_Charge_Button_Label2 0;
BA_ "GenSigTimeoutTime_RFHM" SG_ 1442 AC_Charge_Button_Label2 0;
BA_ "GenSigTimeoutTime_MPAD" SG_ 1442 AC_Charge_Button_Label2 0;
BA_ "GenSigTimeoutTime_IPC" SG_ 1442 AC_Charge_Button_Label2 0;
BA_ "GenSigTimeoutTime_GNMM" SG_ 1442 AC_Charge_Button_Label2 0;
BA_ "GenSigTimeoutTime_EVCU2" SG_ 1442 AC_Charge_Button_Label2 0;
BA_ "GenSigTimeoutTime_ESL" SG_ 1442 AC_Charge_Button_Label2 0;
BA_ "GenSigTimeoutTime_ECM" SG_ 1442 AC_Charge_Button_Label2 0;
BA_ "GenSigTimeoutTime_DTCM" SG_ 1442 AC_Charge_Button_Label2 0;
BA_ "GenSigTimeoutTime_DMSM" SG_ 1442 AC_Charge_Button_Label2 0;
BA_ "GenSigTimeoutTime_BSM" SG_ 1442 AC_Charge_Button_Label2 0;
BA_ "GenSigTimeoutTime_BCM" SG_ 1442 AC_Charge_Button_Label2 0;
BA_ "GenSigTimeoutTime_AGSM" SG_ 1442 AC_Charge_Button_Label2 0;
BA_ "GenSigTimeoutTime_ADCAM" SG_ 1442 AC_Charge_Button_Label2 0;
BA_ "GenSigSendType" SG_ 1442 AC_Charge_Button_Label2 3;
BA_ "GenSigTimeoutTime_SGW" SG_ 1426 ServiceHVError 0;
BA_ "GenSigTimeoutTime_RFHM" SG_ 1426 ServiceHVError 0;
BA_ "GenSigTimeoutTime_MPAD" SG_ 1426 ServiceHVError 0;
BA_ "GenSigTimeoutTime_GNMM" SG_ 1426 ServiceHVError 0;
BA_ "GenSigTimeoutTime_EVCU2" SG_ 1426 ServiceHVError 0;
BA_ "GenSigTimeoutTime_ESL" SG_ 1426 ServiceHVError 0;
BA_ "GenSigTimeoutTime_ECM" SG_ 1426 ServiceHVError 0;
BA_ "GenSigTimeoutTime_DTCM" SG_ 1426 ServiceHVError 0;
BA_ "GenSigTimeoutTime_DMSM" SG_ 1426 ServiceHVError 0;
BA_ "GenSigTimeoutTime_BSM" SG_ 1426 ServiceHVError 0;
BA_ "GenSigTimeoutTime_BCM" SG_ 1426 ServiceHVError 0;
BA_ "GenSigTimeoutTime_AGSM" SG_ 1426 ServiceHVError 0;
BA_ "GenSigTimeoutTime_ADCAM" SG_ 1426 ServiceHVError 0;
BA_ "GenSigSendType" SG_ 1426 ServiceHVError 3;
BA_ "GenSigTimeoutTime_SGW" SG_ 1442 AC_Charge_Button_Label1 0;
BA_ "GenSigTimeoutTime_RFHM" SG_ 1442 AC_Charge_Button_Label1 0;
BA_ "GenSigTimeoutTime_MPAD" SG_ 1442 AC_Charge_Button_Label1 0;
BA_ "GenSigTimeoutTime_IPC" SG_ 1442 AC_Charge_Button_Label1 0;
BA_ "GenSigTimeoutTime_GNMM" SG_ 1442 AC_Charge_Button_Label1 0;
BA_ "GenSigTimeoutTime_EVCU2" SG_ 1442 AC_Charge_Button_Label1 0;
BA_ "GenSigTimeoutTime_ESL" SG_ 1442 AC_Charge_Button_Label1 0;
BA_ "GenSigTimeoutTime_ECM" SG_ 1442 AC_Charge_Button_Label1 0;
BA_ "GenSigTimeoutTime_DTCM" SG_ 1442 AC_Charge_Button_Label1 0;
BA_ "GenSigTimeoutTime_DMSM" SG_ 1442 AC_Charge_Button_Label1 0;
BA_ "GenSigTimeoutTime_BSM" SG_ 1442 AC_Charge_Button_Label1 0;
BA_ "GenSigTimeoutTime_BCM" SG_ 1442 AC_Charge_Button_Label1 0;
BA_ "GenSigTimeoutTime_AGSM" SG_ 1442 AC_Charge_Button_Label1 0;
BA_ "GenSigTimeoutTime_ADCAM" SG_ 1442 AC_Charge_Button_Label1 0;
BA_ "GenSigSendType" SG_ 1442 AC_Charge_Button_Label1 3;
BA_ "GenSigTimeoutTime_SGW" SG_ 205 DriverReq_AxleTrq_Enabled_BSM 0;
BA_ "GenSigTimeoutTime_RFHM" SG_ 205 DriverReq_AxleTrq_Enabled_BSM 0;
BA_ "GenSigTimeoutTime_MPAD" SG_ 205 DriverReq_AxleTrq_Enabled_BSM 0;
BA_ "GenSigTimeoutTime_IPC" SG_ 205 DriverReq_AxleTrq_Enabled_BSM 0;
BA_ "GenSigTimeoutTime_GNMM" SG_ 205 DriverReq_AxleTrq_Enabled_BSM 0;
BA_ "GenSigTimeoutTime_ESL" SG_ 205 DriverReq_AxleTrq_Enabled_BSM 0;
BA_ "GenSigTimeoutTime_ECM" SG_ 205 DriverReq_AxleTrq_Enabled_BSM 0;
BA_ "GenSigTimeoutTime_DTCM" SG_ 205 DriverReq_AxleTrq_Enabled_BSM 0;
BA_ "GenSigTimeoutTime_DMSM" SG_ 205 DriverReq_AxleTrq_Enabled_BSM 0;
BA_ "GenSigTimeoutTime_BSM" SG_ 205 DriverReq_AxleTrq_Enabled_BSM 0;
BA_ "GenSigTimeoutTime_BCM" SG_ 205 DriverReq_AxleTrq_Enabled_BSM 0;
BA_ "GenSigTimeoutTime_AGSM" SG_ 205 DriverReq_AxleTrq_Enabled_BSM 0;
BA_ "GenSigTimeoutTime_ADCAM" SG_ 205 DriverReq_AxleTrq_Enabled_BSM 0;
BA_ "GenSigTimeoutTime_SGW" SG_ 205 DrvrIntd_TotalBrk_AxleTorq 0;
BA_ "GenSigTimeoutTime_RFHM" SG_ 205 DrvrIntd_TotalBrk_AxleTorq 0;
BA_ "GenSigTimeoutTime_MPAD" SG_ 205 DrvrIntd_TotalBrk_AxleTorq 0;
BA_ "GenSigTimeoutTime_IPC" SG_ 205 DrvrIntd_TotalBrk_AxleTorq 0;
BA_ "GenSigTimeoutTime_GNMM" SG_ 205 DrvrIntd_TotalBrk_AxleTorq 0;
BA_ "GenSigTimeoutTime_ESL" SG_ 205 DrvrIntd_TotalBrk_AxleTorq 0;
BA_ "GenSigTimeoutTime_ECM" SG_ 205 DrvrIntd_TotalBrk_AxleTorq 0;
BA_ "GenSigTimeoutTime_DTCM" SG_ 205 DrvrIntd_TotalBrk_AxleTorq 0;
BA_ "GenSigTimeoutTime_DMSM" SG_ 205 DrvrIntd_TotalBrk_AxleTorq 0;
BA_ "GenSigTimeoutTime_BSM" SG_ 205 DrvrIntd_TotalBrk_AxleTorq 0;
BA_ "GenSigTimeoutTime_BCM" SG_ 205 DrvrIntd_TotalBrk_AxleTorq 0;
BA_ "GenSigTimeoutTime_AGSM" SG_ 205 DrvrIntd_TotalBrk_AxleTorq 0;
BA_ "GenSigTimeoutTime_ADCAM" SG_ 205 DrvrIntd_TotalBrk_AxleTorq 0;
BA_ "GenSigTimeoutTime_SGW" SG_ 205 Regen_AxleTorque_Req 0;
BA_ "GenSigTimeoutTime_RFHM" SG_ 205 Regen_AxleTorque_Req 0;
BA_ "GenSigTimeoutTime_MPAD" SG_ 205 Regen_AxleTorque_Req 0;
BA_ "GenSigTimeoutTime_IPC" SG_ 205 Regen_AxleTorque_Req 0;
BA_ "GenSigTimeoutTime_GNMM" SG_ 205 Regen_AxleTorque_Req 0;
BA_ "GenSigTimeoutTime_ESL" SG_ 205 Regen_AxleTorque_Req 0;
BA_ "GenSigTimeoutTime_ECM" SG_ 205 Regen_AxleTorque_Req 0;
BA_ "GenSigTimeoutTime_DTCM" SG_ 205 Regen_AxleTorque_Req 0;
BA_ "GenSigTimeoutTime_DMSM" SG_ 205 Regen_AxleTorque_Req 0;
BA_ "GenSigTimeoutTime_BSM" SG_ 205 Regen_AxleTorque_Req 0;
BA_ "GenSigTimeoutTime_BCM" SG_ 205 Regen_AxleTorque_Req 0;
BA_ "GenSigTimeoutTime_AGSM" SG_ 205 Regen_AxleTorque_Req 0;
BA_ "GenSigTimeoutTime_ADCAM" SG_ 205 Regen_AxleTorque_Req 0;
BA_ "GenSigTimeoutTime_SGW" SG_ 205 TotalAxle_Max_Rq_BSM 0;
BA_ "GenSigTimeoutTime_RFHM" SG_ 205 TotalAxle_Max_Rq_BSM 0;
BA_ "GenSigTimeoutTime_MPAD" SG_ 205 TotalAxle_Max_Rq_BSM 0;
BA_ "GenSigTimeoutTime_IPC" SG_ 205 TotalAxle_Max_Rq_BSM 0;
BA_ "GenSigTimeoutTime_GNMM" SG_ 205 TotalAxle_Max_Rq_BSM 0;
BA_ "GenSigTimeoutTime_ESL" SG_ 205 TotalAxle_Max_Rq_BSM 0;
BA_ "GenSigTimeoutTime_ECM" SG_ 205 TotalAxle_Max_Rq_BSM 0;
BA_ "GenSigTimeoutTime_DMSM" SG_ 205 TotalAxle_Max_Rq_BSM 0;
BA_ "GenSigTimeoutTime_BSM" SG_ 205 TotalAxle_Max_Rq_BSM 0;
BA_ "GenSigTimeoutTime_BCM" SG_ 205 TotalAxle_Max_Rq_BSM 0;
BA_ "GenSigTimeoutTime_AGSM" SG_ 205 TotalAxle_Max_Rq_BSM 0;
BA_ "GenSigTimeoutTime_ADCAM" SG_ 205 TotalAxle_Max_Rq_BSM 0;
BA_ "GenSigTimeoutTime_SGW" SG_ 205 TotalAxle_Min_Rq_BSM 0;
BA_ "GenSigTimeoutTime_RFHM" SG_ 205 TotalAxle_Min_Rq_BSM 0;
BA_ "GenSigTimeoutTime_MPAD" SG_ 205 TotalAxle_Min_Rq_BSM 0;
BA_ "GenSigTimeoutTime_IPC" SG_ 205 TotalAxle_Min_Rq_BSM 0;
BA_ "GenSigTimeoutTime_GNMM" SG_ 205 TotalAxle_Min_Rq_BSM 0;
BA_ "GenSigTimeoutTime_ESL" SG_ 205 TotalAxle_Min_Rq_BSM 0;
BA_ "GenSigTimeoutTime_ECM" SG_ 205 TotalAxle_Min_Rq_BSM 0;
BA_ "GenSigTimeoutTime_DTCM" SG_ 205 TotalAxle_Min_Rq_BSM 0;
BA_ "GenSigTimeoutTime_DMSM" SG_ 205 TotalAxle_Min_Rq_BSM 0;
BA_ "GenSigTimeoutTime_BSM" SG_ 205 TotalAxle_Min_Rq_BSM 0;
BA_ "GenSigTimeoutTime_BCM" SG_ 205 TotalAxle_Min_Rq_BSM 0;
BA_ "GenSigTimeoutTime_AGSM" SG_ 205 TotalAxle_Min_Rq_BSM 0;
BA_ "GenSigTimeoutTime_ADCAM" SG_ 205 TotalAxle_Min_Rq_BSM 0;
BA_ "GenSigTimeoutTime_SGW" SG_ 205 FrontAxle_Max_Rq_BSM 0;
BA_ "GenSigTimeoutTime_RFHM" SG_ 205 FrontAxle_Max_Rq_BSM 0;
BA_ "GenSigTimeoutTime_MPAD" SG_ 205 FrontAxle_Max_Rq_BSM 0;
BA_ "GenSigTimeoutTime_IPC" SG_ 205 FrontAxle_Max_Rq_BSM 0;
BA_ "GenSigTimeoutTime_GNMM" SG_ 205 FrontAxle_Max_Rq_BSM 0;
BA_ "GenSigTimeoutTime_ESL" SG_ 205 FrontAxle_Max_Rq_BSM 0;
BA_ "GenSigTimeoutTime_ECM" SG_ 205 FrontAxle_Max_Rq_BSM 0;
BA_ "GenSigTimeoutTime_DTCM" SG_ 205 FrontAxle_Max_Rq_BSM 0;
BA_ "GenSigTimeoutTime_DMSM" SG_ 205 FrontAxle_Max_Rq_BSM 0;
BA_ "GenSigTimeoutTime_BSM" SG_ 205 FrontAxle_Max_Rq_BSM 0;
BA_ "GenSigTimeoutTime_BCM" SG_ 205 FrontAxle_Max_Rq_BSM 0;
BA_ "GenSigTimeoutTime_AGSM" SG_ 205 FrontAxle_Max_Rq_BSM 0;
BA_ "GenSigTimeoutTime_ADCAM" SG_ 205 FrontAxle_Max_Rq_BSM 0;
BA_ "GenSigTimeoutTime_SGW" SG_ 205 FrontAxle_Min_Rq_BSM 0;
BA_ "GenSigTimeoutTime_RFHM" SG_ 205 FrontAxle_Min_Rq_BSM 0;
BA_ "GenSigTimeoutTime_MPAD" SG_ 205 FrontAxle_Min_Rq_BSM 0;
BA_ "GenSigTimeoutTime_IPC" SG_ 205 FrontAxle_Min_Rq_BSM 0;
BA_ "GenSigTimeoutTime_GNMM" SG_ 205 FrontAxle_Min_Rq_BSM 0;
BA_ "GenSigTimeoutTime_ESL" SG_ 205 FrontAxle_Min_Rq_BSM 0;
BA_ "GenSigTimeoutTime_ECM" SG_ 205 FrontAxle_Min_Rq_BSM 0;
BA_ "GenSigTimeoutTime_DTCM" SG_ 205 FrontAxle_Min_Rq_BSM 0;
BA_ "GenSigTimeoutTime_DMSM" SG_ 205 FrontAxle_Min_Rq_BSM 0;
BA_ "GenSigTimeoutTime_BSM" SG_ 205 FrontAxle_Min_Rq_BSM 0;
BA_ "GenSigTimeoutTime_BCM" SG_ 205 FrontAxle_Min_Rq_BSM 0;
BA_ "GenSigTimeoutTime_AGSM" SG_ 205 FrontAxle_Min_Rq_BSM 0;
BA_ "GenSigTimeoutTime_ADCAM" SG_ 205 FrontAxle_Min_Rq_BSM 0;
BA_ "GenSigTimeoutTime_SGW" SG_ 205 RearAxle_Max_Rq_BSM 0;
BA_ "GenSigTimeoutTime_RFHM" SG_ 205 RearAxle_Max_Rq_BSM 0;
BA_ "GenSigTimeoutTime_MPAD" SG_ 205 RearAxle_Max_Rq_BSM 0;
BA_ "GenSigTimeoutTime_IPC" SG_ 205 RearAxle_Max_Rq_BSM 0;
BA_ "GenSigTimeoutTime_GNMM" SG_ 205 RearAxle_Max_Rq_BSM 0;
BA_ "GenSigTimeoutTime_ESL" SG_ 205 RearAxle_Max_Rq_BSM 0;
BA_ "GenSigTimeoutTime_ECM" SG_ 205 RearAxle_Max_Rq_BSM 0;
BA_ "GenSigTimeoutTime_DTCM" SG_ 205 RearAxle_Max_Rq_BSM 0;
BA_ "GenSigTimeoutTime_DMSM" SG_ 205 RearAxle_Max_Rq_BSM 0;
BA_ "GenSigTimeoutTime_BSM" SG_ 205 RearAxle_Max_Rq_BSM 0;
BA_ "GenSigTimeoutTime_BCM" SG_ 205 RearAxle_Max_Rq_BSM 0;
BA_ "GenSigTimeoutTime_AGSM" SG_ 205 RearAxle_Max_Rq_BSM 0;
BA_ "GenSigTimeoutTime_ADCAM" SG_ 205 RearAxle_Max_Rq_BSM 0;
BA_ "GenSigTimeoutTime_SGW" SG_ 205 RearAxle_Min_Rq_BSM 0;
BA_ "GenSigTimeoutTime_RFHM" SG_ 205 RearAxle_Min_Rq_BSM 0;
BA_ "GenSigTimeoutTime_MPAD" SG_ 205 RearAxle_Min_Rq_BSM 0;
BA_ "GenSigTimeoutTime_IPC" SG_ 205 RearAxle_Min_Rq_BSM 0;
BA_ "GenSigTimeoutTime_GNMM" SG_ 205 RearAxle_Min_Rq_BSM 0;
BA_ "GenSigTimeoutTime_ESL" SG_ 205 RearAxle_Min_Rq_BSM 0;
BA_ "GenSigTimeoutTime_ECM" SG_ 205 RearAxle_Min_Rq_BSM 0;
BA_ "GenSigTimeoutTime_DTCM" SG_ 205 RearAxle_Min_Rq_BSM 0;
BA_ "GenSigTimeoutTime_DMSM" SG_ 205 RearAxle_Min_Rq_BSM 0;
BA_ "GenSigTimeoutTime_BSM" SG_ 205 RearAxle_Min_Rq_BSM 0;
BA_ "GenSigTimeoutTime_BCM" SG_ 205 RearAxle_Min_Rq_BSM 0;
BA_ "GenSigTimeoutTime_AGSM" SG_ 205 RearAxle_Min_Rq_BSM 0;
BA_ "GenSigTimeoutTime_ADCAM" SG_ 205 RearAxle_Min_Rq_BSM 0;
BA_ "GenSigTimeoutTime_SGW" SG_ 205 MessageCounter_BRAKE_FD_6 0;
BA_ "GenSigTimeoutTime_RFHM" SG_ 205 MessageCounter_BRAKE_FD_6 0;
BA_ "GenSigTimeoutTime_IPC" SG_ 205 MessageCounter_BRAKE_FD_6 0;
BA_ "GenSigTimeoutTime_GNMM" SG_ 205 MessageCounter_BRAKE_FD_6 0;
BA_ "GenSigTimeoutTime_ESL" SG_ 205 MessageCounter_BRAKE_FD_6 0;
BA_ "GenSigTimeoutTime_ECM" SG_ 205 MessageCounter_BRAKE_FD_6 0;
BA_ "GenSigTimeoutTime_DTCM" SG_ 205 MessageCounter_BRAKE_FD_6 0;
BA_ "GenSigTimeoutTime_DMSM" SG_ 205 MessageCounter_BRAKE_FD_6 0;
BA_ "GenSigTimeoutTime_BSM" SG_ 205 MessageCounter_BRAKE_FD_6 0;
BA_ "GenSigTimeoutTime_BCM" SG_ 205 MessageCounter_BRAKE_FD_6 0;
BA_ "GenSigTimeoutTime_AGSM" SG_ 205 MessageCounter_BRAKE_FD_6 0;
BA_ "GenSigTimeoutTime_ADCAM" SG_ 205 MessageCounter_BRAKE_FD_6 0;
BA_ "GenSigTimeoutTime_SGW" SG_ 205 CRC_BRAKE_FD_6 0;
BA_ "GenSigTimeoutTime_RFHM" SG_ 205 CRC_BRAKE_FD_6 0;
BA_ "GenSigTimeoutTime_IPC" SG_ 205 CRC_BRAKE_FD_6 0;
BA_ "GenSigTimeoutTime_GNMM" SG_ 205 CRC_BRAKE_FD_6 0;
BA_ "GenSigTimeoutTime_ESL" SG_ 205 CRC_BRAKE_FD_6 0;
BA_ "GenSigTimeoutTime_ECM" SG_ 205 CRC_BRAKE_FD_6 0;
BA_ "GenSigTimeoutTime_DTCM" SG_ 205 CRC_BRAKE_FD_6 0;
BA_ "GenSigTimeoutTime_DMSM" SG_ 205 CRC_BRAKE_FD_6 0;
BA_ "GenSigTimeoutTime_BSM" SG_ 205 CRC_BRAKE_FD_6 0;
BA_ "GenSigTimeoutTime_SGW" SG_ 205 TotalAxle_Rq_BSM 0;
BA_ "GenSigTimeoutTime_RFHM" SG_ 205 TotalAxle_Rq_BSM 0;
BA_ "GenSigTimeoutTime_MPAD" SG_ 205 TotalAxle_Rq_BSM 0;
BA_ "GenSigTimeoutTime_IPC" SG_ 205 TotalAxle_Rq_BSM 0;
BA_ "GenSigTimeoutTime_GNMM" SG_ 205 TotalAxle_Rq_BSM 0;
BA_ "GenSigTimeoutTime_ESL" SG_ 205 TotalAxle_Rq_BSM 0;
BA_ "GenSigTimeoutTime_ECM" SG_ 205 TotalAxle_Rq_BSM 0;
BA_ "GenSigTimeoutTime_DMSM" SG_ 205 TotalAxle_Rq_BSM 0;
BA_ "GenSigTimeoutTime_BSM" SG_ 205 TotalAxle_Rq_BSM 0;
BA_ "GenSigTimeoutTime_BCM" SG_ 205 TotalAxle_Rq_BSM 0;
BA_ "GenSigTimeoutTime_AGSM" SG_ 205 TotalAxle_Rq_BSM 0;
BA_ "GenSigTimeoutTime_ADCAM" SG_ 205 TotalAxle_Rq_BSM 0;
BA_ "GenSigStartValue" SG_ 205 TotalAxle_Rq_BSM 32767;
BA_ "GenSigTimeoutTime_RFHM" SG_ 205 DriverRequested_AxleTrq_BSM 0;
BA_ "GenSigTimeoutTime_MPAD" SG_ 205 DriverRequested_AxleTrq_BSM 0;
BA_ "GenSigTimeoutTime_IPC" SG_ 205 DriverRequested_AxleTrq_BSM 0;
BA_ "GenSigTimeoutTime_GNMM" SG_ 205 DriverRequested_AxleTrq_BSM 0;
BA_ "GenSigTimeoutTime_ESL" SG_ 205 DriverRequested_AxleTrq_BSM 0;
BA_ "GenSigTimeoutTime_ECM" SG_ 205 DriverRequested_AxleTrq_BSM 0;
BA_ "GenSigTimeoutTime_DTCM" SG_ 205 DriverRequested_AxleTrq_BSM 0;
BA_ "GenSigTimeoutTime_DMSM" SG_ 205 DriverRequested_AxleTrq_BSM 0;
BA_ "GenSigTimeoutTime_BSM" SG_ 205 DriverRequested_AxleTrq_BSM 0;
BA_ "GenSigTimeoutTime_BCM" SG_ 205 DriverRequested_AxleTrq_BSM 0;
BA_ "GenSigTimeoutTime_AGSM" SG_ 205 DriverRequested_AxleTrq_BSM 0;
BA_ "GenSigTimeoutTime_ADCAM" SG_ 205 DriverRequested_AxleTrq_BSM 0;
BA_ "GenSigStartValue" SG_ 205 DriverRequested_AxleTrq_BSM 32767;
BA_ "GenSigTimeoutTime_SGW" SG_ 205 DriverRequested_AxleTrq_BSM 0;
BA_ "GenSigTimeoutTime_SGW" SG_ 205 WED_MODE_RQ 0;
BA_ "GenSigTimeoutTime_RFHM" SG_ 205 WED_MODE_RQ 0;
BA_ "GenSigTimeoutTime_MPAD" SG_ 205 WED_MODE_RQ 0;
BA_ "GenSigTimeoutTime_IPC" SG_ 205 WED_MODE_RQ 0;
BA_ "GenSigTimeoutTime_GNMM" SG_ 205 WED_MODE_RQ 0;
BA_ "GenSigTimeoutTime_ESL" SG_ 205 WED_MODE_RQ 0;
BA_ "GenSigTimeoutTime_ECM" SG_ 205 WED_MODE_RQ 0;
BA_ "GenSigTimeoutTime_DTCM" SG_ 205 WED_MODE_RQ 0;
BA_ "GenSigTimeoutTime_DMSM" SG_ 205 WED_MODE_RQ 0;
BA_ "GenSigTimeoutTime_BSM" SG_ 205 WED_MODE_RQ 0;
BA_ "GenSigTimeoutTime_BCM" SG_ 205 WED_MODE_RQ 0;
BA_ "GenSigTimeoutTime_AGSM" SG_ 205 WED_MODE_RQ 0;
BA_ "GenSigTimeoutTime_ADCAM" SG_ 205 WED_MODE_RQ 0;
BA_ "GenSigTimeoutTime_SGW" SG_ 205 FrontAxle_Rq_BSM 0;
BA_ "GenSigTimeoutTime_RFHM" SG_ 205 FrontAxle_Rq_BSM 0;
BA_ "GenSigTimeoutTime_MPAD" SG_ 205 FrontAxle_Rq_BSM 0;
BA_ "GenSigTimeoutTime_IPC" SG_ 205 FrontAxle_Rq_BSM 0;
BA_ "GenSigTimeoutTime_GNMM" SG_ 205 FrontAxle_Rq_BSM 0;
BA_ "GenSigTimeoutTime_ESL" SG_ 205 FrontAxle_Rq_BSM 0;
BA_ "GenSigTimeoutTime_ECM" SG_ 205 FrontAxle_Rq_BSM 0;
BA_ "GenSigTimeoutTime_DTCM" SG_ 205 FrontAxle_Rq_BSM 0;
BA_ "GenSigTimeoutTime_DMSM" SG_ 205 FrontAxle_Rq_BSM 0;
BA_ "GenSigTimeoutTime_BSM" SG_ 205 FrontAxle_Rq_BSM 0;
BA_ "GenSigTimeoutTime_BCM" SG_ 205 FrontAxle_Rq_BSM 0;
BA_ "GenSigTimeoutTime_AGSM" SG_ 205 FrontAxle_Rq_BSM 0;
BA_ "GenSigTimeoutTime_ADCAM" SG_ 205 FrontAxle_Rq_BSM 0;
BA_ "GenSigStartValue" SG_ 205 FrontAxle_Rq_BSM 32767;
BA_ "GenSigTimeoutTime_SGW" SG_ 205 OPD_Hold_Status 0;
BA_ "GenSigTimeoutTime_RFHM" SG_ 205 OPD_Hold_Status 0;
BA_ "GenSigTimeoutTime_MPAD" SG_ 205 OPD_Hold_Status 0;
BA_ "GenSigTimeoutTime_IPC" SG_ 205 OPD_Hold_Status 0;
BA_ "GenSigTimeoutTime_GNMM" SG_ 205 OPD_Hold_Status 0;
BA_ "GenSigTimeoutTime_ESL" SG_ 205 OPD_Hold_Status 0;
BA_ "GenSigTimeoutTime_ECM" SG_ 205 OPD_Hold_Status 0;
BA_ "GenSigTimeoutTime_DTCM" SG_ 205 OPD_Hold_Status 0;
BA_ "GenSigTimeoutTime_DMSM" SG_ 205 OPD_Hold_Status 0;
BA_ "GenSigTimeoutTime_BSM" SG_ 205 OPD_Hold_Status 0;
BA_ "GenSigTimeoutTime_BCM" SG_ 205 OPD_Hold_Status 0;
BA_ "GenSigTimeoutTime_AGSM" SG_ 205 OPD_Hold_Status 0;
BA_ "GenSigTimeoutTime_ADCAM" SG_ 205 OPD_Hold_Status 0;
BA_ "GenSigTimeoutTime_SGW" SG_ 205 RearAxle_Rq_BSM 0;
BA_ "GenSigTimeoutTime_RFHM" SG_ 205 RearAxle_Rq_BSM 0;
BA_ "GenSigTimeoutTime_MPAD" SG_ 205 RearAxle_Rq_BSM 0;
BA_ "GenSigTimeoutTime_IPC" SG_ 205 RearAxle_Rq_BSM 0;
BA_ "GenSigTimeoutTime_GNMM" SG_ 205 RearAxle_Rq_BSM 0;
BA_ "GenSigTimeoutTime_ESL" SG_ 205 RearAxle_Rq_BSM 0;
BA_ "GenSigTimeoutTime_ECM" SG_ 205 RearAxle_Rq_BSM 0;
BA_ "GenSigTimeoutTime_DTCM" SG_ 205 RearAxle_Rq_BSM 0;
BA_ "GenSigTimeoutTime_DMSM" SG_ 205 RearAxle_Rq_BSM 0;
BA_ "GenSigTimeoutTime_BSM" SG_ 205 RearAxle_Rq_BSM 0;
BA_ "GenSigTimeoutTime_BCM" SG_ 205 RearAxle_Rq_BSM 0;
BA_ "GenSigTimeoutTime_AGSM" SG_ 205 RearAxle_Rq_BSM 0;
BA_ "GenSigTimeoutTime_ADCAM" SG_ 205 RearAxle_Rq_BSM 0;
BA_ "GenSigStartValue" SG_ 205 RearAxle_Rq_BSM 32767;
BA_ "GenSigTimeoutTime_BCM" SG_ 205 CRC_BRAKE_FD_6 0;
BA_ "GenSigTimeoutTime_AGSM" SG_ 205 CRC_BRAKE_FD_6 0;
BA_ "GenSigTimeoutTime_ADCAM" SG_ 205 CRC_BRAKE_FD_6 0;
BA_ "GenSigTimeoutTime_SGW" SG_ 205 Cmnd_TotBrkFrict_AxleTorq 0;
BA_ "GenSigTimeoutTime_RFHM" SG_ 205 Cmnd_TotBrkFrict_AxleTorq 0;
BA_ "GenSigTimeoutTime_MPAD" SG_ 205 Cmnd_TotBrkFrict_AxleTorq 0;
BA_ "GenSigTimeoutTime_IPC" SG_ 205 Cmnd_TotBrkFrict_AxleTorq 0;
BA_ "GenSigTimeoutTime_GNMM" SG_ 205 Cmnd_TotBrkFrict_AxleTorq 0;
BA_ "GenSigTimeoutTime_ESL" SG_ 205 Cmnd_TotBrkFrict_AxleTorq 0;
BA_ "GenSigTimeoutTime_ECM" SG_ 205 Cmnd_TotBrkFrict_AxleTorq 0;
BA_ "GenSigTimeoutTime_DTCM" SG_ 205 Cmnd_TotBrkFrict_AxleTorq 0;
BA_ "GenSigTimeoutTime_DMSM" SG_ 205 Cmnd_TotBrkFrict_AxleTorq 0;
BA_ "GenSigTimeoutTime_BSM" SG_ 205 Cmnd_TotBrkFrict_AxleTorq 0;
BA_ "GenSigTimeoutTime_BCM" SG_ 205 Cmnd_TotBrkFrict_AxleTorq 0;
BA_ "GenSigTimeoutTime_AGSM" SG_ 205 Cmnd_TotBrkFrict_AxleTorq 0;
BA_ "GenSigTimeoutTime_ADCAM" SG_ 205 Cmnd_TotBrkFrict_AxleTorq 0;
BA_ "GenSigTimeoutTime_RFHM" SG_ 2654339257 CurrentCanNMState_FD09_WCPM2 0;
BA_ "GenSigTimeoutTime_MPAD" SG_ 2654339257 CurrentCanNMState_FD09_WCPM2 0;
BA_ "GenSigTimeoutTime_IPC" SG_ 2654339257 CurrentCanNMState_FD09_WCPM2 0;
BA_ "GenSigTimeoutTime_GNMM" SG_ 2654339257 CurrentCanNMState_FD09_WCPM2 0;
BA_ "GenSigTimeoutTime_EVCU2" SG_ 2654339257 CurrentCanNMState_FD09_WCPM2 0;
BA_ "GenSigTimeoutTime_ESL" SG_ 2654339257 CurrentCanNMState_FD09_WCPM2 0;
BA_ "GenSigTimeoutTime_ECM" SG_ 2654339257 CurrentCanNMState_FD09_WCPM2 0;
BA_ "GenSigTimeoutTime_DTCM" SG_ 2654339257 CurrentCanNMState_FD09_WCPM2 0;
BA_ "GenSigTimeoutTime_DMSM" SG_ 2654339257 CurrentCanNMState_FD09_WCPM2 0;
BA_ "GenSigTimeoutTime_BSM" SG_ 2654339257 CurrentCanNMState_FD09_WCPM2 0;
BA_ "GenSigTimeoutTime_BCM" SG_ 2654339257 CurrentCanNMState_FD09_WCPM2 0;
BA_ "GenSigTimeoutTime_AGSM" SG_ 2654339257 CurrentCanNMState_FD09_WCPM2 0;
BA_ "GenSigTimeoutTime_ADCAM" SG_ 2654339257 CurrentCanNMState_FD09_WCPM2 0;
BA_ "GenSigTimeoutTime_RFHM" SG_ 2654339257 PreviousCanNMState_FD09_WCPM2 0;
BA_ "GenSigTimeoutTime_MPAD" SG_ 2654339257 PreviousCanNMState_FD09_WCPM2 0;
BA_ "GenSigTimeoutTime_IPC" SG_ 2654339257 PreviousCanNMState_FD09_WCPM2 0;
BA_ "GenSigTimeoutTime_GNMM" SG_ 2654339257 PreviousCanNMState_FD09_WCPM2 0;
BA_ "GenSigTimeoutTime_EVCU2" SG_ 2654339257 PreviousCanNMState_FD09_WCPM2 0;
BA_ "GenSigTimeoutTime_ESL" SG_ 2654339257 PreviousCanNMState_FD09_WCPM2 0;
BA_ "GenSigTimeoutTime_ECM" SG_ 2654339257 PreviousCanNMState_FD09_WCPM2 0;
BA_ "GenSigTimeoutTime_DTCM" SG_ 2654339257 PreviousCanNMState_FD09_WCPM2 0;
BA_ "GenSigTimeoutTime_DMSM" SG_ 2654339257 PreviousCanNMState_FD09_WCPM2 0;
BA_ "GenSigTimeoutTime_BSM" SG_ 2654339257 PreviousCanNMState_FD09_WCPM2 0;
BA_ "GenSigTimeoutTime_BCM" SG_ 2654339257 PreviousCanNMState_FD09_WCPM2 0;
BA_ "GenSigTimeoutTime_AGSM" SG_ 2654339257 PreviousCanNMState_FD09_WCPM2 0;
BA_ "GenSigTimeoutTime_ADCAM" SG_ 2654339257 PreviousCanNMState_FD09_WCPM2 0;
BA_ "GenSigTimeoutTime_RFHM" SG_ 2654339257 GenericFailSts_FD09_WCPM2 0;
BA_ "GenSigTimeoutTime_MPAD" SG_ 2654339257 GenericFailSts_FD09_WCPM2 0;
BA_ "GenSigTimeoutTime_IPC" SG_ 2654339257 GenericFailSts_FD09_WCPM2 0;
BA_ "GenSigTimeoutTime_GNMM" SG_ 2654339257 GenericFailSts_FD09_WCPM2 0;
BA_ "GenSigTimeoutTime_EVCU2" SG_ 2654339257 GenericFailSts_FD09_WCPM2 0;
BA_ "GenSigTimeoutTime_ESL" SG_ 2654339257 GenericFailSts_FD09_WCPM2 0;
BA_ "GenSigTimeoutTime_ECM" SG_ 2654339257 GenericFailSts_FD09_WCPM2 0;
BA_ "GenSigTimeoutTime_DTCM" SG_ 2654339257 GenericFailSts_FD09_WCPM2 0;
BA_ "GenSigTimeoutTime_DMSM" SG_ 2654339257 GenericFailSts_FD09_WCPM2 0;
BA_ "GenSigTimeoutTime_BSM" SG_ 2654339257 GenericFailSts_FD09_WCPM2 0;
BA_ "GenSigTimeoutTime_AGSM" SG_ 2654339257 GenericFailSts_FD09_WCPM2 0;
BA_ "GenSigTimeoutTime_ADCAM" SG_ 2654339257 GenericFailSts_FD09_WCPM2 0;
BA_ "GenSigTimeoutTime_RFHM" SG_ 2654339257 EOL_FD09_WCPM2 0;
BA_ "GenSigTimeoutTime_MPAD" SG_ 2654339257 EOL_FD09_WCPM2 0;
BA_ "GenSigTimeoutTime_IPC" SG_ 2654339257 EOL_FD09_WCPM2 0;
BA_ "GenSigTimeoutTime_GNMM" SG_ 2654339257 EOL_FD09_WCPM2 0;
BA_ "GenSigTimeoutTime_EVCU2" SG_ 2654339257 EOL_FD09_WCPM2 0;
BA_ "GenSigTimeoutTime_ESL" SG_ 2654339257 EOL_FD09_WCPM2 0;
BA_ "GenSigTimeoutTime_ECM" SG_ 2654339257 EOL_FD09_WCPM2 0;
BA_ "GenSigTimeoutTime_DTCM" SG_ 2654339257 EOL_FD09_WCPM2 0;
BA_ "GenSigTimeoutTime_DMSM" SG_ 2654339257 EOL_FD09_WCPM2 0;
BA_ "GenSigTimeoutTime_BSM" SG_ 2654339257 EOL_FD09_WCPM2 0;
BA_ "GenSigTimeoutTime_AGSM" SG_ 2654339257 EOL_FD09_WCPM2 0;
BA_ "GenSigTimeoutTime_ADCAM" SG_ 2654339257 EOL_FD09_WCPM2 0;
BA_ "GenSigTimeoutTime_RFHM" SG_ 2654339257 DES_FD09_WCPM2 0;
BA_ "GenSigTimeoutTime_MPAD" SG_ 2654339257 DES_FD09_WCPM2 0;
BA_ "GenSigTimeoutTime_IPC" SG_ 2654339257 DES_FD09_WCPM2 0;
BA_ "GenSigTimeoutTime_GNMM" SG_ 2654339257 DES_FD09_WCPM2 0;
BA_ "GenSigTimeoutTime_EVCU2" SG_ 2654339257 DES_FD09_WCPM2 0;
BA_ "GenSigTimeoutTime_ESL" SG_ 2654339257 DES_FD09_WCPM2 0;
BA_ "GenSigTimeoutTime_ECM" SG_ 2654339257 DES_FD09_WCPM2 0;
BA_ "GenSigTimeoutTime_DTCM" SG_ 2654339257 DES_FD09_WCPM2 0;
BA_ "GenSigTimeoutTime_DMSM" SG_ 2654339257 DES_FD09_WCPM2 0;
BA_ "GenSigTimeoutTime_BSM" SG_ 2654339257 DES_FD09_WCPM2 0;
BA_ "GenSigTimeoutTime_BCM" SG_ 2654339257 DES_FD09_WCPM2 0;
BA_ "GenSigTimeoutTime_AGSM" SG_ 2654339257 DES_FD09_WCPM2 0;
BA_ "GenSigTimeoutTime_ADCAM" SG_ 2654339257 DES_FD09_WCPM2 0;
BA_ "GenSigTimeoutTime_RFHM" SG_ 2654339257 CurrentFailSts_FD09_WCPM2 0;
BA_ "GenSigTimeoutTime_MPAD" SG_ 2654339257 CurrentFailSts_FD09_WCPM2 0;
BA_ "GenSigTimeoutTime_IPC" SG_ 2654339257 CurrentFailSts_FD09_WCPM2 0;
BA_ "GenSigTimeoutTime_GNMM" SG_ 2654339257 CurrentFailSts_FD09_WCPM2 0;
BA_ "GenSigTimeoutTime_EVCU2" SG_ 2654339257 CurrentFailSts_FD09_WCPM2 0;
BA_ "GenSigTimeoutTime_ESL" SG_ 2654339257 CurrentFailSts_FD09_WCPM2 0;
BA_ "GenSigTimeoutTime_ECM" SG_ 2654339257 CurrentFailSts_FD09_WCPM2 0;
BA_ "GenSigTimeoutTime_DTCM" SG_ 2654339257 CurrentFailSts_FD09_WCPM2 0;
BA_ "GenSigTimeoutTime_DMSM" SG_ 2654339257 CurrentFailSts_FD09_WCPM2 0;
BA_ "GenSigTimeoutTime_BSM" SG_ 2654339257 CurrentFailSts_FD09_WCPM2 0;
BA_ "GenSigTimeoutTime_AGSM" SG_ 2654339257 CurrentFailSts_FD09_WCPM2 0;
BA_ "GenSigTimeoutTime_ADCAM" SG_ 2654339257 CurrentFailSts_FD09_WCPM2 0;
BA_ "GenSigTimeoutTime_DMSM" SG_ 2654339257 StayActiveSource_FD09_WCPM2 0;
BA_ "GenSigTimeoutTime_BSM" SG_ 2654339257 StayActiveSource_FD09_WCPM2 0;
BA_ "GenSigTimeoutTime_BCM" SG_ 2654339257 StayActiveSource_FD09_WCPM2 0;
BA_ "GenSigTimeoutTime_AGSM" SG_ 2654339257 StayActiveSource_FD09_WCPM2 0;
BA_ "GenSigTimeoutTime_ADCAM" SG_ 2654339257 StayActiveSource_FD09_WCPM2 0;
BA_ "GenSigTimeoutTime_SGW" SG_ 1440 AUD_LVL 0;
BA_ "GenSigTimeoutTime_RFHM" SG_ 1440 AUD_LVL 0;
BA_ "GenSigTimeoutTime_MPAD" SG_ 1440 AUD_LVL 0;
BA_ "GenSigTimeoutTime_IPC" SG_ 1440 AUD_LVL 0;
BA_ "GenSigTimeoutTime_GNMM" SG_ 1440 AUD_LVL 0;
BA_ "GenSigTimeoutTime_ESL" SG_ 1440 AUD_LVL 0;
BA_ "GenSigTimeoutTime_ECM" SG_ 1440 AUD_LVL 0;
BA_ "GenSigTimeoutTime_DTCM" SG_ 1440 AUD_LVL 0;
BA_ "GenSigTimeoutTime_DMSM" SG_ 1440 AUD_LVL 0;
BA_ "GenSigTimeoutTime_BSM" SG_ 1440 AUD_LVL 0;
BA_ "GenSigTimeoutTime_BCM" SG_ 1440 AUD_LVL 0;
BA_ "GenSigTimeoutTime_AGSM" SG_ 1440 AUD_LVL 0;
BA_ "GenSigTimeoutTime_ADCAM" SG_ 1440 AUD_LVL 0;
BA_ "GenSigSendType" SG_ 1440 AUD_LVL 3;
BA_ "GenSigTimeoutTime_SGW" SG_ 1440 ETM_HUD_Zone4_Expanded 0;
BA_ "GenSigTimeoutTime_RFHM" SG_ 1440 ETM_HUD_Zone4_Expanded 0;
BA_ "GenSigTimeoutTime_MPAD" SG_ 1440 ETM_HUD_Zone4_Expanded 0;
BA_ "GenSigTimeoutTime_GNMM" SG_ 1440 ETM_HUD_Zone4_Expanded 0;
BA_ "GenSigTimeoutTime_EVCU2" SG_ 1440 ETM_HUD_Zone4_Expanded 0;
BA_ "GenSigTimeoutTime_ESL" SG_ 1440 ETM_HUD_Zone4_Expanded 0;
BA_ "GenSigTimeoutTime_ECM" SG_ 1440 ETM_HUD_Zone4_Expanded 0;
BA_ "GenSigTimeoutTime_DTCM" SG_ 1440 ETM_HUD_Zone4_Expanded 0;
BA_ "GenSigTimeoutTime_DMSM" SG_ 1440 ETM_HUD_Zone4_Expanded 0;
BA_ "GenSigTimeoutTime_BSM" SG_ 1440 ETM_HUD_Zone4_Expanded 0;
BA_ "GenSigTimeoutTime_BCM" SG_ 1440 ETM_HUD_Zone4_Expanded 0;
BA_ "GenSigTimeoutTime_AGSM" SG_ 1440 ETM_HUD_Zone4_Expanded 0;
BA_ "GenSigTimeoutTime_ADCAM" SG_ 1440 ETM_HUD_Zone4_Expanded 0;
BA_ "GenSigSendType" SG_ 1440 ETM_HUD_Zone4_Expanded 4;
BA_ "GenSigTimeoutTime_SGW" SG_ 1440 ETM_HUD_Zone5_Expanded 0;
BA_ "GenSigTimeoutTime_RFHM" SG_ 1440 ETM_HUD_Zone5_Expanded 0;
BA_ "GenSigTimeoutTime_MPAD" SG_ 1440 ETM_HUD_Zone5_Expanded 0;
BA_ "GenSigTimeoutTime_GNMM" SG_ 1440 ETM_HUD_Zone5_Expanded 0;
BA_ "GenSigTimeoutTime_EVCU2" SG_ 1440 ETM_HUD_Zone5_Expanded 0;
BA_ "GenSigTimeoutTime_ESL" SG_ 1440 ETM_HUD_Zone5_Expanded 0;
BA_ "GenSigTimeoutTime_ECM" SG_ 1440 ETM_HUD_Zone5_Expanded 0;
BA_ "GenSigTimeoutTime_DTCM" SG_ 1440 ETM_HUD_Zone5_Expanded 0;
BA_ "GenSigTimeoutTime_DMSM" SG_ 1440 ETM_HUD_Zone5_Expanded 0;
BA_ "GenSigTimeoutTime_BSM" SG_ 1440 ETM_HUD_Zone5_Expanded 0;
BA_ "GenSigTimeoutTime_BCM" SG_ 1440 ETM_HUD_Zone5_Expanded 0;
BA_ "GenSigTimeoutTime_AGSM" SG_ 1440 ETM_HUD_Zone5_Expanded 0;
BA_ "GenSigTimeoutTime_ADCAM" SG_ 1440 ETM_HUD_Zone5_Expanded 0;
BA_ "GenSigSendType" SG_ 1440 ETM_HUD_Zone5_Expanded 4;
BA_ "GenSigTimeoutTime_SGW" SG_ 1440 ETM_HUD_Zone1_Expanded 0;
BA_ "GenSigTimeoutTime_RFHM" SG_ 1440 ETM_HUD_Zone1_Expanded 0;
BA_ "GenSigTimeoutTime_MPAD" SG_ 1440 ETM_HUD_Zone1_Expanded 0;
BA_ "GenSigTimeoutTime_GNMM" SG_ 1440 ETM_HUD_Zone1_Expanded 0;
BA_ "GenSigTimeoutTime_EVCU2" SG_ 1440 ETM_HUD_Zone1_Expanded 0;
BA_ "GenSigTimeoutTime_ESL" SG_ 1440 ETM_HUD_Zone1_Expanded 0;
BA_ "GenSigTimeoutTime_ECM" SG_ 1440 ETM_HUD_Zone1_Expanded 0;
BA_ "GenSigTimeoutTime_DTCM" SG_ 1440 ETM_HUD_Zone1_Expanded 0;
BA_ "GenSigTimeoutTime_DMSM" SG_ 1440 ETM_HUD_Zone1_Expanded 0;
BA_ "GenSigTimeoutTime_BSM" SG_ 1440 ETM_HUD_Zone1_Expanded 0;
BA_ "GenSigTimeoutTime_BCM" SG_ 1440 ETM_HUD_Zone1_Expanded 0;
BA_ "GenSigTimeoutTime_AGSM" SG_ 1440 ETM_HUD_Zone1_Expanded 0;
BA_ "GenSigTimeoutTime_ADCAM" SG_ 1440 ETM_HUD_Zone1_Expanded 0;
BA_ "GenSigSendType" SG_ 1440 ETM_HUD_Zone1_Expanded 4;
BA_ "GenSigTimeoutTime_SGW" SG_ 1440 ETM_HUD_Zone2_Expanded 0;
BA_ "GenSigTimeoutTime_RFHM" SG_ 1440 ETM_HUD_Zone2_Expanded 0;
BA_ "GenSigTimeoutTime_MPAD" SG_ 1440 ETM_HUD_Zone2_Expanded 0;
BA_ "GenSigTimeoutTime_GNMM" SG_ 1440 ETM_HUD_Zone2_Expanded 0;
BA_ "GenSigTimeoutTime_EVCU2" SG_ 1440 ETM_HUD_Zone2_Expanded 0;
BA_ "GenSigTimeoutTime_ESL" SG_ 1440 ETM_HUD_Zone2_Expanded 0;
BA_ "GenSigTimeoutTime_ECM" SG_ 1440 ETM_HUD_Zone2_Expanded 0;
BA_ "GenSigTimeoutTime_DTCM" SG_ 1440 ETM_HUD_Zone2_Expanded 0;
BA_ "GenSigTimeoutTime_DMSM" SG_ 1440 ETM_HUD_Zone2_Expanded 0;
BA_ "GenSigTimeoutTime_BSM" SG_ 1440 ETM_HUD_Zone2_Expanded 0;
BA_ "GenSigTimeoutTime_BCM" SG_ 1440 ETM_HUD_Zone2_Expanded 0;
BA_ "GenSigTimeoutTime_AGSM" SG_ 1440 ETM_HUD_Zone2_Expanded 0;
BA_ "GenSigTimeoutTime_ADCAM" SG_ 1440 ETM_HUD_Zone2_Expanded 0;
BA_ "GenSigSendType" SG_ 1440 ETM_HUD_Zone2_Expanded 4;
BA_ "GenSigTimeoutTime_SGW" SG_ 1440 ETM_HUD_Zone3_Expanded 0;
BA_ "GenSigTimeoutTime_RFHM" SG_ 1440 ETM_HUD_Zone3_Expanded 0;
BA_ "GenSigTimeoutTime_MPAD" SG_ 1440 ETM_HUD_Zone3_Expanded 0;
BA_ "GenSigTimeoutTime_GNMM" SG_ 1440 ETM_HUD_Zone3_Expanded 0;
BA_ "GenSigTimeoutTime_EVCU2" SG_ 1440 ETM_HUD_Zone3_Expanded 0;
BA_ "GenSigTimeoutTime_ESL" SG_ 1440 ETM_HUD_Zone3_Expanded 0;
BA_ "GenSigTimeoutTime_ECM" SG_ 1440 ETM_HUD_Zone3_Expanded 0;
BA_ "GenSigTimeoutTime_DTCM" SG_ 1440 ETM_HUD_Zone3_Expanded 0;
BA_ "GenSigTimeoutTime_DMSM" SG_ 1440 ETM_HUD_Zone3_Expanded 0;
BA_ "GenSigTimeoutTime_BSM" SG_ 1440 ETM_HUD_Zone3_Expanded 0;
BA_ "GenSigTimeoutTime_BCM" SG_ 1440 ETM_HUD_Zone3_Expanded 0;
BA_ "GenSigTimeoutTime_AGSM" SG_ 1440 ETM_HUD_Zone3_Expanded 0;
BA_ "GenSigTimeoutTime_ADCAM" SG_ 1440 ETM_HUD_Zone3_Expanded 0;
BA_ "GenSigSendType" SG_ 1440 ETM_HUD_Zone3_Expanded 4;
BA_ "GenSigTimeoutTime_SGW" SG_ 1478 MessageCounter_TPM1 0;
BA_ "GenSigTimeoutTime_RFHM" SG_ 1478 MessageCounter_TPM1 0;
BA_ "GenSigTimeoutTime_MPAD" SG_ 1478 MessageCounter_TPM1 0;
BA_ "GenSigTimeoutTime_GNMM" SG_ 1478 MessageCounter_TPM1 0;
BA_ "GenSigTimeoutTime_EVCU2" SG_ 1478 MessageCounter_TPM1 0;
BA_ "GenSigTimeoutTime_ESL" SG_ 1478 MessageCounter_TPM1 0;
BA_ "GenSigTimeoutTime_ECM" SG_ 1478 MessageCounter_TPM1 0;
BA_ "GenSigTimeoutTime_DTCM" SG_ 1478 MessageCounter_TPM1 0;
BA_ "GenSigTimeoutTime_DMSM" SG_ 1478 MessageCounter_TPM1 0;
BA_ "GenSigTimeoutTime_BSM" SG_ 1478 MessageCounter_TPM1 0;
BA_ "GenSigTimeoutTime_BCM" SG_ 1478 MessageCounter_TPM1 0;
BA_ "GenSigTimeoutTime_AGSM" SG_ 1478 MessageCounter_TPM1 0;
BA_ "GenSigTimeoutTime_ADCAM" SG_ 1478 MessageCounter_TPM1 0;
BA_ "GenSigTimeoutTime_SGW" SG_ 1478 CRC_TPM1 0;
BA_ "GenSigTimeoutTime_RFHM" SG_ 1478 CRC_TPM1 0;
BA_ "GenSigTimeoutTime_MPAD" SG_ 1478 CRC_TPM1 0;
BA_ "GenSigTimeoutTime_GNMM" SG_ 1478 CRC_TPM1 0;
BA_ "GenSigTimeoutTime_EVCU2" SG_ 1478 CRC_TPM1 0;
BA_ "GenSigTimeoutTime_ESL" SG_ 1478 CRC_TPM1 0;
BA_ "GenSigTimeoutTime_ECM" SG_ 1478 CRC_TPM1 0;
BA_ "GenSigTimeoutTime_DTCM" SG_ 1478 CRC_TPM1 0;
BA_ "GenSigTimeoutTime_DMSM" SG_ 1478 CRC_TPM1 0;
BA_ "GenSigTimeoutTime_BSM" SG_ 1478 CRC_TPM1 0;
BA_ "GenSigTimeoutTime_BCM" SG_ 1478 CRC_TPM1 0;
BA_ "GenSigTimeoutTime_AGSM" SG_ 1478 CRC_TPM1 0;
BA_ "GenSigTimeoutTime_ADCAM" SG_ 1478 CRC_TPM1 0;
BA_ "GenSigTimeoutTime_SGW" SG_ 204 Rear_Axle_Est_Regen_Torq 0;
BA_ "GenSigTimeoutTime_RFHM" SG_ 204 Rear_Axle_Est_Regen_Torq 0;
BA_ "GenSigTimeoutTime_MPAD" SG_ 204 Rear_Axle_Est_Regen_Torq 0;
BA_ "GenSigTimeoutTime_IPC" SG_ 204 Rear_Axle_Est_Regen_Torq 0;
BA_ "GenSigTimeoutTime_GNMM" SG_ 204 Rear_Axle_Est_Regen_Torq 0;
BA_ "GenSigTimeoutTime_EVCU2" SG_ 204 Rear_Axle_Est_Regen_Torq 0;
BA_ "GenSigTimeoutTime_ESL" SG_ 204 Rear_Axle_Est_Regen_Torq 0;
BA_ "GenSigTimeoutTime_ECM" SG_ 204 Rear_Axle_Est_Regen_Torq 0;
BA_ "GenSigTimeoutTime_DTCM" SG_ 204 Rear_Axle_Est_Regen_Torq 0;
BA_ "GenSigTimeoutTime_DMSM" SG_ 204 Rear_Axle_Est_Regen_Torq 0;
BA_ "GenSigTimeoutTime_BCM" SG_ 204 Rear_Axle_Est_Regen_Torq 0;
BA_ "GenSigTimeoutTime_AGSM" SG_ 204 Rear_Axle_Est_Regen_Torq 0;
BA_ "GenSigTimeoutTime_ADCAM" SG_ 204 Rear_Axle_Est_Regen_Torq 0;
BA_ "GenSigTimeoutTime_SGW" SG_ 204 MessageCounter_AXLE_TORQUE_FD_1 0;
BA_ "GenSigTimeoutTime_RFHM" SG_ 204 MessageCounter_AXLE_TORQUE_FD_1 0;
BA_ "GenSigTimeoutTime_MPAD" SG_ 204 MessageCounter_AXLE_TORQUE_FD_1 0;
BA_ "GenSigTimeoutTime_IPC" SG_ 204 MessageCounter_AXLE_TORQUE_FD_1 0;
BA_ "GenSigTimeoutTime_GNMM" SG_ 204 MessageCounter_AXLE_TORQUE_FD_1 0;
BA_ "GenSigTimeoutTime_EVCU2" SG_ 204 MessageCounter_AXLE_TORQUE_FD_1 0;
BA_ "GenSigTimeoutTime_ESL" SG_ 204 MessageCounter_AXLE_TORQUE_FD_1 0;
BA_ "GenSigTimeoutTime_ECM" SG_ 204 MessageCounter_AXLE_TORQUE_FD_1 0;
BA_ "GenSigTimeoutTime_DMSM" SG_ 204 MessageCounter_AXLE_TORQUE_FD_1 0;
BA_ "GenSigTimeoutTime_BSM" SG_ 204 MessageCounter_AXLE_TORQUE_FD_1 0;
BA_ "GenSigTimeoutTime_BCM" SG_ 204 MessageCounter_AXLE_TORQUE_FD_1 0;
BA_ "GenSigTimeoutTime_AGSM" SG_ 204 MessageCounter_AXLE_TORQUE_FD_1 0;
BA_ "GenSigTimeoutTime_ADCAM" SG_ 204 MessageCounter_AXLE_TORQUE_FD_1 0;
BA_ "GenSigTimeoutTime_SGW" SG_ 204 Rear_Axle_Regen_Capacity 0;
BA_ "GenSigTimeoutTime_RFHM" SG_ 204 Rear_Axle_Regen_Capacity 0;
BA_ "GenSigTimeoutTime_MPAD" SG_ 204 Rear_Axle_Regen_Capacity 0;
BA_ "GenSigTimeoutTime_IPC" SG_ 204 Rear_Axle_Regen_Capacity 0;
BA_ "GenSigTimeoutTime_GNMM" SG_ 204 Rear_Axle_Regen_Capacity 0;
BA_ "GenSigTimeoutTime_EVCU2" SG_ 204 Rear_Axle_Regen_Capacity 0;
BA_ "GenSigTimeoutTime_ESL" SG_ 204 Rear_Axle_Regen_Capacity 0;
BA_ "GenSigTimeoutTime_ECM" SG_ 204 Rear_Axle_Regen_Capacity 0;
BA_ "GenSigTimeoutTime_DTCM" SG_ 204 Rear_Axle_Regen_Capacity 0;
BA_ "GenSigTimeoutTime_DMSM" SG_ 204 Rear_Axle_Regen_Capacity 0;
BA_ "GenSigTimeoutTime_BCM" SG_ 204 Rear_Axle_Regen_Capacity 0;
BA_ "GenSigTimeoutTime_AGSM" SG_ 204 Rear_Axle_Regen_Capacity 0;
BA_ "GenSigTimeoutTime_ADCAM" SG_ 204 Rear_Axle_Regen_Capacity 0;
BA_ "GenSigTimeoutTime_SGW" SG_ 204 Total_AxleTorque_Min 0;
BA_ "GenSigTimeoutTime_RFHM" SG_ 204 Total_AxleTorque_Min 0;
BA_ "GenSigTimeoutTime_MPAD" SG_ 204 Total_AxleTorque_Min 0;
BA_ "GenSigTimeoutTime_IPC" SG_ 204 Total_AxleTorque_Min 0;
BA_ "GenSigTimeoutTime_GNMM" SG_ 204 Total_AxleTorque_Min 0;
BA_ "GenSigTimeoutTime_EVCU2" SG_ 204 Total_AxleTorque_Min 0;
BA_ "GenSigTimeoutTime_ESL" SG_ 204 Total_AxleTorque_Min 0;
BA_ "GenSigTimeoutTime_ECM" SG_ 204 Total_AxleTorque_Min 0;
BA_ "GenSigTimeoutTime_DMSM" SG_ 204 Total_AxleTorque_Min 0;
BA_ "GenSigTimeoutTime_BCM" SG_ 204 Total_AxleTorque_Min 0;
BA_ "GenSigTimeoutTime_AGSM" SG_ 204 Total_AxleTorque_Min 0;
BA_ "GenSigTimeoutTime_ADCAM" SG_ 204 Total_AxleTorque_Min 0;
BA_ "GenSigStartValue" SG_ 204 Total_AxleTorque_Min 32767;
BA_ "GenSigTimeoutTime_SGW" SG_ 204 Total_AxleTorque_Max 0;
BA_ "GenSigTimeoutTime_RFHM" SG_ 204 Total_AxleTorque_Max 0;
BA_ "GenSigTimeoutTime_MPAD" SG_ 204 Total_AxleTorque_Max 0;
BA_ "GenSigTimeoutTime_IPC" SG_ 204 Total_AxleTorque_Max 0;
BA_ "GenSigTimeoutTime_GNMM" SG_ 204 Total_AxleTorque_Max 0;
BA_ "GenSigTimeoutTime_EVCU2" SG_ 204 Total_AxleTorque_Max 0;
BA_ "GenSigTimeoutTime_ESL" SG_ 204 Total_AxleTorque_Max 0;
BA_ "GenSigTimeoutTime_ECM" SG_ 204 Total_AxleTorque_Max 0;
BA_ "GenSigTimeoutTime_DMSM" SG_ 204 Total_AxleTorque_Max 0;
BA_ "GenSigTimeoutTime_AGSM" SG_ 204 Total_AxleTorque_Max 0;
BA_ "GenSigTimeoutTime_ADCAM" SG_ 204 Total_AxleTorque_Max 0;
BA_ "GenSigStartValue" SG_ 204 Total_AxleTorque_Max 32767;
BA_ "GenSigTimeoutTime_SGW" SG_ 204 MaxRegen_Diff_Axle_Torq_Active 0;
BA_ "GenSigTimeoutTime_RFHM" SG_ 204 MaxRegen_Diff_Axle_Torq_Active 0;
BA_ "GenSigTimeoutTime_MPAD" SG_ 204 MaxRegen_Diff_Axle_Torq_Active 0;
BA_ "GenSigTimeoutTime_IPC" SG_ 204 MaxRegen_Diff_Axle_Torq_Active 0;
BA_ "GenSigTimeoutTime_GNMM" SG_ 204 MaxRegen_Diff_Axle_Torq_Active 0;
BA_ "GenSigTimeoutTime_EVCU2" SG_ 204 MaxRegen_Diff_Axle_Torq_Active 0;
BA_ "GenSigTimeoutTime_ESL" SG_ 204 MaxRegen_Diff_Axle_Torq_Active 0;
BA_ "GenSigTimeoutTime_ECM" SG_ 204 MaxRegen_Diff_Axle_Torq_Active 0;
BA_ "GenSigTimeoutTime_DTCM" SG_ 204 MaxRegen_Diff_Axle_Torq_Active 0;
BA_ "GenSigTimeoutTime_DMSM" SG_ 204 MaxRegen_Diff_Axle_Torq_Active 0;
BA_ "GenSigTimeoutTime_BCM" SG_ 204 MaxRegen_Diff_Axle_Torq_Active 0;
BA_ "GenSigTimeoutTime_AGSM" SG_ 204 MaxRegen_Diff_Axle_Torq_Active 0;
BA_ "GenSigTimeoutTime_ADCAM" SG_ 204 MaxRegen_Diff_Axle_Torq_Active 0;
BA_ "GenSigTimeoutTime_RFHM" SG_ 204 Rear_AxleTorque_Max 0;
BA_ "GenSigTimeoutTime_MPAD" SG_ 204 Rear_AxleTorque_Max 0;
BA_ "GenSigTimeoutTime_IPC" SG_ 204 Rear_AxleTorque_Max 0;
BA_ "GenSigTimeoutTime_GNMM" SG_ 204 Rear_AxleTorque_Max 0;
BA_ "GenSigTimeoutTime_EVCU2" SG_ 204 Rear_AxleTorque_Max 0;
BA_ "GenSigTimeoutTime_ESL" SG_ 204 Rear_AxleTorque_Max 0;
BA_ "GenSigTimeoutTime_ECM" SG_ 204 Rear_AxleTorque_Max 0;
BA_ "GenSigTimeoutTime_DTCM" SG_ 204 Rear_AxleTorque_Max 0;
BA_ "GenSigTimeoutTime_DMSM" SG_ 204 Rear_AxleTorque_Max 0;
BA_ "GenSigTimeoutTime_BCM" SG_ 204 Rear_AxleTorque_Max 0;
BA_ "GenSigTimeoutTime_AGSM" SG_ 204 Rear_AxleTorque_Max 0;
BA_ "GenSigTimeoutTime_ADCAM" SG_ 204 Rear_AxleTorque_Max 0;
BA_ "GenSigStartValue" SG_ 204 Rear_AxleTorque_Max 32767;
BA_ "GenSigTimeoutTime_RFHM" SG_ 204 Rear_AxleTorque_Min 0;
BA_ "GenSigTimeoutTime_MPAD" SG_ 204 Rear_AxleTorque_Min 0;
BA_ "GenSigTimeoutTime_IPC" SG_ 204 Rear_AxleTorque_Min 0;
BA_ "GenSigTimeoutTime_GNMM" SG_ 204 Rear_AxleTorque_Min 0;
BA_ "GenSigTimeoutTime_EVCU2" SG_ 204 Rear_AxleTorque_Min 0;
BA_ "GenSigTimeoutTime_ESL" SG_ 204 Rear_AxleTorque_Min 0;
BA_ "GenSigTimeoutTime_ECM" SG_ 204 Rear_AxleTorque_Min 0;
BA_ "GenSigTimeoutTime_DTCM" SG_ 204 Rear_AxleTorque_Min 0;
BA_ "GenSigTimeoutTime_DMSM" SG_ 204 Rear_AxleTorque_Min 0;
BA_ "GenSigTimeoutTime_BCM" SG_ 204 Rear_AxleTorque_Min 0;
BA_ "GenSigTimeoutTime_AGSM" SG_ 204 Rear_AxleTorque_Min 0;
BA_ "GenSigTimeoutTime_ADCAM" SG_ 204 Rear_AxleTorque_Min 0;
BA_ "GenSigStartValue" SG_ 204 Rear_AxleTorque_Min 32767;
BA_ "GenSigTimeoutTime_RFHM" SG_ 204 Front_AxleTorque_Min 0;
BA_ "GenSigTimeoutTime_MPAD" SG_ 204 Front_AxleTorque_Min 0;
BA_ "GenSigTimeoutTime_IPC" SG_ 204 Front_AxleTorque_Min 0;
BA_ "GenSigTimeoutTime_GNMM" SG_ 204 Front_AxleTorque_Min 0;
BA_ "GenSigTimeoutTime_EVCU2" SG_ 204 Front_AxleTorque_Min 0;
BA_ "GenSigTimeoutTime_ESL" SG_ 204 Front_AxleTorque_Min 0;
BA_ "GenSigTimeoutTime_ECM" SG_ 204 Front_AxleTorque_Min 0;
BA_ "GenSigTimeoutTime_DTCM" SG_ 204 Front_AxleTorque_Min 0;
BA_ "GenSigTimeoutTime_DMSM" SG_ 204 Front_AxleTorque_Min 0;
BA_ "GenSigTimeoutTime_BCM" SG_ 204 Front_AxleTorque_Min 0;
BA_ "GenSigTimeoutTime_AGSM" SG_ 204 Front_AxleTorque_Min 0;
BA_ "GenSigTimeoutTime_ADCAM" SG_ 204 Front_AxleTorque_Min 0;
BA_ "GenSigStartValue" SG_ 204 Front_AxleTorque_Min 32767;
BA_ "GenSigTimeoutTime_SGW" SG_ 204 MaxRegen_Diff_Axle_Torq 0;
BA_ "GenSigTimeoutTime_RFHM" SG_ 204 MaxRegen_Diff_Axle_Torq 0;
BA_ "GenSigTimeoutTime_MPAD" SG_ 204 MaxRegen_Diff_Axle_Torq 0;
BA_ "GenSigTimeoutTime_IPC" SG_ 204 MaxRegen_Diff_Axle_Torq 0;
BA_ "GenSigTimeoutTime_GNMM" SG_ 204 MaxRegen_Diff_Axle_Torq 0;
BA_ "GenSigTimeoutTime_EVCU2" SG_ 204 MaxRegen_Diff_Axle_Torq 0;
BA_ "GenSigTimeoutTime_ESL" SG_ 204 MaxRegen_Diff_Axle_Torq 0;
BA_ "GenSigTimeoutTime_ECM" SG_ 204 MaxRegen_Diff_Axle_Torq 0;
BA_ "GenSigTimeoutTime_DTCM" SG_ 204 MaxRegen_Diff_Axle_Torq 0;
BA_ "GenSigTimeoutTime_DMSM" SG_ 204 MaxRegen_Diff_Axle_Torq 0;
BA_ "GenSigTimeoutTime_BCM" SG_ 204 MaxRegen_Diff_Axle_Torq 0;
BA_ "GenSigTimeoutTime_AGSM" SG_ 204 MaxRegen_Diff_Axle_Torq 0;
BA_ "GenSigTimeoutTime_ADCAM" SG_ 204 MaxRegen_Diff_Axle_Torq 0;
BA_ "GenSigTimeoutTime_RFHM" SG_ 204 Front_AxleTorque_Max 0;
BA_ "GenSigTimeoutTime_MPAD" SG_ 204 Front_AxleTorque_Max 0;
BA_ "GenSigTimeoutTime_IPC" SG_ 204 Front_AxleTorque_Max 0;
BA_ "GenSigTimeoutTime_GNMM" SG_ 204 Front_AxleTorque_Max 0;
BA_ "GenSigTimeoutTime_EVCU2" SG_ 204 Front_AxleTorque_Max 0;
BA_ "GenSigTimeoutTime_ESL" SG_ 204 Front_AxleTorque_Max 0;
BA_ "GenSigTimeoutTime_ECM" SG_ 204 Front_AxleTorque_Max 0;
BA_ "GenSigTimeoutTime_DTCM" SG_ 204 Front_AxleTorque_Max 0;
BA_ "GenSigTimeoutTime_SGW" SG_ 1316 OffRd_RR_Lvl 0;
BA_ "GenSigTimeoutTime_RFHM" SG_ 1316 OffRd_RR_Lvl 0;
BA_ "GenSigTimeoutTime_MPAD" SG_ 1316 OffRd_RR_Lvl 0;
BA_ "GenSigTimeoutTime_GNMM" SG_ 1316 OffRd_RR_Lvl 0;
BA_ "GenSigTimeoutTime_EVCU2" SG_ 1316 OffRd_RR_Lvl 0;
BA_ "GenSigTimeoutTime_ESL" SG_ 1316 OffRd_RR_Lvl 0;
BA_ "GenSigTimeoutTime_ECM" SG_ 1316 OffRd_RR_Lvl 0;
BA_ "GenSigTimeoutTime_DTCM" SG_ 1316 OffRd_RR_Lvl 0;
BA_ "GenSigTimeoutTime_DMSM" SG_ 1316 OffRd_RR_Lvl 0;
BA_ "GenSigTimeoutTime_BSM" SG_ 1316 OffRd_RR_Lvl 0;
BA_ "GenSigTimeoutTime_BCM" SG_ 1316 OffRd_RR_Lvl 0;
BA_ "GenSigTimeoutTime_AGSM" SG_ 1316 OffRd_RR_Lvl 0;
BA_ "GenSigTimeoutTime_ADCAM" SG_ 1316 OffRd_RR_Lvl 0;
BA_ "GenSigStartValue" SG_ 1316 OffRd_RR_Lvl 254;
BA_ "GenSigTimeoutTime_SGW" SG_ 1316 OffRd_RL_Lvl 0;
BA_ "GenSigTimeoutTime_RFHM" SG_ 1316 OffRd_RL_Lvl 0;
BA_ "GenSigTimeoutTime_MPAD" SG_ 1316 OffRd_RL_Lvl 0;
BA_ "GenSigTimeoutTime_GNMM" SG_ 1316 OffRd_RL_Lvl 0;
BA_ "GenSigTimeoutTime_EVCU2" SG_ 1316 OffRd_RL_Lvl 0;
BA_ "GenSigTimeoutTime_ESL" SG_ 1316 OffRd_RL_Lvl 0;
BA_ "GenSigTimeoutTime_ECM" SG_ 1316 OffRd_RL_Lvl 0;
BA_ "GenSigTimeoutTime_DTCM" SG_ 1316 OffRd_RL_Lvl 0;
BA_ "GenSigTimeoutTime_DMSM" SG_ 1316 OffRd_RL_Lvl 0;
BA_ "GenSigTimeoutTime_BSM" SG_ 1316 OffRd_RL_Lvl 0;
BA_ "GenSigTimeoutTime_BCM" SG_ 1316 OffRd_RL_Lvl 0;
BA_ "GenSigTimeoutTime_AGSM" SG_ 1316 OffRd_RL_Lvl 0;
BA_ "GenSigTimeoutTime_ADCAM" SG_ 1316 OffRd_RL_Lvl 0;
BA_ "GenSigStartValue" SG_ 1316 OffRd_RL_Lvl 254;
BA_ "GenSigTimeoutTime_SGW" SG_ 1316 OffRd_FL_Lvl 0;
BA_ "GenSigTimeoutTime_RFHM" SG_ 1316 OffRd_FL_Lvl 0;
BA_ "GenSigTimeoutTime_MPAD" SG_ 1316 OffRd_FL_Lvl 0;
BA_ "GenSigTimeoutTime_GNMM" SG_ 1316 OffRd_FL_Lvl 0;
BA_ "GenSigTimeoutTime_EVCU2" SG_ 1316 OffRd_FL_Lvl 0;
BA_ "GenSigTimeoutTime_ESL" SG_ 1316 OffRd_FL_Lvl 0;
BA_ "GenSigTimeoutTime_ECM" SG_ 1316 OffRd_FL_Lvl 0;
BA_ "GenSigTimeoutTime_DTCM" SG_ 1316 OffRd_FL_Lvl 0;
BA_ "GenSigTimeoutTime_DMSM" SG_ 1316 OffRd_FL_Lvl 0;
BA_ "GenSigTimeoutTime_BSM" SG_ 1316 OffRd_FL_Lvl 0;
BA_ "GenSigTimeoutTime_BCM" SG_ 1316 OffRd_FL_Lvl 0;
BA_ "GenSigTimeoutTime_AGSM" SG_ 1316 OffRd_FL_Lvl 0;
BA_ "GenSigTimeoutTime_ADCAM" SG_ 1316 OffRd_FL_Lvl 0;
BA_ "GenSigStartValue" SG_ 1316 OffRd_FL_Lvl 254;
BA_ "GenSigTimeoutTime_SGW" SG_ 1316 OffRd_FR_Lvl 0;
BA_ "GenSigTimeoutTime_RFHM" SG_ 1316 OffRd_FR_Lvl 0;
BA_ "GenSigTimeoutTime_MPAD" SG_ 1316 OffRd_FR_Lvl 0;
BA_ "GenSigTimeoutTime_GNMM" SG_ 1316 OffRd_FR_Lvl 0;
BA_ "GenSigTimeoutTime_EVCU2" SG_ 1316 OffRd_FR_Lvl 0;
BA_ "GenSigTimeoutTime_ESL" SG_ 1316 OffRd_FR_Lvl 0;
BA_ "GenSigTimeoutTime_ECM" SG_ 1316 OffRd_FR_Lvl 0;
BA_ "GenSigTimeoutTime_DTCM" SG_ 1316 OffRd_FR_Lvl 0;
BA_ "GenSigTimeoutTime_DMSM" SG_ 1316 OffRd_FR_Lvl 0;
BA_ "GenSigTimeoutTime_BSM" SG_ 1316 OffRd_FR_Lvl 0;
BA_ "GenSigTimeoutTime_BCM" SG_ 1316 OffRd_FR_Lvl 0;
BA_ "GenSigTimeoutTime_AGSM" SG_ 1316 OffRd_FR_Lvl 0;
BA_ "GenSigTimeoutTime_ADCAM" SG_ 1316 OffRd_FR_Lvl 0;
BA_ "GenSigStartValue" SG_ 1316 OffRd_FR_Lvl 254;
BA_ "GenSigTimeoutTime_SGW" SG_ 1439 AFLM_Fault 0;
BA_ "GenSigTimeoutTime_RFHM" SG_ 1439 AFLM_Fault 0;
BA_ "GenSigTimeoutTime_MPAD" SG_ 1439 AFLM_Fault 0;
BA_ "GenSigTimeoutTime_GNMM" SG_ 1439 AFLM_Fault 0;
BA_ "GenSigTimeoutTime_EVCU2" SG_ 1439 AFLM_Fault 0;
BA_ "GenSigTimeoutTime_ESL" SG_ 1439 AFLM_Fault 0;
BA_ "GenSigTimeoutTime_ECM" SG_ 1439 AFLM_Fault 0;
BA_ "GenSigTimeoutTime_DTCM" SG_ 1439 AFLM_Fault 0;
BA_ "GenSigTimeoutTime_DMSM" SG_ 1439 AFLM_Fault 0;
BA_ "GenSigTimeoutTime_BSM" SG_ 1439 AFLM_Fault 0;
BA_ "GenSigTimeoutTime_BCM" SG_ 1439 AFLM_Fault 0;
BA_ "GenSigTimeoutTime_AGSM" SG_ 1439 AFLM_Fault 0;
BA_ "GenSigTimeoutTime_ADCAM" SG_ 1439 AFLM_Fault 0;
BA_ "GenSigTimeoutTime_SGW" SG_ 204 CRC_AXLE_TORQUE_FD_1 0;
BA_ "GenSigTimeoutTime_RFHM" SG_ 204 CRC_AXLE_TORQUE_FD_1 0;
BA_ "GenSigTimeoutTime_MPAD" SG_ 204 CRC_AXLE_TORQUE_FD_1 0;
BA_ "GenSigTimeoutTime_IPC" SG_ 204 CRC_AXLE_TORQUE_FD_1 0;
BA_ "GenSigTimeoutTime_GNMM" SG_ 204 CRC_AXLE_TORQUE_FD_1 0;
BA_ "GenSigTimeoutTime_EVCU2" SG_ 204 CRC_AXLE_TORQUE_FD_1 0;
BA_ "GenSigTimeoutTime_ESL" SG_ 204 CRC_AXLE_TORQUE_FD_1 0;
BA_ "GenSigTimeoutTime_ECM" SG_ 204 CRC_AXLE_TORQUE_FD_1 0;
BA_ "GenSigTimeoutTime_DMSM" SG_ 204 CRC_AXLE_TORQUE_FD_1 0;
BA_ "GenSigTimeoutTime_BSM" SG_ 204 CRC_AXLE_TORQUE_FD_1 0;
BA_ "GenSigTimeoutTime_BCM" SG_ 204 CRC_AXLE_TORQUE_FD_1 0;
BA_ "GenSigTimeoutTime_AGSM" SG_ 204 CRC_AXLE_TORQUE_FD_1 0;
BA_ "GenSigTimeoutTime_ADCAM" SG_ 204 CRC_AXLE_TORQUE_FD_1 0;
BA_ "GenSigTimeoutTime_SGW" SG_ 204 Front_Axle_Regen_Capacity 0;
BA_ "GenSigTimeoutTime_RFHM" SG_ 204 Front_Axle_Regen_Capacity 0;
BA_ "GenSigTimeoutTime_MPAD" SG_ 204 Front_Axle_Regen_Capacity 0;
BA_ "GenSigTimeoutTime_IPC" SG_ 204 Front_Axle_Regen_Capacity 0;
BA_ "GenSigTimeoutTime_GNMM" SG_ 204 Front_Axle_Regen_Capacity 0;
BA_ "GenSigTimeoutTime_EVCU2" SG_ 204 Front_Axle_Regen_Capacity 0;
BA_ "GenSigTimeoutTime_ESL" SG_ 204 Front_Axle_Regen_Capacity 0;
BA_ "GenSigTimeoutTime_ECM" SG_ 204 Front_Axle_Regen_Capacity 0;
BA_ "GenSigTimeoutTime_DTCM" SG_ 204 Front_Axle_Regen_Capacity 0;
BA_ "GenSigTimeoutTime_DMSM" SG_ 204 Front_Axle_Regen_Capacity 0;
BA_ "GenSigTimeoutTime_BCM" SG_ 204 Front_Axle_Regen_Capacity 0;
BA_ "GenSigTimeoutTime_AGSM" SG_ 204 Front_Axle_Regen_Capacity 0;
BA_ "GenSigTimeoutTime_ADCAM" SG_ 204 Front_Axle_Regen_Capacity 0;
BA_ "GenSigTimeoutTime_SGW" SG_ 204 Front_Axle_Est_Regen_Torq 0;
BA_ "GenSigTimeoutTime_RFHM" SG_ 204 Front_Axle_Est_Regen_Torq 0;
BA_ "GenSigTimeoutTime_MPAD" SG_ 204 Front_Axle_Est_Regen_Torq 0;
BA_ "GenSigTimeoutTime_IPC" SG_ 204 Front_Axle_Est_Regen_Torq 0;
BA_ "GenSigTimeoutTime_GNMM" SG_ 204 Front_Axle_Est_Regen_Torq 0;
BA_ "GenSigTimeoutTime_EVCU2" SG_ 204 Front_Axle_Est_Regen_Torq 0;
BA_ "GenSigTimeoutTime_ESL" SG_ 204 Front_Axle_Est_Regen_Torq 0;
BA_ "GenSigTimeoutTime_ECM" SG_ 204 Front_Axle_Est_Regen_Torq 0;
BA_ "GenSigTimeoutTime_DTCM" SG_ 204 Front_Axle_Est_Regen_Torq 0;
BA_ "GenSigTimeoutTime_DMSM" SG_ 204 Front_Axle_Est_Regen_Torq 0;
BA_ "GenSigTimeoutTime_BCM" SG_ 204 Front_Axle_Est_Regen_Torq 0;
BA_ "GenSigTimeoutTime_AGSM" SG_ 204 Front_Axle_Est_Regen_Torq 0;
BA_ "GenSigTimeoutTime_ADCAM" SG_ 204 Front_Axle_Est_Regen_Torq 0;
BA_ "GenSigTimeoutTime_SGW" SG_ 204 Axle_Torque_DrvReqMod 0;
BA_ "GenSigTimeoutTime_RFHM" SG_ 204 Axle_Torque_DrvReqMod 0;
BA_ "GenSigTimeoutTime_MPAD" SG_ 204 Axle_Torque_DrvReqMod 0;
BA_ "GenSigTimeoutTime_IPC" SG_ 204 Axle_Torque_DrvReqMod 0;
BA_ "GenSigTimeoutTime_GNMM" SG_ 204 Axle_Torque_DrvReqMod 0;
BA_ "GenSigTimeoutTime_EVCU2" SG_ 204 Axle_Torque_DrvReqMod 0;
BA_ "GenSigTimeoutTime_ESL" SG_ 204 Axle_Torque_DrvReqMod 0;
BA_ "GenSigTimeoutTime_ECM" SG_ 204 Axle_Torque_DrvReqMod 0;
BA_ "GenSigTimeoutTime_DMSM" SG_ 204 Axle_Torque_DrvReqMod 0;
BA_ "GenSigTimeoutTime_AGSM" SG_ 204 Axle_Torque_DrvReqMod 0;
BA_ "GenSigTimeoutTime_ADCAM" SG_ 204 Axle_Torque_DrvReqMod 0;
BA_ "GenSigStartValue" SG_ 204 Axle_Torque_DrvReqMod 32768;
BA_ "GenSigTimeoutTime_SGW" SG_ 204 Axle_TorqueStatic_D_TTC 0;
BA_ "GenSigTimeoutTime_RFHM" SG_ 204 Axle_TorqueStatic_D_TTC 0;
BA_ "GenSigTimeoutTime_MPAD" SG_ 204 Axle_TorqueStatic_D_TTC 0;
BA_ "GenSigTimeoutTime_IPC" SG_ 204 Axle_TorqueStatic_D_TTC 0;
BA_ "GenSigTimeoutTime_GNMM" SG_ 204 Axle_TorqueStatic_D_TTC 0;
BA_ "GenSigTimeoutTime_EVCU2" SG_ 204 Axle_TorqueStatic_D_TTC 0;
BA_ "GenSigTimeoutTime_ESL" SG_ 204 Axle_TorqueStatic_D_TTC 0;
BA_ "GenSigTimeoutTime_ECM" SG_ 204 Axle_TorqueStatic_D_TTC 0;
BA_ "GenSigTimeoutTime_DMSM" SG_ 204 Axle_TorqueStatic_D_TTC 0;
BA_ "GenSigTimeoutTime_AGSM" SG_ 204 Axle_TorqueStatic_D_TTC 0;
BA_ "GenSigTimeoutTime_ADCAM" SG_ 204 Axle_TorqueStatic_D_TTC 0;
BA_ "GenSigStartValue" SG_ 204 Axle_TorqueStatic_D_TTC 32767;
BA_ "GenSigTimeoutTime_DMSM" SG_ 204 Front_AxleTorque_Max 0;
BA_ "GenSigTimeoutTime_BCM" SG_ 204 Front_AxleTorque_Max 0;
BA_ "GenSigTimeoutTime_AGSM" SG_ 204 Front_AxleTorque_Max 0;
BA_ "GenSigTimeoutTime_ADCAM" SG_ 204 Front_AxleTorque_Max 0;
BA_ "GenSigStartValue" SG_ 204 Front_AxleTorque_Max 32767;
BA_ "GenSigTimeoutTime_SGW" SG_ 105 LidOpeningAck 0;
BA_ "GenSigTimeoutTime_RFHM" SG_ 105 LidOpeningAck 0;
BA_ "GenSigTimeoutTime_MPAD" SG_ 105 LidOpeningAck 0;
BA_ "GenSigTimeoutTime_IPC" SG_ 105 LidOpeningAck 0;
BA_ "GenSigTimeoutTime_GNMM" SG_ 105 LidOpeningAck 0;
BA_ "GenSigTimeoutTime_EVCU2" SG_ 105 LidOpeningAck 0;
BA_ "GenSigTimeoutTime_ESL" SG_ 105 LidOpeningAck 0;
BA_ "GenSigTimeoutTime_ECM" SG_ 105 LidOpeningAck 0;
BA_ "GenSigTimeoutTime_DTCM" SG_ 105 LidOpeningAck 0;
BA_ "GenSigTimeoutTime_DMSM" SG_ 105 LidOpeningAck 0;
BA_ "GenSigTimeoutTime_BSM" SG_ 105 LidOpeningAck 0;
BA_ "GenSigTimeoutTime_BCM" SG_ 105 LidOpeningAck 0;
BA_ "GenSigTimeoutTime_AGSM" SG_ 105 LidOpeningAck 0;
BA_ "GenSigTimeoutTime_ADCAM" SG_ 105 LidOpeningAck 0;
BA_ "GenSigSendType" SG_ 105 LidOpeningAck 3;
BA_ "GenSigTimeoutTime_SGW" SG_ 105 LidClosingAck 0;
BA_ "GenSigTimeoutTime_RFHM" SG_ 105 LidClosingAck 0;
BA_ "GenSigTimeoutTime_MPAD" SG_ 105 LidClosingAck 0;
BA_ "GenSigTimeoutTime_IPC" SG_ 105 LidClosingAck 0;
BA_ "GenSigTimeoutTime_GNMM" SG_ 105 LidClosingAck 0;
BA_ "GenSigTimeoutTime_EVCU2" SG_ 105 LidClosingAck 0;
BA_ "GenSigTimeoutTime_ESL" SG_ 105 LidClosingAck 0;
BA_ "GenSigTimeoutTime_ECM" SG_ 105 LidClosingAck 0;
BA_ "GenSigTimeoutTime_DTCM" SG_ 105 LidClosingAck 0;
BA_ "GenSigTimeoutTime_DMSM" SG_ 105 LidClosingAck 0;
BA_ "GenSigTimeoutTime_BSM" SG_ 105 LidClosingAck 0;
BA_ "GenSigTimeoutTime_BCM" SG_ 105 LidClosingAck 0;
BA_ "GenSigTimeoutTime_AGSM" SG_ 105 LidClosingAck 0;
BA_ "GenSigTimeoutTime_ADCAM" SG_ 105 LidClosingAck 0;
BA_ "GenSigSendType" SG_ 105 LidClosingAck 3;
VAL_ 1474 SpeedLimitAdjust 0 "Off" 1 "Manual" 2 "Automatic";
VAL_ 1474 AssistedLaneChange 0 "Off" 1 "Driver_Initiated" 2 "System_Driver_Initiated" 3 "Not_Used";
VAL_ 205 WED_MODE_RQ 0 "FREE" 1 "HOLD" 2 "OPEN" 3 "SNA";
VAL_ 205 OPD_Hold_Status 0 "Inactive" 1 "Holding" 2 "Ready_to_Release" 3 "SNA";
VAL_ 1440 AUD_LVL 255 "SNA";
VAL_ 1426 VDCM_PopUpMessage5 0 "Not Available" 1 "level 1" 2 "level 2" 3 "level 3" 4 "level 4" 5 "level 5" 6 "level 0" 7 "SNA";
VAL_ 1426 EstRange 2047 "SNA";
VAL_ 1426 DC_EstChargeTime2 255 "SNA";
VAL_ 1426 DC_EstChargeTime1 255 "SNA";
VAL_ 1439 AFLM_Fault 0 "Not_Present" 1 "Present";
VAL_ 1462 TBM_Submit_ClimateSchd2 0 "No_Change" 1 "Change_in_schedule2";
VAL_ 1462 TBM_Submit_ClimateSchd1 0 "No_Change" 1 "Change_in_schedule1";
VAL_ 1462 TBM_Enable_ClimateSchd2 0 "Disable_schedule2" 1 "Enable_schedule2";
VAL_ 1462 TBM_Enable_ClimateSchd1 0 "Disable_schedule1" 1 "Enable_schedule1";
VAL_ 1462 TBM_ClimateSchd2_Departure_Min 15 "SNA";
VAL_ 1462 TBM_ClimateSchd2_Departure_Hr 31 "SNA";
VAL_ 1462 TBM_ClimateSchd2_Day 0 "No Selection" 1 "M" 2 "T" 3 "TM" 4 "W" 5 "WM" 6 "WT" 7 "WTM" 8 "Th" 9 "ThM" 10 "ThT" 11 "ThTM" 12 "ThW" 13 "ThWM" 14 "ThWT" 15 "ThWTM" 16 "F" 17 "FM" 18 "FT" 19 "FTM" 20 "FW" 21 "FWM" 22 "FWT" 23 "FWTM" 24 "FTh" 25 "FThM" 26 "FThT" 27 "FThTM" 28 "FThW" 29 "FThWM" 30 "FThWT" 31 "FThWTM" 32 "S" 33 "SM" 34 "ST" 35 "STM" 36 "SW" 37 "SWM" 38 "SWT" 39 "SWTM" 40 "STh" 41 "SThM" 42 "SThT" 43 "SThTM" 44 "SThW" 45 "SThWM" 46 "SThWT" 47 "SThWTM" 48 "SF" 49 "SFM" 50 "SFT" 51 "SFTM" 52 "SFW" 53 "SFWM" 54 "SFWT" 55 "SFWTM" 56 "SFTh" 57 "SFThM" 58 "SFThT" 59 "SFThTM" 60 "SFThW" 61 "SFThWM" 62 "SFThWT" 63 "SFThWTM" 64 "Su" 65 "SuM" 66 "SuT" 67 "SuTM" 68 "SuW" 69 "SuWM" 70 "SuWT" 71 "SuWTM" 72 "SuTh" 73 "SuThM" 74 "SuThT" 75 "SuThTM" 76 "SuThW" 77 "SuThWM" 78 "SuThWT" 79 "SuThWTM" 80 "SuF" 81 "SuFM" 82 "SuFT" 83 "SuFTM" 84 "SuFW" 85 "SuFWM" 86 "SuFWT" 87 "SuFWTM" 88 "SuFTh" 89 "SuFThM" 90 "SuFThT" 91 "SuFThTM" 92 "SuFThW" 93 "SuFThWM" 94 "SuFThWT" 95 "SuFThWTM" 96 "SuS" 97 "SuSM" 98 "SuST" 99 "SuSTM" 100 "SuSW" 101 "SuSWM" 102 "SuSWT" 103 "SuSWTM" 104 "SuSTh" 105 "SuSThM" 106 "SuSThT" 107 "SuSThTM" 108 "SuSThW" 109 "SuSThWM" 110 "SuSThWT" 111 "SuSThWTM" 112 "SuSF" 113 "SuSFM" 114 "SuSFT" 115 "SuSFTM" 116 "SuSFW" 117 "SuSFWM" 118 "SuSFWT" 119 "SuSFWTM" 120 "SuSFTh" 121 "SuSFThM" 122 "SuSFThT" 123 "SuSFThTM" 124 "SuSFThW" 125 "SuSFThWM" 126 "SuSFThWT" 127 "SuSFThWTM" 255 "SNA";
VAL_ 1462 TBM_ClimateSchd1_Departure_Min 15 "SNA";
VAL_ 1462 TBM_ClimateSchd1_Departure_Hr 31 "SNA";
VAL_ 2654339257 DES_FD09_WCPM2 0 "Error_Active_state" 1 "Error_passive_warning_state" 2 "Bus_off_state" 3 "Not_used";
VAL_ 2654339257 CurrentFailSts_FD09_WCPM2 0 "No_Fail_Present" 1 "Fail_Present";
VAL_ 1462 TBM_ClimateSchd1_Day 0 "No Selection" 1 "M" 2 "T" 3 "TM" 4 "W" 5 "WM" 6 "WT" 7 "WTM" 8 "Th" 9 "ThM" 10 "ThT" 11 "ThTM" 12 "ThW" 13 "ThWM" 14 "ThWT" 15 "ThWTM" 16 "F" 17 "FM" 18 "FT" 19 "FTM" 20 "FW" 21 "FWM" 22 "FWT" 23 "FWTM" 24 "FTh" 25 "FThM" 26 "FThT" 27 "FThTM" 28 "FThW" 29 "FThWM" 30 "FThWT" 31 "FThWTM" 32 "S" 33 "SM" 34 "ST" 35 "STM" 36 "SW" 37 "SWM" 38 "SWT" 39 "SWTM" 40 "STh" 41 "SThM" 42 "SThT" 43 "SThTM" 44 "SThW" 45 "SThWM" 46 "SThWT" 47 "SThWTM" 48 "SF" 49 "SFM" 50 "SFT" 51 "SFTM" 52 "SFW" 53 "SFWM" 54 "SFWT" 55 "SFWTM" 56 "SFTh" 57 "SFThM" 58 "SFThT" 59 "SFThTM" 60 "SFThW" 61 "SFThWM" 62 "SFThWT" 63 "SFThWTM" 64 "Su" 65 "SuM" 66 "SuT" 67 "SuTM" 68 "SuW" 69 "SuWM" 70 "SuWT" 71 "SuWTM" 72 "SuTh" 73 "SuThM" 74 "SuThT" 75 "SuThTM" 76 "SuThW" 77 "SuThWM" 78 "SuThWT" 79 "SuThWTM" 80 "SuF" 81 "SuFM" 82 "SuFT" 83 "SuFTM" 84 "SuFW" 85 "SuFWM" 86 "SuFWT" 87 "SuFWTM" 88 "SuFTh" 89 "SuFThM" 90 "SuFThT" 91 "SuFThTM" 92 "SuFThW" 93 "SuFThWM" 94 "SuFThWT" 95 "SuFThWTM" 96 "SuS" 97 "SuSM" 98 "SuST" 99 "SuSTM" 100 "SuSW" 101 "SuSWM" 102 "SuSWT" 103 "SuSWTM" 104 "SuSTh" 105 "SuSThM" 106 "SuSThT" 107 "SuSThTM" 108 "SuSThW" 109 "SuSThWM" 110 "SuSThWT" 111 "SuSThWTM" 112 "SuSF" 113 "SuSFM" 114 "SuSFT" 115 "SuSFTM" 116 "SuSFW" 117 "SuSFWM" 118 "SuSFWT" 119 "SuSFWTM" 120 "SuSFTh" 121 "SuSFThM" 122 "SuSFThT" 123 "SuSFThTM" 124 "SuSFThW" 125 "SuSFThWM" 126 "SuSFThWT" 127 "SuSFThWTM" 255 "SNA";
VAL_ 1462 TBM_AllowClimateSchd2 0 "Any_Time " 1 "Plugged_In_Only" 2 "Plugged_In_and_In_Charge_Schd" 3 "SNA";
VAL_ 1462 TBM_AllowClimateSchd1 0 "Any_Time " 1 "Plugged_In_Only" 2 "Plugged_In_and_In_Charge_Schd" 3 "SNA";
VAL_ 1462 Climate_TBM_Cabin_Temp2 31 "SNA";
VAL_ 1462 Climate_TBM_Cabin_Temp1 31 "SNA";
VAL_ 1471 Submit_ClimateSchd2 0 "No_Change" 1 "Change_in_schedule2";
VAL_ 1471 Submit_ClimateSchd1 0 "No_Change" 1 "Change_in_schedule1";
VAL_ 1471 Enable_ClimateSchd2 0 "Disable_schedule2" 1 "Enable_schedule2";
VAL_ 1471 Enable_ClimateSchd1 0 "Disable_schedule1" 1 "Enable_schedule1";
VAL_ 1471 ClimateSchd2_Departure_Min 15 "SNA";
VAL_ 1471 ClimateSchd2_Departure_Hr 31 "SNA";
VAL_ 1471 ClimateSchd2_Day 0 "No Selection" 1 "M" 2 "T" 3 "TM" 4 "W" 5 "WM" 6 "WT" 7 "WTM" 8 "Th" 9 "ThM" 10 "ThT" 11 "ThTM" 12 "ThW" 13 "ThWM" 14 "ThWT" 15 "ThWTM" 16 "F" 17 "FM" 18 "FT" 19 "FTM" 20 "FW" 21 "FWM" 22 "FWT" 23 "FWTM" 24 "FTh" 25 "FThM" 26 "FThT" 27 "FThTM" 28 "FThW" 29 "FThWM" 30 "FThWT" 31 "FThWTM" 32 "S" 33 "SM" 34 "ST" 35 "STM" 36 "SW" 37 "SWM" 38 "SWT" 39 "SWTM" 40 "STh" 41 "SThM" 42 "SThT" 43 "SThTM" 44 "SThW" 45 "SThWM" 46 "SThWT" 47 "SThWTM" 48 "SF" 49 "SFM" 50 "SFT" 51 "SFTM" 52 "SFW" 53 "SFWM" 54 "SFWT" 55 "SFWTM" 56 "SFTh" 57 "SFThM" 58 "SFThT" 59 "SFThTM" 60 "SFThW" 61 "SFThWM" 62 "SFThWT" 63 "SFThWTM" 64 "Su" 65 "SuM" 66 "SuT" 67 "SuTM" 68 "SuW" 69 "SuWM" 70 "SuWT" 71 "SuWTM" 72 "SuTh" 73 "SuThM" 74 "SuThT" 75 "SuThTM" 76 "SuThW" 77 "SuThWM" 78 "SuThWT" 79 "SuThWTM" 80 "SuF" 81 "SuFM" 82 "SuFT" 83 "SuFTM" 84 "SuFW" 85 "SuFWM" 86 "SuFWT" 87 "SuFWTM" 88 "SuFTh" 89 "SuFThM" 90 "SuFThT" 91 "SuFThTM" 92 "SuFThW" 93 "SuFThWM" 94 "SuFThWT" 95 "SuFThWTM" 96 "SuS" 97 "SuSM" 98 "SuST" 99 "SuSTM" 100 "SuSW" 101 "SuSWM" 102 "SuSWT" 103 "SuSWTM" 104 "SuSTh" 105 "SuSThM" 106 "SuSThT" 107 "SuSThTM" 108 "SuSThW" 109 "SuSThWM" 110 "SuSThWT" 111 "SuSThWTM" 112 "SuSF" 113 "SuSFM" 114 "SuSFT" 115 "SuSFTM" 116 "SuSFW" 117 "SuSFWM" 118 "SuSFWT" 119 "SuSFWTM" 120 "SuSFTh" 121 "SuSFThM" 122 "SuSFThT" 123 "SuSFThTM" 124 "SuSFThW" 125 "SuSFThWM" 126 "SuSFThWT" 127 "SuSFThWTM" 255 "SNA";
VAL_ 1471 ClimateSchd1_Departure_Min 15 "SNA";
VAL_ 1471 ClimateSchd1_Departure_Hr 31 "SNA";
VAL_ 2654339257 WakeupSource_FD09_WCPM2 0 "No_Wakeup" 1 "IGN_ON" 129 "FD1_Psv_WU" 130 "FD2_Psv_WU" 131 "FD3_Psv_WU" 132 "FD4_Psv_WU" 133 "FD5_Psv_WU" 134 "FD6_Psv_WU" 135 "FD7_Psv_WU" 136 "FD8_Psv_WU" 137 "FD9_Psv_WU" 138 "FD10_Psv_WU" 139 "FD11_Psv_WU" 140 "FD12_Psv_WU" 141 "FD13_Psv_WU" 142 "FD14_Psv_WU" 143 "FD15_Psv_WU" 144 "FD16_Psv_WU" 145 "FD17_Psv_WU" 146 "FD18_Psv_WU" 147 "FD19_Psv_WU" 148 "FD20_Psv_WU" 149 "FD21_Psv_WU" 150 "FD22_Psv_WU" 151 "FD23_Psv_WU" 152 "FD24_Psv_WU" 153 "FD25_Psv_WU" 154 "FD26_Psv_WU" 155 "FD27_Psv_WU" 156 "FD28_Psv_WU" 157 "FD29_Psv_WU" 158 "BHCAN_Psv_WU" 159 "CCAN_Psv_WU" 254 "WUSource_Not_Listed";
VAL_ 2654339257 PreviousCanNMState_FD09_WCPM2 0 "Uninitialized State" 1 "Bus-Sleep State" 2 "Prepare-Bus State" 3 "Ready-Sleep State" 4 "Normal Operation State" 5 "Repeat Message State" 6 "Synchronize State" 7 "Offline State";
VAL_ 2654339257 GenericFailSts_FD09_WCPM2 0 "No_Fail_Present" 1 "Fail_Present";
VAL_ 2654339257 EOL_FD09_WCPM2 0 "No_EOL_Programming" 1 "EOL_Programming";
VAL_ 1471 ClimateSchd1_Day 0 "No Selection" 1 "M" 2 "T" 3 "TM" 4 "W" 5 "WM" 6 "WT" 7 "WTM" 8 "Th" 9 "ThM" 10 "ThT" 11 "ThTM" 12 "ThW" 13 "ThWM" 14 "ThWT" 15 "ThWTM" 16 "F" 17 "FM" 18 "FT" 19 "FTM" 20 "FW" 21 "FWM" 22 "FWT" 23 "FWTM" 24 "FTh" 25 "FThM" 26 "FThT" 27 "FThTM" 28 "FThW" 29 "FThWM" 30 "FThWT" 31 "FThWTM" 32 "S" 33 "SM" 34 "ST" 35 "STM" 36 "SW" 37 "SWM" 38 "SWT" 39 "SWTM" 40 "STh" 41 "SThM" 42 "SThT" 43 "SThTM" 44 "SThW" 45 "SThWM" 46 "SThWT" 47 "SThWTM" 48 "SF" 49 "SFM" 50 "SFT" 51 "SFTM" 52 "SFW" 53 "SFWM" 54 "SFWT" 55 "SFWTM" 56 "SFTh" 57 "SFThM" 58 "SFThT" 59 "SFThTM" 60 "SFThW" 61 "SFThWM" 62 "SFThWT" 63 "SFThWTM" 64 "Su" 65 "SuM" 66 "SuT" 67 "SuTM" 68 "SuW" 69 "SuWM" 70 "SuWT" 71 "SuWTM" 72 "SuTh" 73 "SuThM" 74 "SuThT" 75 "SuThTM" 76 "SuThW" 77 "SuThWM" 78 "SuThWT" 79 "SuThWTM" 80 "SuF" 81 "SuFM" 82 "SuFT" 83 "SuFTM" 84 "SuFW" 85 "SuFWM" 86 "SuFWT" 87 "SuFWTM" 88 "SuFTh" 89 "SuFThM" 90 "SuFThT" 91 "SuFThTM" 92 "SuFThW" 93 "SuFThWM" 94 "SuFThWT" 95 "SuFThWTM" 96 "SuS" 97 "SuSM" 98 "SuST" 99 "SuSTM" 100 "SuSW" 101 "SuSWM" 102 "SuSWT" 103 "SuSWTM" 104 "SuSTh" 105 "SuSThM" 106 "SuSThT" 107 "SuSThTM" 108 "SuSThW" 109 "SuSThWM" 110 "SuSThWT" 111 "SuSThWTM" 112 "SuSF" 113 "SuSFM" 114 "SuSFT" 115 "SuSFTM" 116 "SuSFW" 117 "SuSFWM" 118 "SuSFWT" 119 "SuSFWTM" 120 "SuSFTh" 121 "SuSFThM" 122 "SuSFThT" 123 "SuSFThTM" 124 "SuSFThW" 125 "SuSFThWM" 126 "SuSFThWT" 127 "SuSFThWTM" 255 "SNA";
VAL_ 1471 Climate_Cabin_Temp2 31 "SNA";
VAL_ 1471 Climate_Cabin_Temp1 31 "SNA";
VAL_ 1471 AllowClimateSchd2 0 "Any_Time " 1 "Plugged_In_Only" 2 "Plugged_In_and_In_Charge_Schd" 3 "SNA";
VAL_ 1471 AllowClimateSchd1 0 "Any_Time " 1 "Plugged_In_Only" 2 "Plugged_In_and_In_Charge_Schd" 3 "SNA";
VAL_ 1468 Enable_ClimateSchd2_Sts 0 "Disable" 1 "Enable";
VAL_ 1468 Enable_ClimateSchd1_Sts 0 "Disable" 1 "Enable";
VAL_ 1468 ClimateSchd2_Departure_Min_Sts 15 "SNA";
VAL_ 1468 ClimateSchd2_Departure_Hr_Sts 31 "SNA";
VAL_ 1468 ClimateSchd2_Day_Sts 0 "No Selection" 1 "M" 2 "T" 3 "TM" 4 "W" 5 "WM" 6 "WT" 7 "WTM" 8 "Th" 9 "ThM" 10 "ThT" 11 "ThTM" 12 "ThW" 13 "ThWM" 14 "ThWT" 15 "ThWTM" 16 "F" 17 "FM" 18 "FT" 19 "FTM" 20 "FW" 21 "FWM" 22 "FWT" 23 "FWTM" 24 "FTh" 25 "FThM" 26 "FThT" 27 "FThTM" 28 "FThW" 29 "FThWM" 30 "FThWT" 31 "FThWTM" 32 "S" 33 "SM" 34 "ST" 35 "STM" 36 "SW" 37 "SWM" 38 "SWT" 39 "SWTM" 40 "STh" 41 "SThM" 42 "SThT" 43 "SThTM" 44 "SThW" 45 "SThWM" 46 "SThWT" 47 "SThWTM" 48 "SF" 49 "SFM" 50 "SFT" 51 "SFTM" 52 "SFW" 53 "SFWM" 54 "SFWT" 55 "SFWTM" 56 "SFTh" 57 "SFThM" 58 "SFThT" 59 "SFThTM" 60 "SFThW" 61 "SFThWM" 62 "SFThWT" 63 "SFThWTM" 64 "Su" 65 "SuM" 66 "SuT" 67 "SuTM" 68 "SuW" 69 "SuWM" 70 "SuWT" 71 "SuWTM" 72 "SuTh" 73 "SuThM" 74 "SuThT" 75 "SuThTM" 76 "SuThW" 77 "SuThWM" 78 "SuThWT" 79 "SuThWTM" 80 "SuF" 81 "SuFM" 82 "SuFT" 83 "SuFTM" 84 "SuFW" 85 "SuFWM" 86 "SuFWT" 87 "SuFWTM" 88 "SuFTh" 89 "SuFThM" 90 "SuFThT" 91 "SuFThTM" 92 "SuFThW" 93 "SuFThWM" 94 "SuFThWT" 95 "SuFThWTM" 96 "SuS" 97 "SuSM" 98 "SuST" 99 "SuSTM" 100 "SuSW" 101 "SuSWM" 102 "SuSWT" 103 "SuSWTM" 104 "SuSTh" 105 "SuSThM" 106 "SuSThT" 107 "SuSThTM" 108 "SuSThW" 109 "SuSThWM" 110 "SuSThWT" 111 "SuSThWTM" 112 "SuSF" 113 "SuSFM" 114 "SuSFT" 115 "SuSFTM" 116 "SuSFW" 117 "SuSFWM" 118 "SuSFWT" 119 "SuSFWTM" 120 "SuSFTh" 121 "SuSFThM" 122 "SuSFThT" 123 "SuSFThTM" 124 "SuSFThW" 125 "SuSFThWM" 126 "SuSFThWT" 127 "SuSFThWTM" 255 "SNA";
VAL_ 1468 ClimateSchd1_Departure_Min_Sts 15 "SNA";
VAL_ 1468 ClimateSchd1_Departure_Hr_Sts 31 "SNA";
VAL_ 2654339257 CurrentCanNMState_FD09_WCPM2 0 "Uninitialized State" 1 "Bus-Sleep State" 2 "Prepare-Bus State" 3 "Ready-Sleep State" 4 "Normal Operation State" 5 "Repeat Message State" 6 "Synchronize State" 7 "Offline State";
VAL_ 1474 TSI_Offset_Mph 0 "0" 1 "1" 2 "2" 3 "3" 4 "4" 5 "5" 6 "6" 7 "7" 8 "8" 9 "9" 10 "10";
VAL_ 1474 TSI_Offset_Kph 0 "0" 1 "1" 2 "2" 3 "3" 4 "4" 5 "5" 6 "6" 7 "7" 8 "8" 9 "9" 10 "10" 11 "11" 12 "12" 13 "13" 14 "14" 15 "15";
VAL_ 1474 ParkSenseSignalView 0 "DISABLE" 1 "ENABLE";
VAL_ 1474 FOA_Alert_Type 0 "Off" 1 "Cluster_Warning" 2 "Cluster_SMS_Warning";
VAL_ 1468 ClimateSchd1_Day_Sts 0 "No Selection" 1 "M" 2 "T" 3 "TM" 4 "W" 5 "WM" 6 "WT" 7 "WTM" 8 "Th" 9 "ThM" 10 "ThT" 11 "ThTM" 12 "ThW" 13 "ThWM" 14 "ThWT" 15 "ThWTM" 16 "F" 17 "FM" 18 "FT" 19 "FTM" 20 "FW" 21 "FWM" 22 "FWT" 23 "FWTM" 24 "FTh" 25 "FThM" 26 "FThT" 27 "FThTM" 28 "FThW" 29 "FThWM" 30 "FThWT" 31 "FThWTM" 32 "S" 33 "SM" 34 "ST" 35 "STM" 36 "SW" 37 "SWM" 38 "SWT" 39 "SWTM" 40 "STh" 41 "SThM" 42 "SThT" 43 "SThTM" 44 "SThW" 45 "SThWM" 46 "SThWT" 47 "SThWTM" 48 "SF" 49 "SFM" 50 "SFT" 51 "SFTM" 52 "SFW" 53 "SFWM" 54 "SFWT" 55 "SFWTM" 56 "SFTh" 57 "SFThM" 58 "SFThT" 59 "SFThTM" 60 "SFThW" 61 "SFThWM" 62 "SFThWT" 63 "SFThWTM" 64 "Su" 65 "SuM" 66 "SuT" 67 "SuTM" 68 "SuW" 69 "SuWM" 70 "SuWT" 71 "SuWTM" 72 "SuTh" 73 "SuThM" 74 "SuThT" 75 "SuThTM" 76 "SuThW" 77 "SuThWM" 78 "SuThWT" 79 "SuThWTM" 80 "SuF" 81 "SuFM" 82 "SuFT" 83 "SuFTM" 84 "SuFW" 85 "SuFWM" 86 "SuFWT" 87 "SuFWTM" 88 "SuFTh" 89 "SuFThM" 90 "SuFThT" 91 "SuFThTM" 92 "SuFThW" 93 "SuFThWM" 94 "SuFThWT" 95 "SuFThWTM" 96 "SuS" 97 "SuSM" 98 "SuST" 99 "SuSTM" 100 "SuSW" 101 "SuSWM" 102 "SuSWT" 103 "SuSWTM" 104 "SuSTh" 105 "SuSThM" 106 "SuSThT" 107 "SuSThTM" 108 "SuSThW" 109 "SuSThWM" 110 "SuSThWT" 111 "SuSThWTM" 112 "SuSF" 113 "SuSFM" 114 "SuSFT" 115 "SuSFTM" 116 "SuSFW" 117 "SuSFWM" 118 "SuSFWT" 119 "SuSFWTM" 120 "SuSFTh" 121 "SuSFThM" 122 "SuSFThT" 123 "SuSFThTM" 124 "SuSFThW" 125 "SuSFThWM" 126 "SuSFThWT" 127 "SuSFThWTM" 255 "SNA";
VAL_ 1468 Climate_Cabin_Temp2_Sts 31 "SNA";
VAL_ 1468 Climate_Cabin_Temp1_Sts 31 "SNA";
VAL_ 1468 AllowClimateSchd2_Sts 0 "Any_Time " 1 "Plugged_In_Only" 2 "Plugged_In_and_In_Charge_Schd" 3 "SNA";
VAL_ 1468 AllowClimateSchd1_Sts 0 "Any_Time " 1 "Plugged_In_Only" 2 "Plugged_In_and_In_Charge_Schd" 3 "SNA";
VAL_ 105 LidOpeningAck 0 "INIT" 1 "OK" 2 "KO" 3 "SNA";
VAL_ 105 LidClosingAck 0 "INIT" 1 "OK" 2 "KO" 3 "SNA";
VAL_ 1426 VDCM_PopUpMessage7 0 "Not_Active" 1 "Active";
VAL_ 1426 Est_Range_ChrgStopTime 2047 "SNA";
VAL_ 1426 Est_HVBatSOC_VDCM 255 "SNA";
VAL_ 1853 APM_OutputPower 1023 "SNA";
VAL_ 1853 APM_FailureReason 0 "No_Failure" 1 "Fail_high_voltage_at_HV" 2 "Fail_low_voltage_at_HV" 3 "Fail_high_voltage_at_LV" 4 "Fail_low_voltage_at_LV" 5 "Fail_high_PCB_temperature" 6 "Fail_high_DCB_temperature" 7 "Fail_high_cur_at_LV" 8 "Fail_high_cur_at_HV" 9 "Fail_short_circ_at_LV" 10 "Fail_short_circ_at_HV" 11 "Fail_open_circ_at_LV" 12 "Fail_open_circ_at_HV" 13 "Fail_init_failure" 14 "Fail_wake_up_issue" 15 "Fail_internal_hardware" 16 "Fail_bat_feed_low" 17 "Fail_bat_feed_high" 18 "Fail_Aux_OV" 19 "Fail_Aux_UV" 20 "Fail_HVIL_fault" 21 "Fail_LOC_with_HCP" 22 "Fail_LOC_with_BPCM" 23 "Fail_cont_not_closed" 24 "Fail_SBC_fault" 25 "Memory_Fail" 26 "Implausible_data_from_HCP" 27 "Implausible_data_from_BPCM" 28 "CAN_bus_off" 29 "Fail_temp_diff_is_high" 30 "Fail_high_voltage_diff_is_high" 31 "Fail_for_other_reason" 32 "LOC_ORC" 33 "Implausble_data_ORC" 63 "SNA";
VAL_ 1853 APM_CtrlSts_Fbk 0 "IDLE" 1 "Buck_CV_voltage" 2 "Buck_CC_current_control" 3 "APM_Temporary_Fault" 4 "Buck_Special" 6 "PreCharge" 7 "DisCharge" 8 "OFF" 9 "Derating" 10 "APM_Critical_Fault" 15 "SNA";
VAL_ 1440 ETM_HUD_Zone5_Expanded 0 "Blank_Zone" 1 "Speedometer" 2 "Speed_Limit_Sign" 3 "Turn_By_Turn" 4 "Gear_Display" 5 "ACC_Cruise_Control" 6 "Phone" 7 "Battery_Voltage" 8 "Coolant_Temperature" 9 "Tire_Pressure" 10 "Trailer_Tire_Pressure" 11 "Longitude_and_Latitude" 12 "Altitude" 13 "Trailer_Odometer" 14 "Drive_Mode" 15 "Air_Suspension" 16 "Tow_Haul_Mode" 17 "Oil_Temperature" 18 "Trans_Oil_Temperature" 19 "Pitch" 20 "Roll" 21 "Steering_Angle" 22 "Timer_60ft" 23 "Timer_330ft" 24 "Eighth_Mile_Timer" 25 "Timer_1000ft" 26 "Quarter_Mile_Timer" 27 "Timer_60MPH" 28 "Timer_100MPH" 29 "Wheel_Articulation" 30 "GForce" 31 "Tachometer" 32 "Shift_Light" 33 "Oil_Pressure" 34 "Electronic_Range_Select" 63 "SNA";
VAL_ 1440 ETM_HUD_Zone4_Expanded 0 "Blank_Zone" 1 "Speedometer" 2 "Speed_Limit_Sign" 3 "Turn_By_Turn" 4 "Gear_Display" 5 "ACC_Cruise_Control" 6 "Phone" 7 "Battery_Voltage" 8 "Coolant_Temperature" 9 "Tire_Pressure" 10 "Trailer_Tire_Pressure" 11 "Longitude_and_Latitude" 12 "Altitude" 13 "Trailer_Odometer" 14 "Drive_Mode" 15 "Air_Suspension" 16 "Tow_Haul_Mode" 17 "Oil_Temperature" 18 "Trans_Oil_Temperature" 19 "Pitch" 20 "Roll" 21 "Steering_Angle" 22 "Timer_60ft" 23 "Timer_330ft" 24 "Eighth_Mile_Timer" 25 "Timer_1000ft" 26 "Quarter_Mile_Timer" 27 "Timer_60MPH" 28 "Timer_100MPH" 29 "Wheel_Articulation" 30 "GForce" 31 "Tachometer" 32 "Shift_Light" 33 "Oil_Pressure" 34 "Electronic_Range_Select" 63 "SNA";
VAL_ 1440 ETM_HUD_Zone3_Expanded 0 "Blank_Zone" 1 "Speedometer" 2 "Speed_Limit_Sign" 3 "Turn_By_Turn" 4 "Gear_Display" 5 "ACC_Cruise_Control" 6 "Phone" 7 "Battery_Voltage" 8 "Coolant_Temperature" 9 "Tire_Pressure" 10 "Trailer_Tire_Pressure" 11 "Longitude_and_Latitude" 12 "Altitude" 13 "Trailer_Odometer" 14 "Drive_Mode" 15 "Air_Suspension" 16 "Tow_Haul_Mode" 17 "Oil_Temperature" 18 "Trans_Oil_Temperature" 19 "Pitch" 20 "Roll" 21 "Steering_Angle" 22 "Timer_60ft" 23 "Timer_330ft" 24 "Eighth_Mile_Timer" 25 "Timer_1000ft" 26 "Quarter_Mile_Timer" 27 "Timer_60MPH" 28 "Timer_100MPH" 29 "Wheel_Articulation" 30 "GForce" 31 "Tachometer" 32 "Shift_Light" 33 "Oil_Pressure" 34 "Electronic_Range_Select" 63 "SNA";
VAL_ 1440 ETM_HUD_Zone2_Expanded 0 "Blank_Zone" 1 "Speedometer" 2 "Speed_Limit_Sign" 3 "Turn_By_Turn" 4 "Gear_Display" 5 "ACC_Cruise_Control" 6 "Phone" 7 "Battery_Voltage" 8 "Coolant_Temperature" 9 "Tire_Pressure" 10 "Trailer_Tire_Pressure" 11 "Longitude_and_Latitude" 12 "Altitude" 13 "Trailer_Odometer" 14 "Drive_Mode" 15 "Air_Suspension" 16 "Tow_Haul_Mode" 17 "Oil_Temperature" 18 "Trans_Oil_Temperature" 19 "Pitch" 20 "Roll" 21 "Steering_Angle" 22 "Timer_60ft" 23 "Timer_330ft" 24 "Eighth_Mile_Timer" 25 "Timer_1000ft" 26 "Quarter_Mile_Timer" 27 "Timer_60MPH" 28 "Timer_100MPH" 29 "Wheel_Articulation" 30 "GForce" 31 "Tachometer" 32 "Shift_Light" 33 "Oil_Pressure" 34 "Electronic_Range_Select" 63 "SNA";
VAL_ 1440 ETM_HUD_Zone1_Expanded 0 "Blank_Zone" 1 "Speedometer" 2 "Speed_Limit_Sign" 3 "Turn_By_Turn" 4 "Gear_Display" 5 "ACC_Cruise_Control" 6 "Phone" 7 "Battery_Voltage" 8 "Coolant_Temperature" 9 "Tire_Pressure" 10 "Trailer_Tire_Pressure" 11 "Longitude_and_Latitude" 12 "Altitude" 13 "Trailer_Odometer" 14 "Drive_Mode" 15 "Air_Suspension" 16 "Tow_Haul_Mode" 17 "Oil_Temperature" 18 "Trans_Oil_Temperature" 19 "Pitch" 20 "Roll" 21 "Steering_Angle" 22 "Timer_60ft" 23 "Timer_330ft" 24 "Eighth_Mile_Timer" 25 "Timer_1000ft" 26 "Quarter_Mile_Timer" 27 "Timer_60MPH" 28 "Timer_100MPH" 29 "Wheel_Articulation" 30 "GForce" 31 "Tachometer" 32 "Shift_Light" 33 "Oil_Pressure" 34 "Electronic_Range_Select" 63 "SNA";
VAL_ 1474 TurnSignalView 0 "Disable" 1 "Enable" 2 "Only_with_Trailer";
VAL_ 1474 Fuel_Saver_Display 0 "Disable" 1 "Enable";
VAL_ 1474 EPB_Service_Mode 0 "Disable" 1 "Enable";
VAL_ 1442 SugSpeedThreshold 63 "SNA";
VAL_ 1442 SugSpeedMin 63 "SNA";
VAL_ 1442 SugSpeedMax 63 "SNA";
VAL_ 1442 AC_Charge_Button_Label5 255 "SNA";
VAL_ 1442 AC_Charge_Button_Label4 255 "SNA";
VAL_ 1442 AC_Charge_Button_Label3 255 "SNA";
VAL_ 1442 AC_Charge_Button_Label2 255 "SNA";
VAL_ 1442 AC_Charge_Button_Label1 255 "SNA";
VAL_ 1426 ServiceHVError 0 "No_Error" 1 "Error";
VAL_ 205 RearAxle_Min_Rq_BSM 0 "Not_Active" 1 "Active";
VAL_ 205 RearAxle_Max_Rq_BSM 0 "Not_Active" 1 "Active";
VAL_ 205 FrontAxle_Min_Rq_BSM 0 "Not_Active" 1 "Active";
VAL_ 205 FrontAxle_Max_Rq_BSM 0 "Not_Active" 1 "Active";
VAL_ 205 TotalAxle_Min_Rq_BSM 0 "Not_Active" 1 "Active";
VAL_ 205 TotalAxle_Max_Rq_BSM 0 "Not_Active" 1 "Active";
VAL_ 205 Regen_AxleTorque_Req 32767 "SNA";
VAL_ 205 DrvrIntd_TotalBrk_AxleTorq 32767 "SNA";
VAL_ 205 DriverReq_AxleTrq_Enabled_BSM 0 "No_Req" 1 "ACC_NCC" 2 "SSC" 3 "PPPA" 4 "RRCC" 15 "SNA";
VAL_ 205 Cmnd_TotBrkFrict_AxleTorq 32767 "SNA";
VAL_ 204 Rear_Axle_Regen_Capacity 16383 "SNA";
VAL_ 204 Rear_Axle_Est_Regen_Torq 16383 "SNA";
VAL_ 204 Front_Axle_Regen_Capacity 16383 "SNA";
VAL_ 204 Front_Axle_Est_Regen_Torq 16383 "SNA";
VAL_ 205 TotalAxle_Rq_BSM 65535 "SNA";
VAL_ 205 DriverRequested_AxleTrq_BSM 65535 "SNA";
VAL_ 204 Total_AxleTorque_Min 65535 "SNA";
VAL_ 204 Total_AxleTorque_Max 65535 "SNA";
VAL_ 204 Axle_TorqueStatic_D_TTC 65535 "SNA";
VAL_ 204 Axle_Torque_DrvReqMod 65535 "SNA";
VAL_ 1316 OffRd_RR_Lvl 510 "NOT_INIT" 511 "SNA";
VAL_ 1316 OffRd_RL_Lvl 510 "NOT_INIT" 511 "SNA";
VAL_ 1316 OffRd_FR_Lvl 510 "NOT_INIT" 511 "SNA";
VAL_ 1316 OffRd_FL_Lvl 510 "NOT_INIT" 511 "SNA";
VAL_ 204 Front_AxleTorque_Max 65535 "SNA";
VAL_ 1474 Creep 0 "Off" 1 "On";
VAL_ 205 RearAxle_Rq_BSM 65535 "SNA";
VAL_ 205 FrontAxle_Rq_BSM 65535 "SNA";
VAL_ 204 Rear_AxleTorque_Min 65535 "SNA";
VAL_ 204 Rear_AxleTorque_Max 65535 "SNA";
VAL_ 204 MaxRegen_Diff_Axle_Torq_Active 0 "Not_Active" 1 "Active";
VAL_ 204 MaxRegen_Diff_Axle_Torq 32767 "SNA";
VAL_ 204 Front_AxleTorque_Min 65535 "SNA";
VAL_ 1426 ThermalRunaway_Alert 0 "do_not_activate" 1 "activate";
VAL_ 1426 BatteryRunaway_Lamp_PT 0 "Lamp_not_active" 1 "Lamp_active";
VAL_ 2654339257 StayActiveSource_FD09_WCPM2 0 "CANNM_Ready_Sleep" 1 "IGN_ON" 2 "NonDefault_Diag" 4 "ING_OFF_NormSt_RptSt" 1073741824 "SASource_Not_Listed";
VAL_ 1474 StopOnTraffic 0 "Off" 1 "Warning" 2 "Warning_and_Auto_Stop";
VAL_ 1474 SpeedAdjust 0 "Warning_only" 1 "Warning_and_Speed_adjust";
VAL_ 1474 RouteGuidance 0 "Off" 1 "On";
VAL_ 1474 EmergencyCorridorAssist 0 "Off" 1 "On";
SIG_GROUP_ 1426 VDCM_HMI_Pkt 1 : VDCM_PopUpMessage5 EstRange DC_EstChargeTime2 DC_EstChargeTime1 VDCM_PopUpMessage7 Est_Range_ChrgStopTime Est_HVBatSOC_VDCM ServiceHVError ThermalRunaway_Alert MessageCounter_VDCM_HMI CRC_VDCM_HMI BatteryRunaway_Lamp_PT;
SIG_GROUP_ 205 BRAKE_FD_6_Pkt 1 : CRC_BRAKE_FD_6 MessageCounter_BRAKE_FD_6 RearAxle_Min_Rq_BSM RearAxle_Max_Rq_BSM FrontAxle_Min_Rq_BSM FrontAxle_Max_Rq_BSM TotalAxle_Min_Rq_BSM TotalAxle_Max_Rq_BSM Regen_AxleTorque_Req DrvrIntd_TotalBrk_AxleTorq DriverReq_AxleTrq_Enabled_BSM Cmnd_TotBrkFrict_AxleTorq TotalAxle_Rq_BSM DriverRequested_AxleTrq_BSM RearAxle_Rq_BSM FrontAxle_Rq_BSM WED_MODE_RQ OPD_Hold_Status;
SIG_GROUP_ 204 AXLE_TORQUE_FD_1_Pkt 1 : MessageCounter_AXLE_TORQUE_FD_1 CRC_AXLE_TORQUE_FD_1 Rear_Axle_Regen_Capacity Rear_Axle_Est_Regen_Torq Front_Axle_Regen_Capacity Front_Axle_Est_Regen_Torq Total_AxleTorque_Min Total_AxleTorque_Max Axle_TorqueStatic_D_TTC Axle_Torque_DrvReqMod Rear_AxleTorque_Min Rear_AxleTorque_Max MaxRegen_Diff_Axle_Torq_Active MaxRegen_Diff_Axle_Torq Front_AxleTorque_Min Front_AxleTorque_Max;
